VERSION "created by canmatrix"

NS_ :

BS_:

BU_: TCM iBooster HCU CIM SCM Right_Hand_Control Left_Hand_Control GPS VCM IC_2 XM GMRS Radio_CANtool Diagnostic_Tool_Digital_Wrench Information_System_Controller_1 STEERING_CONTROLLER VEHICLE_SECURITY RADIO_Hub ABS Battery_Management_Cntrl_2 Battery_Management_Cntrl_1 Auxiliary_Power_Unit_2 Auxiliary_Power_Unit_1 Electric_Propulsion_Cntrl_Unit_4 Electric_Propulsion_Cntrl_Unit_3 Electric_Propulsion_Cntrl_Unit_2 Electric_Propulsion_Cntrl_Unit_1 ECM IC

BO_ 3221225472 VECTOR__INDEPENDENT_SIG_MSG: 0 Vector__XXX
 SG_ pEPS_SAScalibrated : 0|2@1+ (1,0) [0.0|3.0] "" Vector__XXX
 SG_ pEPS_OpStatus : 0|3@1+ (1,0) [0.0|7.0] "" Vector__XXX
 SG_ pEPS_OpMode : 0|8@1+ (1,0) [0.0|255.0] "" Vector__XXX
 SG_ pEPS_ShaftVelocity : 0|16@1+ (0.1,-3276.5) [-3276.5|3276.5] "deg/s" Vector__XXX
 SG_ pEPS_ShaftPosition : 0|16@1+ (0.1,-3276.5) [-3276.5|3276.5] "deg" Vector__XXX
 SG_ DM_SPN2 : 0|8@1+ (1,0) [0.0|255.0] "" Vector__XXX
 SG_ DM_SPN3 : 0|3@1+ (1,0) [0.0|7.0] "" Vector__XXX
 SG_ DM_SPN1 : 0|8@1+ (1,0) [0.0|255.0] "" Vector__XXX
 SG_ DM_FailureModeIdentifier : 0|5@1+ (1,0) [0.0|0.0] "" Vector__XXX
 SG_ DM_SPNConversionMethod : 0|1@1+ (1,0) [0.0|1.0] "" Vector__XXX
 SG_ DM_OccurenceCount : 0|7@1+ (1,0) [0.0|126.0] "" Vector__XXX

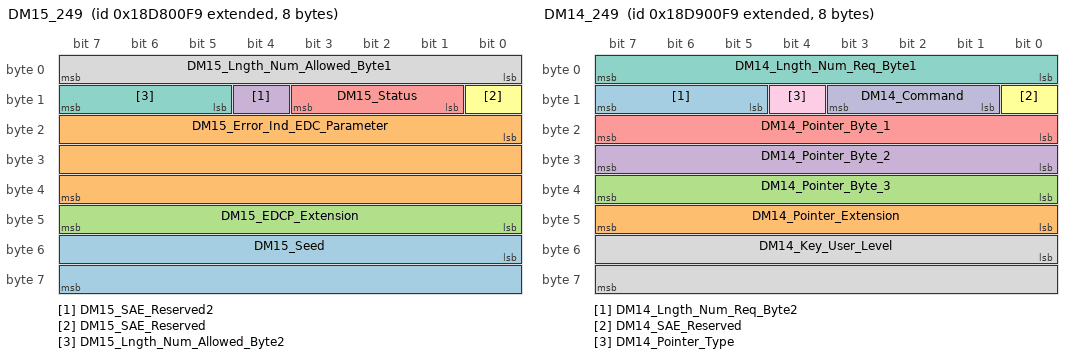
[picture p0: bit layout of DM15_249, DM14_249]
BO_ 2564292857 DM15_249: 8 Diagnostic_Tool_Digital_Wrench
 SG_ DM15_Seed : 48|16@1+ (1,0) [0.0|65535.0] "" Vector__XXX
 SG_ DM15_Error_Ind_EDC_Parameter : 16|24@1+ (1,0) [0.0|16777215.0] "" Vector__XXX
 SG_ DM15_EDCP_Extension : 40|8@1+ (1,0) [0.0|255.0] "" Vector__XXX
 SG_ DM15_SAE_Reserved2 : 12|1@1+ (1,0) [1.0|1.0] "" Vector__XXX
 SG_ DM15_Status : 9|3@1+ (1,0) [0.0|7.0] "" Vector__XXX
 SG_ DM15_SAE_Reserved : 8|1@1+ (1,0) [1.0|1.0] "" Vector__XXX
 SG_ DM15_Lngth_Num_Allowed_Byte2 : 13|3@1+ (1,0) [0.0|7.0] "" Vector__XXX
 SG_ DM15_Lngth_Num_Allowed_Byte1 : 0|8@1+ (1,0) [0.0|255.0] "" Vector__XXX

BO_ 2564358393 DM14_249: 8 Diagnostic_Tool_Digital_Wrench
 SG_ DM14_Lngth_Num_Req_Byte2 : 13|3@1+ (1,0) [0.0|7.0] "" Vector__XXX
 SG_ DM14_Pointer_Extension : 40|8@1+ (1,0) [0.0|255.0] "" Vector__XXX
 SG_ DM14_Pointer_Byte_3 : 32|8@1+ (1,0) [0.0|255.0] "" Vector__XXX
 SG_ DM14_Pointer_Byte_2 : 24|8@1+ (1,0) [0.0|255.0] "" Vector__XXX
 SG_ DM14_Pointer_Byte_1 : 16|8@1+ (1,0) [0.0|255.0] "" Vector__XXX
 SG_ DM14_SAE_Reserved : 8|1@1+ (1,0) [1.0|1.0] "" Vector__XXX
 SG_ DM14_Lngth_Num_Req_Byte1 : 0|8@1+ (1,0) [0.0|255.0] "" Vector__XXX
 SG_ DM14_Key_User_Level : 48|16@1+ (1,0) [0.0|65535.0] "" Vector__XXX
 SG_ DM14_Pointer_Type : 12|1@1+ (1,0) [0.0|1.0] "" Vector__XXX
 SG_ DM14_Command : 9|3@1+ (1,0) [0.0|7.0] "" Vector__XXX

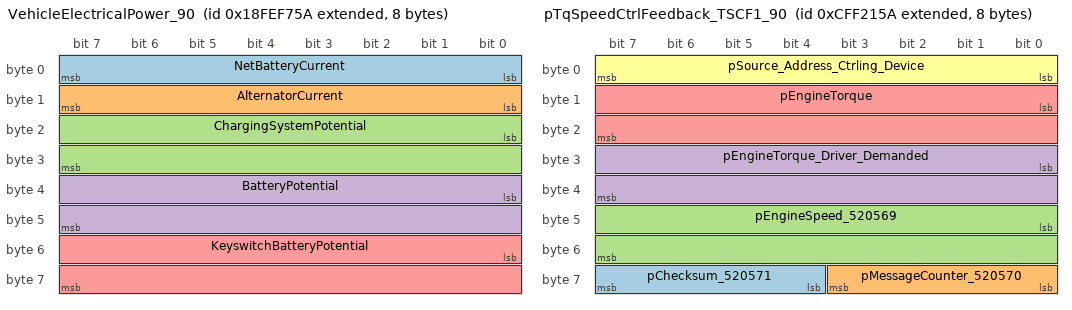
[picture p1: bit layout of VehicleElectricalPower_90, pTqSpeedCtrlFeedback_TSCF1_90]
BO_ 2566846298 VehicleElectricalPower_90: 8 HCU
 SG_ NetBatteryCurrent : 0|8@1+ (1,-125) [-125.0|125.0] "A" Vector__XXX
 SG_ AlternatorCurrent : 8|8@1+ (1,0) [0.0|250.0] "A" Vector__XXX
 SG_ ChargingSystemPotential : 16|16@1+ (0.05,0) [0.0|3212.75] "V" Vector__XXX
 SG_ BatteryPotential : 32|16@1+ (0.05,0) [0.0|3212.75] "V" Vector__XXX
 SG_ KeyswitchBatteryPotential : 48|16@1+ (0.05,0) [0.0|3212.75] "V" Vector__XXX

BO_ 2633984602 pDriveSystemStatus_90: 8 HCU
 SG_ pHeatedGripEnable : 48|2@1+ (1,0) [0.0|3.0] "" Vector__XXX
 SG_ pSideStandStatus : 36|2@1+ (1,0) [0.0|3.0] "" Vector__XXX
 SG_ pTetherSwitchStatus : 46|2@1+ (1,0) [0.0|3.0] "" Vector__XXX
 SG_ pLowFuelIndicatorStatus : 10|2@1+ (1,0) [0.0|3.0] "" Vector__XXX
 SG_ pOperatorNotInOperatingStation : 38|2@1+ (1,0) [0.0|3.0] "" Vector__XXX
 SG_ pParkBrakeIndicatorStatus : 40|3@1+ (1,0) [0.0|7.0] "" Vector__XXX
 SG_ pADCRequested : 34|2@1+ (1,0) [0.0|3.0] "" Vector__XXX
 SG_ pAWDModeRequested : 32|2@1+ (1,0) [0.0|3.0] "" Vector__XXX
 SG_ pRWDModeRequested : 30|2@1+ (1,0) [0.0|3.0] "" Vector__XXX
 SG_ pTurfModeRequested : 28|2@1+ (1,0) [0.0|3.0] "" Vector__XXX
 SG_ pADCStatus : 0|2@1+ (1,0) [0.0|3.0] "" Vector__XXX
 SG_ pTreadleNeutralStatus : 2|2@1+ (1,0) [0.0|3.0] "" Vector__XXX
 SG_ pTreadleReverseStatus : 4|2@1+ (1,0) [0.0|3.0] "" Vector__XXX
 SG_ pSecurityLightStatus : 6|2@1+ (1,0) [0.0|3.0] "" Vector__XXX
 SG_ pHighBeamIndicatorStatus : 8|2@1+ (1,0) [0.0|3.0] "" Vector__XXX
 SG_ pHeatedGripsPercentage : 16|8@1+ (0.4,0) [0.0|100.0] "%" Vector__XXX
 SG_ pCruiseControlSetStatus : 24|2@1+ (1,0) [0.0|3.0] "" Vector__XXX
 SG_ pSeatBeltIndicatorStatus : 12|3@1+ (1,0) [0.0|7.0] "" Vector__XXX

BO_ 2365530458 pTqSpeedCtrlFeedback_TSCF1_90: 8 HCU
 SG_ pChecksum_520571 : 60|4@1+ (1,0) [0.0|15.0] "" Vector__XXX
 SG_ pMessageCounter_520570 : 56|4@1+ (1,0) [0.0|15.0] "" Vector__XXX
 SG_ pEngineSpeed_520569 : 40|16@1+ (1,0) [0.0|64255.0] "rpm" Vector__XXX
 SG_ pEngineTorque_Driver_Demanded : 24|16@1- (0.03125,0) [-400.0|1607.96875] "Nm" Vector__XXX
 SG_ pEngineTorque : 8|16@1- (0.03125,0) [-400.0|1607.96875] "Nm" Vector__XXX
 SG_ pSource_Address_Ctrling_Device : 0|8@1+ (1,0) [0.0|255.0] "Source Address" Vector__XXX

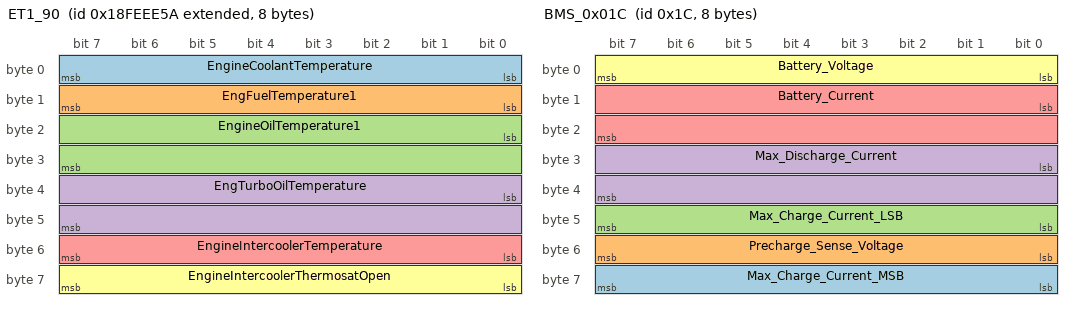
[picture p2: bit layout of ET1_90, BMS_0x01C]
BO_ 2566843994 ET1_90: 8 HCU
 SG_ EngineCoolantTemperature : 0|8@1+ (1,-40) [-40.0|210.0] "°C" Vector__XXX
 SG_ EngFuelTemperature1 : 8|8@1+ (1,-40) [-40.0|210.0] "°C" Vector__XXX
 SG_ EngineOilTemperature1 : 16|16@1+ (0.03125,-273) [-273.0|1734.96875] "°C" Vector__XXX
 SG_ EngTurboOilTemperature : 32|16@1+ (0.03125,-273) [-273.0|1734.96875] "°C" Vector__XXX
 SG_ EngineIntercoolerTemperature : 48|8@1+ (1,-40) [-40.0|210.0] "°C" Vector__XXX
 SG_ EngineIntercoolerThermosatOpen : 56|8@1+ (0.4,0) [0.0|100.0] "%" Vector__XXX

BO_ 2566841690 EngineHoursRevolutions_90: 8 HCU
 SG_ EngTotalHoursOfOper : 0|32@1+ (0.05,0) [0.0|210554060.75] "h" Vector__XXX
 SG_ TotalEngineRevolutions : 32|32@1+ (1000,0) [0.0|4211081215000.0] "r" Vector__XXX

BO_ 2566876762 pVF1_90: 8 HCU
 SG_ pEngineOilPressureStatus : 4|2@1+ (1,0) [0.0|3.0] "" Vector__XXX
 SG_ pHydraulicOilPressureStatus : 2|2@1+ (1,0) [0.0|3.0] "" Vector__XXX
 SG_ pHydraulicOilTempStatus : 0|2@1+ (1,0) [0.0|3.0] "" Vector__XXX

BO_ 2566876672 pVF1_00: 8 ECM
 SG_ pEngineOilPressureStatus : 4|2@1+ (1,0) [0.0|3.0] "" Vector__XXX
 SG_ pHydraulicOilPressureStatus : 2|2@1+ (1,0) [0.0|3.0] "" Vector__XXX
 SG_ pHydraulicOilTempStatus : 0|2@1+ (1,0) [0.0|3.0] "" Vector__XXX

BO_ 27 BMS_0x01B: 8 Battery_Management_Cntrl_1
 SG_ Battery_Relative_SOC : 0|8@1+ (1,0) [0.0|0.0] "%" Vector__XXX
 SG_ BMS_Mode : 8|2@1+ (1,0) [0.0|0.0] "1" Vector__XXX

BO_ 28 BMS_0x01C: 8 Battery_Management_Cntrl_1
 SG_ Max_Charge_Current_MSB : 56|8@1+ (1,0) [0.0|0.0] "A" Vector__XXX
 SG_ Precharge_Sense_Voltage : 48|8@1+ (1,0) [0.0|0.0] "V" Vector__XXX
 SG_ Max_Charge_Current_LSB : 40|8@1+ (1,0) [0.0|0.0] "A" Vector__XXX
 SG_ Max_Discharge_Current : 24|16@1+ (1,0) [0.0|0.0] "A" Vector__XXX
 SG_ Battery_Current : 8|16@1+ (1,-32768) [0.0|0.0] "A" Vector__XXX
 SG_ Battery_Voltage : 0|8@1+ (1,0) [0.0|0.0] "V" Vector__XXX

BO_ 2365553933 pRemoteBrakeControl1_13: 8 iBooster
 SG_ Checksum : 56|8@1+ (1,0) [0.0|255.0] "Count" Vector__XXX
 SG_ MessageCounter : 52|4@1- (1,0) [-8.0|7.0] "Count" Vector__XXX
 SG_ pActualBrakingApplication : 8|8@1+ (0.4,0) [0.0|100.0] "%" Vector__XXX
 SG_ pRequestedBrakingApplication : 0|8@1+ (0.4,0) [0.0|100.0] "%" Vector__XXX

BO_ 2348941059 TC1_03: 8 TCM
 SG_ TrsmRequestedGear_525 : 16|8@1+ (1,0) [0.0|0.0] "" Vector__XXX
 SG_ TrsmGearShiftInhibitReq_681 : 0|2@1+ (1,0) [0.0|0.0] "" Vector__XXX

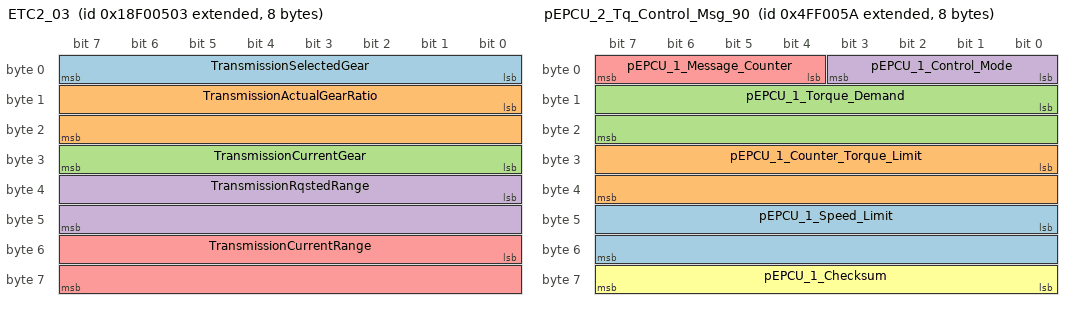
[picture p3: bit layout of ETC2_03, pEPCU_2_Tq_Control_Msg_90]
BO_ 2565866755 ETC2_03: 8 TCM
 SG_ TransmissionSelectedGear : 0|8@1+ (1,-125) [-125.0|125.0] "" Vector__XXX
 SG_ TransmissionActualGearRatio : 8|16@1+ (0.001,0) [0.0|64.255] "" Vector__XXX
 SG_ TransmissionCurrentGear : 24|8@1+ (1,-125) [-125.0|125.0] "" Vector__XXX
 SG_ TransmissionRqstedRange : 32|16@1+ (1,0) [0.0|65535.0] "" Vector__XXX
 SG_ TransmissionCurrentRange : 48|16@1+ (1,0) [0.0|65535.0] "" Vector__XXX

BO_ 2364539395 ElectronicTrsmController1_03: 8 TCM
 SG_ TrsmShiftInProcess_574 : 4|2@1+ (1,0) [0.0|0.0] "" Vector__XXX

BO_ 2566844675 CruiseControlVehSpeed_3: 8 TCM
 SG_ pCruiseCntrlCounter : 50|4@1+ (1,0) [0.0|15.0] "" Vector__XXX
 SG_ TwoSpeedAxleSwitch : 0|2@1+ (1,0) [0.0|3.0] "" Vector__XXX
 SG_ ParkingBrakeSwitch : 2|2@1+ (1,0) [0.0|3.0] "" Vector__XXX
 SG_ Wheel_BasedVehicleSpeed : 8|16@1+ (0.00390625,0) [0.0|251.0] "km/h" Vector__XXX
 SG_ CruiseCtrlActive : 24|2@1+ (1,0) [0.0|3.0] "" Vector__XXX
 SG_ CruiseCtrlEnableSwitch : 26|2@1+ (1,0) [0.0|3.0] "" Vector__XXX
 SG_ BrakeSwitch : 28|2@1+ (1,0) [0.0|3.0] "" Vector__XXX
 SG_ ClutchSwitch : 30|2@1+ (1,0) [0.0|3.0] "" Vector__XXX
 SG_ CruiseCtrlSetSwitch : 32|2@1+ (1,0) [0.0|3.0] "" Vector__XXX
 SG_ CruiseCtrlCoastSwitch : 34|2@1+ (1,0) [0.0|3.0] "" Vector__XXX
 SG_ CruiseCtrlResumeSwitch : 36|2@1+ (1,0) [0.0|3.0] "" Vector__XXX
 SG_ CruiseCtrlAccelerateSwitch : 38|2@1+ (1,0) [0.0|3.0] "" Vector__XXX
 SG_ CruiseCtrlSetSpeed : 40|8@1+ (1,0) [0.0|250.0] "km/h" Vector__XXX
 SG_ pOdometerDriveBit : 6|2@1+ (1,0) [0.0|3.0] "" Vector__XXX
 SG_ CruiseCtrlPauseSw : 4|2@1+ (1,0) [0.0|3.0] "" Vector__XXX
 SG_ pCCChecksum : 56|8@1+ (1,0) [0.0|255.0] "" Vector__XXX
 SG_ pCruiseEnableStatus : 48|4@1+ (1,0) [0.0|15.0] "" Vector__XXX

BO_ 2566841344 SHUTDN_00: 8 ECM
 SG_ Engine_Wait_to_Start_Lamp_1081 : 24|2@1+ (1,0) [0.0|0.0] "" Vector__XXX

BO_ 2231304282 pEPCU_2_Tq_Control_Msg_90: 8 HCU
 SG_ pEPCU_1_Speed_Limit : 40|16@1+ (1,-32768) [-32768.0|31488.0] "rpm" Vector__XXX
 SG_ pEPCU_1_Counter_Torque_Limit : 24|16@1+ (0.1,-3276.8) [-3276.8|3276.7] "Nm" Vector__XXX
 SG_ pEPCU_1_Torque_Demand : 8|16@1+ (0.1,-3276.8) [-3276.8|3276.7] "Nm" Vector__XXX
 SG_ pEPCU_1_Control_Mode : 0|4@1+ (1,0) [0.0|15.0] "" Vector__XXX
 SG_ pEPCU_1_Message_Counter : 4|4@1+ (1,0) [0.0|15.0] "" Vector__XXX
 SG_ pEPCU_1_Checksum : 56|8@1+ (1,0) [0.0|255.0] "" Vector__XXX

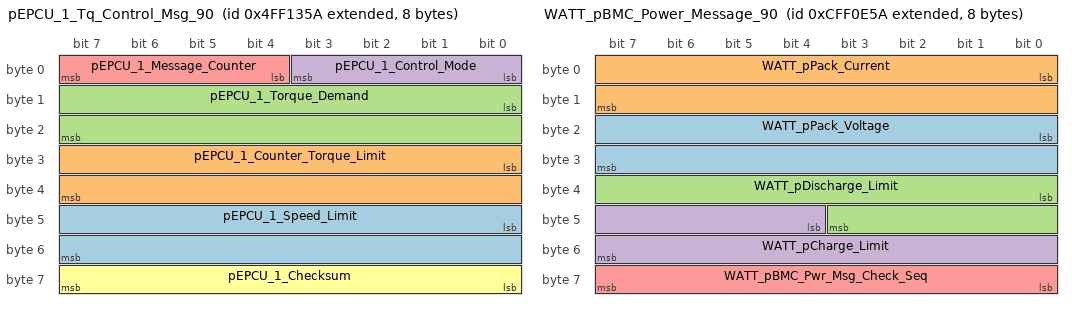
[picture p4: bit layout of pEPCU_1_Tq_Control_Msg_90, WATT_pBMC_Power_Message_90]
BO_ 2231309146 pEPCU_1_Tq_Control_Msg_90: 8 HCU
 SG_ pEPCU_1_Speed_Limit : 40|16@1+ (1,-32768) [-32768.0|31488.0] "rpm" Vector__XXX
 SG_ pEPCU_1_Counter_Torque_Limit : 24|16@1+ (0.1,-3276.8) [-3276.8|3276.7] "Nm" Vector__XXX
 SG_ pEPCU_1_Torque_Demand : 8|16@1+ (0.1,-3276.8) [-3276.8|3276.7] "Nm" Vector__XXX
 SG_ pEPCU_1_Control_Mode : 0|4@1+ (1,0) [0.0|15.0] "" Vector__XXX
 SG_ pEPCU_1_Message_Counter : 4|4@1+ (1,0) [0.0|15.0] "" Vector__XXX
 SG_ pEPCU_1_Checksum : 56|8@1+ (1,0) [0.0|255.0] "" Vector__XXX

BO_ 2365525594 WATT_pBMC_Power_Message_90: 8 HCU
 SG_ WATT_pPack_Voltage : 16|16@1+ (0.05,0) [0.0|3212.75] "V" Vector__XXX
 SG_ WATT_pPack_Current : 0|16@1+ (0.05,-1600) [-1600.0|1612.75] "A" Vector__XXX
 SG_ WATT_pDischarge_Limit : 32|12@1+ (0.5,0) [0.0|2007.5] "A" Vector__XXX
 SG_ WATT_pCharge_Limit : 44|12@1+ (0.5,0) [0.0|2007.5] "A" Vector__XXX
 SG_ WATT_pBMC_Pwr_Msg_Check_Seq : 56|8@1+ (1,0) [0.0|255.0] "" Vector__XXX

BO_ 2348941146 TC1_90: 8 HCU
 SG_ TrsmRequestedGear_525 : 16|8@1+ (1,0) [0.0|0.0] "" Vector__XXX
 SG_ TrsmGearShiftInhibitReq_681 : 0|2@1+ (1,0) [0.0|0.0] "" Vector__XXX

BO_ 2566841434 SHUTDN_90: 8 HCU
 SG_ Engine_Wait_to_Start_Lamp_1081 : 24|2@1+ (1,0) [0.0|0.0] "" Vector__XXX

BO_ 2566885722 RF3_RemoteFeedback3_90: 8 HCU
 SG_ pHybridPowertrainMode : 0|4@1+ (1,0) [0.0|0.0] "" Vector__XXX

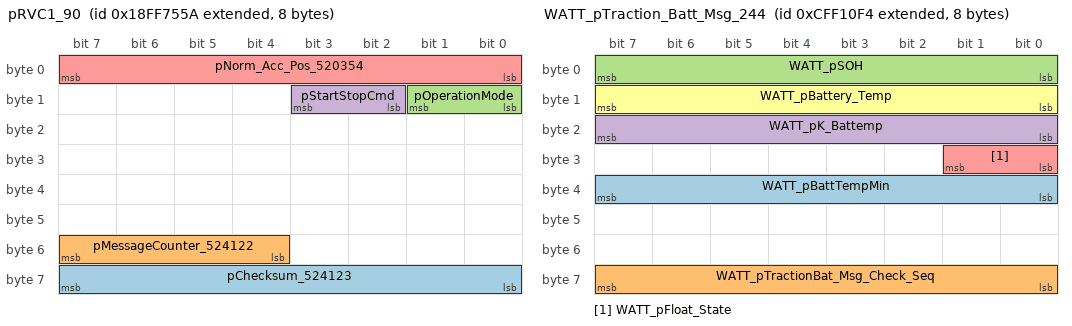
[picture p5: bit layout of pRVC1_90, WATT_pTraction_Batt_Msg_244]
BO_ 2566878554 pRVC1_90: 8 HCU
 SG_ pChecksum_524123 : 56|8@1+ (1,0) [0.0|255.0] "" Vector__XXX
 SG_ pMessageCounter_524122 : 52|4@1+ (1,0) [0.0|15.0] "" Vector__XXX
 SG_ pOperationMode : 8|2@1+ (1,0) [0.0|0.0] "" Vector__XXX
 SG_ pStartStopCmd : 10|2@1+ (1,0) [0.0|3.0] "" Vector__XXX
 SG_ pNorm_Acc_Pos_520354 : 0|8@1+ (0.4,0) [0.0|102.0] "Percent" Vector__XXX

BO_ 2566844762 CruiseControlVehSpeed_90: 8 HCU
 SG_ TwoSpeedAxleSwitch : 0|2@1+ (1,0) [0.0|3.0] "" Vector__XXX
 SG_ ParkingBrakeSwitch : 2|2@1+ (1,0) [0.0|3.0] "" Vector__XXX
 SG_ Wheel_BasedVehicleSpeed : 8|16@1+ (0.00390625,0) [0.0|251.0] "km/h" Vector__XXX
 SG_ CruiseCtrlActive : 24|2@1+ (1,0) [0.0|3.0] "" Vector__XXX
 SG_ CruiseCtrlEnableSwitch : 26|2@1+ (1,0) [0.0|3.0] "" Vector__XXX
 SG_ BrakeSwitch : 28|2@1+ (1,0) [0.0|3.0] "" Vector__XXX
 SG_ ClutchSwitch : 30|2@1+ (1,0) [0.0|3.0] "" Vector__XXX
 SG_ CruiseCtrlSetSwitch : 32|2@1+ (1,0) [0.0|3.0] "" Vector__XXX
 SG_ CruiseCtrlCoastSwitch : 34|2@1+ (1,0) [0.0|3.0] "" Vector__XXX
 SG_ CruiseCtrlResumeSwitch : 36|2@1+ (1,0) [0.0|3.0] "" Vector__XXX
 SG_ CruiseCtrlAccelerateSwitch : 38|2@1+ (1,0) [0.0|3.0] "" Vector__XXX
 SG_ CruiseCtrlSetSpeed : 40|8@1+ (1,0) [0.0|250.0] "km/h" Vector__XXX
 SG_ pOdometerDriveBit : 6|2@1+ (1,0) [0.0|3.0] "" Vector__XXX
 SG_ CruiseCtrlPauseSw : 4|2@1+ (1,0) [0.0|3.0] "" Vector__XXX
 SG_ pCCMessageCounter : 52|4@1+ (1,0) [0.0|15.0] "" Vector__XXX
 SG_ pCCChecksum : 56|8@1+ (1,0) [0.0|255.0] "" Vector__XXX
 SG_ pCruiseEnableStatus : 48|4@1+ (1,0) [0.0|15.0] "" Vector__XXX

BO_ 2566887489 pVehicleLoadInfo1_65: 6 Information_System_Controller_1
 SG_ pRiderWeightRearLeft : 32|8@1+ (1,0) [0.0|250.0] "kg" Vector__XXX
 SG_ pBoxLoadWeight : 48|8@1+ (10,0) [0.0|2400.0] "kg" Vector__XXX
 SG_ pRiderWeightRearRight : 40|8@1+ (1,0) [0.0|250.0] "kg" Vector__XXX
 SG_ pRiderWeightMidRight : 24|8@1+ (1,0) [0.0|250.0] "kg" Vector__XXX
 SG_ pRiderWeightMidLeft : 16|8@1+ (1,0) [0.0|250.0] "kg" Vector__XXX
 SG_ pRiderWeightFrontRight : 8|8@1+ (1,0) [0.0|250.0] "kg" Vector__XXX
 SG_ pRiderWeightFrontLeft : 0|8@1+ (1,0) [0.0|250.0] "kg" Vector__XXX

BO_ 2566853722 pWattMessage_90: 8 HCU
 SG_ pRangeToEmptyEV : 16|16@1+ (0.1,0) [0.0|6425.5] "km" Vector__XXX
 SG_ pEfficiencyEV : 0|16@1+ (0.1,0) [0.0|6425.5] "Wh/km" Vector__XXX

BO_ 2365554060 pRemoteBrakeControl1_140: 8 CIM
 SG_ Checksum : 56|8@1+ (1,0) [0.0|255.0] "Count" Vector__XXX
 SG_ MessageCounter : 52|4@1- (1,0) [-8.0|7.0] "Count" Vector__XXX
 SG_ pActualBrakingApplication : 8|8@1+ (0.4,0) [0.0|100.0] "%" Vector__XXX
 SG_ pRequestedBrakingApplication : 0|8@1+ (0.4,0) [0.0|100.0] "%" Vector__XXX

BO_ 2566877965 pRemoteSteeringControl1_13: 8 iBooster
 SG_ pEPS_CommandedVar2 : 48|16@1+ (0.1,-3276.5) [-3276.5|3276.5] "deg/s" Vector__XXX
 SG_ pEPS_CommandedVar1 : 32|16@1+ (0.1,-3276.5) [-3276.5|3276.5] "deg" Vector__XXX
 SG_ pEPS_OpModeCommanded : 0|8@1+ (1,0) [0.0|255.0] "" Vector__XXX

BO_ 2365526260 WATT_pTraction_Batt_Msg_244: 8 Battery_Management_Cntrl_2
 SG_ WATT_pBattTempMin : 32|8@1+ (1,-40) [-40.0|200.0] "deg C" Vector__XXX
 SG_ WATT_pTractionBat_Msg_Check_Seq : 56|8@1+ (1,0) [0.0|255.0] "" Vector__XXX
 SG_ WATT_pSOH : 0|8@1+ (0.5,0) [0.0|100.0] "%" Vector__XXX
 SG_ WATT_pK_Battemp : 16|8@1+ (0.5,0) [0.0|100.0] "%" Vector__XXX
 SG_ WATT_pFloat_State : 24|2@1+ (1,0) [0.0|3.0] "" Vector__XXX
 SG_ WATT_pBattery_Temp : 8|8@1+ (1,-40) [-40.0|200.0] "C" Vector__XXX

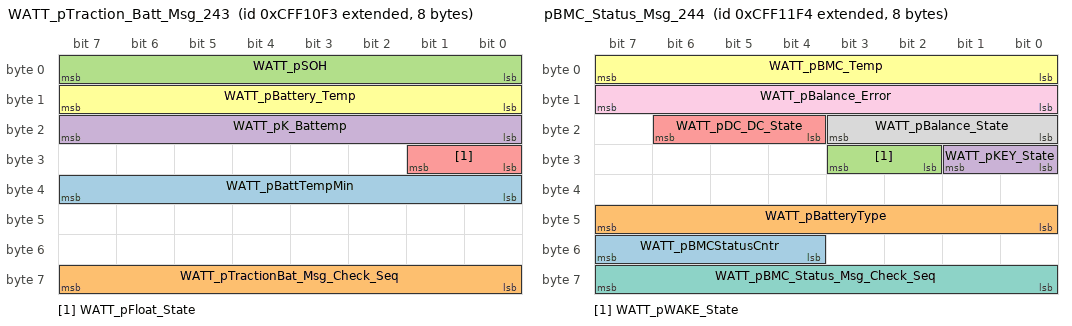
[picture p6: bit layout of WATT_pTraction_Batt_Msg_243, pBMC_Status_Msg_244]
BO_ 2365526259 WATT_pTraction_Batt_Msg_243: 8 Battery_Management_Cntrl_1
 SG_ WATT_pBattTempMin : 32|8@1+ (1,-40) [-40.0|200.0] "deg C" Vector__XXX
 SG_ WATT_pTractionBat_Msg_Check_Seq : 56|8@1+ (1,0) [0.0|255.0] "" Vector__XXX
 SG_ WATT_pSOH : 0|8@1+ (0.5,0) [0.0|100.0] "%" Vector__XXX
 SG_ WATT_pK_Battemp : 16|8@1+ (0.5,0) [0.0|100.0] "%" Vector__XXX
 SG_ WATT_pFloat_State : 24|2@1+ (1,0) [0.0|3.0] "" Vector__XXX
 SG_ WATT_pBattery_Temp : 8|8@1+ (1,-40) [-40.0|200.0] "C" Vector__XXX

BO_ 2365526516 pBMC_Status_Msg_244: 8 Battery_Management_Cntrl_2
 SG_ WATT_pBMCStatusCntr : 52|4@1+ (1,0) [0.0|15.0] "" Vector__XXX
 SG_ WATT_pBatteryType : 40|8@1+ (1,0) [0.0|255.0] "" Vector__XXX
 SG_ WATT_pWAKE_State : 26|2@1+ (1,0) [0.0|3.0] "" Vector__XXX
 SG_ WATT_pKEY_State : 24|2@1+ (1,0) [0.0|3.0] "" Vector__XXX
 SG_ WATT_pDC_DC_State : 20|3@1+ (1,0) [0.0|7.0] "" Vector__XXX
 SG_ WATT_pBMC_Temp : 0|8@1+ (1,-40) [-40.0|200.0] "C" Vector__XXX
 SG_ WATT_pBMC_Status_Msg_Check_Seq : 56|8@1+ (1,0) [0.0|255.0] "" Vector__XXX
 SG_ WATT_pBalance_State : 16|4@1+ (1,0) [0.0|15.0] "" Vector__XXX
 SG_ WATT_pBalance_Error : 8|8@1+ (0.5,-6.4) [-6.4|6.1] "%" Vector__XXX

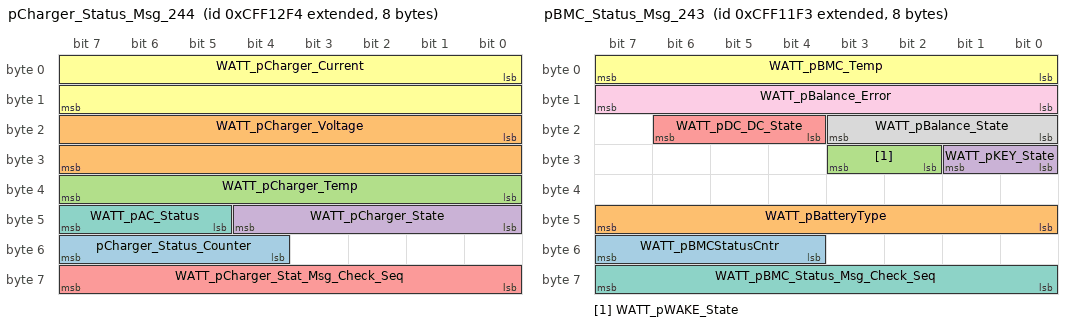
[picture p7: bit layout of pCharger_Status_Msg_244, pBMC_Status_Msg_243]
BO_ 2365526772 pCharger_Status_Msg_244: 8 Battery_Management_Cntrl_2
 SG_ pCharger_Status_Counter : 52|4@1+ (1,0) [0.0|15.0] "" Vector__XXX
 SG_ WATT_pCharger_Voltage : 16|16@1+ (0.05,0) [0.0|3212.75] "V" Vector__XXX
 SG_ WATT_pCharger_Temp : 32|8@1+ (1,-40) [-40.0|200.0] "C" Vector__XXX
 SG_ WATT_pCharger_State : 40|5@1+ (1,0) [0.0|31.0] "" Vector__XXX
 SG_ WATT_pCharger_Stat_Msg_Check_Seq : 56|8@1+ (1,0) [0.0|255.0] "" Vector__XXX
 SG_ WATT_pCharger_Current : 0|16@1+ (0.05,-1600) [-1600.0|1612.75] "A" Vector__XXX
 SG_ WATT_pAC_Status : 45|3@1+ (1,0) [0.0|7.0] "" Vector__XXX

BO_ 2365526004 pEnergy_Msg_244: 8 Battery_Management_Cntrl_2
 SG_ WATT_pWh_In_Since_Key : 24|32@1+ (6.10352e-05,-131072) [-131072.0|126000.0] "Wh" Vector__XXX
 SG_ WATT_pSOC : 0|8@1+ (0.5,0) [0.0|100.0] "%" Vector__XXX
 SG_ WATT_pEnergy_Msg_Check_Seq : 56|8@1+ (1,0) [0.0|255.0] "" Vector__XXX
 SG_ WATT_pAvailable_Wh : 8|16@1+ (4,0) [0.0|257020.0] "Wh" Vector__XXX

BO_ 2365526515 pBMC_Status_Msg_243: 8 Battery_Management_Cntrl_1
 SG_ WATT_pBMCStatusCntr : 52|4@1+ (1,0) [0.0|15.0] "" Vector__XXX
 SG_ WATT_pBatteryType : 40|8@1+ (1,0) [0.0|255.0] "" Vector__XXX
 SG_ WATT_pWAKE_State : 26|2@1+ (1,0) [0.0|3.0] "" Vector__XXX
 SG_ WATT_pKEY_State : 24|2@1+ (1,0) [0.0|3.0] "" Vector__XXX
 SG_ WATT_pDC_DC_State : 20|3@1+ (1,0) [0.0|7.0] "" Vector__XXX
 SG_ WATT_pBMC_Temp : 0|8@1+ (1,-40) [-40.0|200.0] "C" Vector__XXX
 SG_ WATT_pBMC_Status_Msg_Check_Seq : 56|8@1+ (1,0) [0.0|255.0] "" Vector__XXX
 SG_ WATT_pBalance_State : 16|4@1+ (1,0) [0.0|15.0] "" Vector__XXX
 SG_ WATT_pBalance_Error : 8|8@1+ (0.5,-6.4) [-6.4|6.1] "%" Vector__XXX

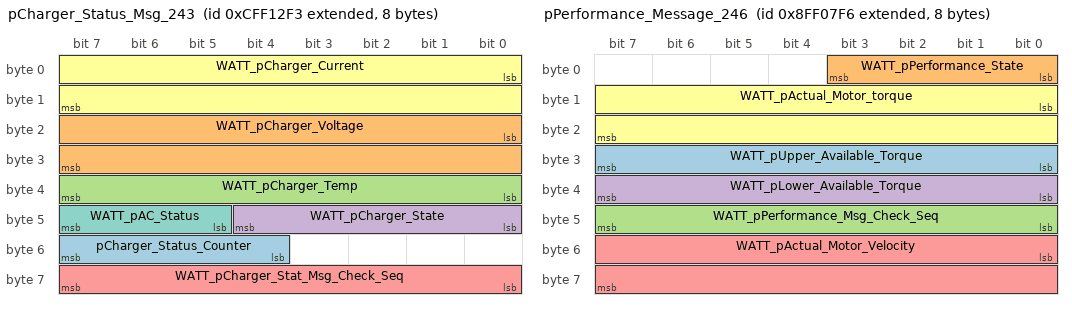
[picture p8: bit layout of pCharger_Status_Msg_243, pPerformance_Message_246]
BO_ 2365526771 pCharger_Status_Msg_243: 8 Battery_Management_Cntrl_1
 SG_ pCharger_Status_Counter : 52|4@1+ (1,0) [0.0|15.0] "" Vector__XXX
 SG_ WATT_pCharger_Voltage : 16|16@1+ (0.05,0) [0.0|3212.75] "V" Vector__XXX
 SG_ WATT_pCharger_Temp : 32|8@1+ (1,-40) [-40.0|200.0] "C" Vector__XXX
 SG_ WATT_pCharger_State : 40|5@1+ (1,0) [0.0|31.0] "" Vector__XXX
 SG_ WATT_pCharger_Stat_Msg_Check_Seq : 56|8@1+ (1,0) [0.0|255.0] "" Vector__XXX
 SG_ WATT_pCharger_Current : 0|16@1+ (0.05,-1600) [-1600.0|1612.75] "A" Vector__XXX
 SG_ WATT_pAC_Status : 45|3@1+ (1,0) [0.0|7.0] "" Vector__XXX

BO_ 2365526003 pEnergy_Msg_243: 8 Battery_Management_Cntrl_1
 SG_ WATT_pWh_In_Since_Key : 24|32@1+ (6.10352e-05,-131072) [-131072.0|126000.0] "Wh" Vector__XXX
 SG_ WATT_pSOC : 0|8@1+ (0.5,0) [0.0|100.0] "%" Vector__XXX
 SG_ WATT_pEnergy_Msg_Check_Seq : 56|8@1+ (1,0) [0.0|255.0] "" Vector__XXX
 SG_ WATT_pAvailable_Wh : 8|16@1+ (4,0) [0.0|257020.0] "Wh" Vector__XXX

BO_ 2298415094 pPerformance_Message_246: 8 Auxiliary_Power_Unit_2
 SG_ WATT_pUpper_Available_Torque : 24|8@1+ (2.5,-312.5) [-312.5|312.5] "Nm" Vector__XXX
 SG_ WATT_pPerformance_State : 0|4@1+ (1,0) [0.0|15.0] "" Vector__XXX
 SG_ WATT_pPerformance_Msg_Check_Seq : 40|8@1+ (1,0) [0.0|255.0] "" Vector__XXX
 SG_ WATT_pLower_Available_Torque : 32|8@1+ (2.5,-312.5) [-312.5|312.5] "Nm" Vector__XXX
 SG_ WATT_pActual_Motor_Velocity : 48|16@1+ (1,-32768) [-32768.0|31488.0] "RPM" Vector__XXX
 SG_ WATT_pActual_Motor_torque : 8|16@1+ (0.1,-3276.8) [-3276.8|3148.7] "Nm" Vector__XXX

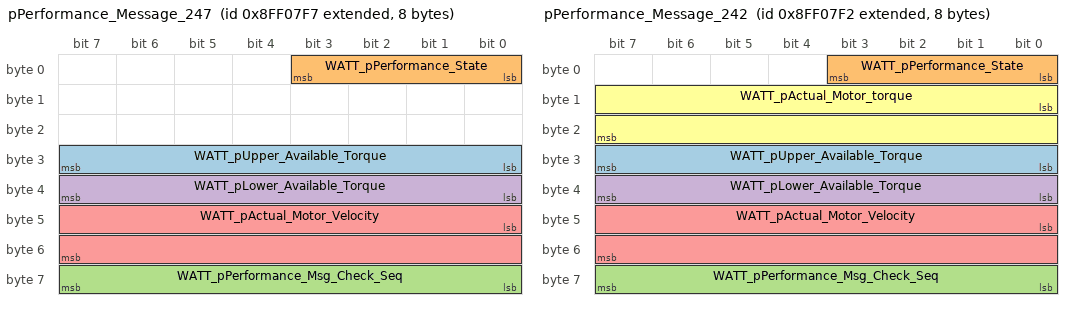
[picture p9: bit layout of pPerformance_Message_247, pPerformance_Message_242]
BO_ 2298415095 pPerformance_Message_247: 8 Auxiliary_Power_Unit_1
 SG_ WATT_pUpper_Available_Torque : 24|8@1+ (2.5,-312.5) [-312.5|312.5] "Nm" Vector__XXX
 SG_ WATT_pPerformance_State : 0|4@1+ (1,0) [0.0|15.0] "" Vector__XXX
 SG_ WATT_pPerformance_Msg_Check_Seq : 56|8@1+ (1,0) [0.0|255.0] "" Vector__XXX
 SG_ WATT_pLower_Available_Torque : 32|8@1+ (2.5,-312.5) [-312.5|312.5] "Nm" Vector__XXX
 SG_ WATT_pActual_Motor_Velocity : 40|16@1+ (1,-32768) [-32768.0|31488.0] "RPM" Vector__XXX

BO_ 2298415090 pPerformance_Message_242: 8 Electric_Propulsion_Cntrl_Unit_4
 SG_ WATT_pUpper_Available_Torque : 24|8@1+ (2.5,-312.5) [-312.5|312.5] "Nm" Vector__XXX
 SG_ WATT_pPerformance_State : 0|4@1+ (1,0) [0.0|15.0] "" Vector__XXX
 SG_ WATT_pPerformance_Msg_Check_Seq : 56|8@1+ (1,0) [0.0|255.0] "" Vector__XXX
 SG_ WATT_pLower_Available_Torque : 32|8@1+ (2.5,-312.5) [-312.5|312.5] "Nm" Vector__XXX
 SG_ WATT_pActual_Motor_Velocity : 40|16@1+ (1,-32768) [-32768.0|31488.0] "RPM" Vector__XXX
 SG_ WATT_pActual_Motor_torque : 8|16@1+ (0.1,-3276.8) [-3276.8|3148.7] "Nm" Vector__XXX

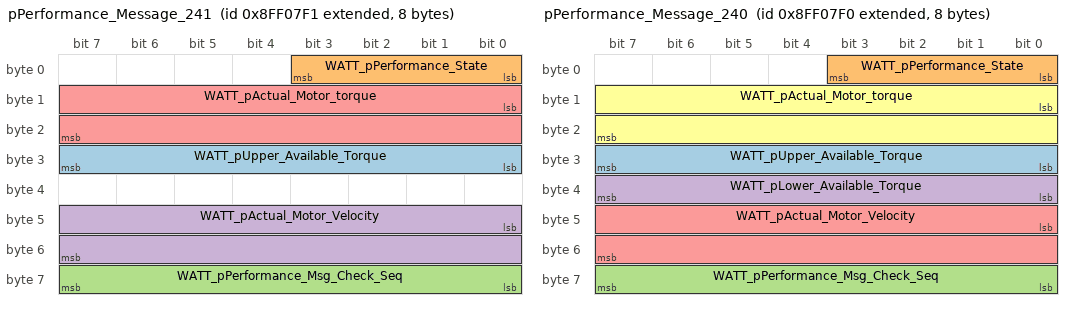
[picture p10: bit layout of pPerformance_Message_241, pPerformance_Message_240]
BO_ 2298415089 pPerformance_Message_241: 8 Electric_Propulsion_Cntrl_Unit_3
 SG_ WATT_pUpper_Available_Torque : 24|8@1+ (2.5,-312.5) [-312.5|312.5] "Nm" Vector__XXX
 SG_ WATT_pPerformance_State : 0|4@1+ (1,0) [0.0|15.0] "" Vector__XXX
 SG_ WATT_pPerformance_Msg_Check_Seq : 56|8@1+ (1,0) [0.0|255.0] "" Vector__XXX
 SG_ WATT_pActual_Motor_Velocity : 40|16@1+ (1,-32768) [-32768.0|31488.0] "RPM" Vector__XXX
 SG_ WATT_pActual_Motor_torque : 8|16@1+ (0.1,-3276.8) [-3276.8|3148.7] "Nm" Vector__XXX

BO_ 2298415088 pPerformance_Message_240: 8 Electric_Propulsion_Cntrl_Unit_2
 SG_ WATT_pUpper_Available_Torque : 24|8@1+ (2.5,-312.5) [-312.5|312.5] "Nm" Vector__XXX
 SG_ WATT_pPerformance_State : 0|4@1+ (1,0) [0.0|15.0] "" Vector__XXX
 SG_ WATT_pPerformance_Msg_Check_Seq : 56|8@1+ (1,0) [0.0|255.0] "" Vector__XXX
 SG_ WATT_pLower_Available_Torque : 32|8@1+ (2.5,-312.5) [-312.5|312.5] "Nm" Vector__XXX
 SG_ WATT_pActual_Motor_Velocity : 40|16@1+ (1,-32768) [-32768.0|31488.0] "RPM" Vector__XXX
 SG_ WATT_pActual_Motor_torque : 8|16@1+ (0.1,-3276.8) [-3276.8|3148.7] "Nm" Vector__XXX

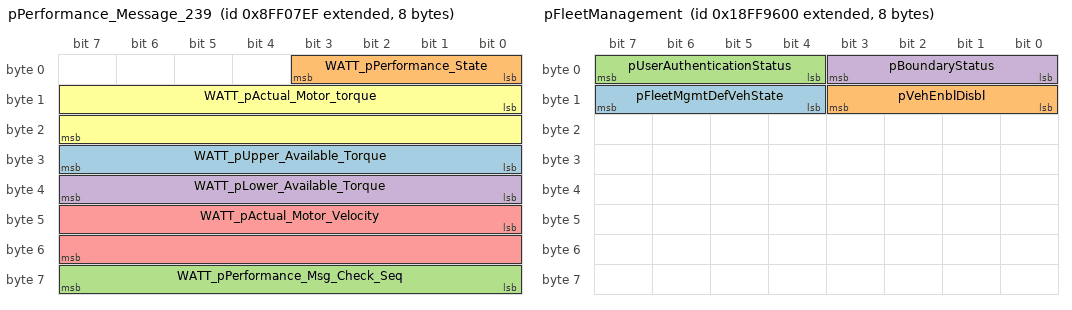
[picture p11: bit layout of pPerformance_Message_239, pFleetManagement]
BO_ 2298415087 pPerformance_Message_239: 8 Electric_Propulsion_Cntrl_Unit_1
 SG_ WATT_pUpper_Available_Torque : 24|8@1+ (2.5,-312.5) [-312.5|312.5] "Nm" Vector__XXX
 SG_ WATT_pPerformance_State : 0|4@1+ (1,0) [0.0|15.0] "" Vector__XXX
 SG_ WATT_pPerformance_Msg_Check_Seq : 56|8@1+ (1,0) [0.0|255.0] "" Vector__XXX
 SG_ WATT_pLower_Available_Torque : 32|8@1+ (2.5,-312.5) [-312.5|312.5] "Nm" Vector__XXX
 SG_ WATT_pActual_Motor_Velocity : 40|16@1+ (1,-32768) [-32768.0|31488.0] "RPM" Vector__XXX
 SG_ WATT_pActual_Motor_torque : 8|16@1+ (0.1,-3276.8) [-3276.8|3148.7] "Nm" Vector__XXX

BO_ 2566834735 DM1_47: 22 SCM
 SG_ DM_FlashRedStopLamp : 12|2@1+ (1,0) [0.0|3.0] "" Vector__XXX
 SG_ DM_FlashProtectLamp : 8|2@1+ (1,0) [0.0|3.0] "" Vector__XXX
 SG_ DM_FlashMalfuncIndicatorLamp : 14|2@1+ (1,0) [0.0|3.0] "" Vector__XXX
 SG_ DM_FlashAmberWarningLamp : 10|2@1+ (1,0) [0.0|3.0] "" Vector__XXX
 SG_ DTC5 : 144|32@1+ (1,0) [0.0|4294967295.0] "" Vector__XXX
 SG_ DTC4 : 112|32@1+ (1,0) [0.0|4294967295.0] "" Vector__XXX
 SG_ DTC3 : 80|32@1+ (1,0) [0.0|4294967295.0] "" Vector__XXX
 SG_ DTC2 : 48|32@1+ (1,0) [0.0|4294967295.0] "" Vector__XXX
 SG_ DTC1 : 16|32@1+ (1,0) [0.0|4294967295.0] "" Vector__XXX
 SG_ DM_ProtectLampStatus : 0|2@1+ (1,0) [0.0|3.0] "" Vector__XXX
 SG_ DM_RedStopLampState : 4|2@1+ (1,0) [0.0|3.0] "" Vector__XXX
 SG_ DM_AmberWrningLmpStatus : 2|2@1+ (1,0) [0.0|3.0] "" Vector__XXX
 SG_ DM_MalfuncnIndicatorLampStatus : 6|2@1+ (1,0) [0.0|3.0] "" Vector__XXX

BO_ 2566903040 DL_DiscreteIO_0: 8 ECM
 SG_ DL_BoostBypassOutputActive : 54|1@1+ (1,0) [0.0|1.0] "" Vector__XXX
 SG_ DL_CruiseLampOutputActive : 53|1@1+ (1,0) [0.0|1.0] "" Vector__XXX
 SG_ DL_FuelSelectOutput2Active : 52|1@1+ (1,0) [0.0|1.0] "" Vector__XXX
 SG_ DL_FuelSelectOutput1Active : 51|1@1+ (1,0) [0.0|1.0] "" Vector__XXX
 SG_ DL_OemOutput4Active : 50|1@1+ (1,0) [0.0|1.0] "" Vector__XXX
 SG_ DL_OemOutput3Active : 49|1@1+ (1,0) [0.0|1.0] "" Vector__XXX
 SG_ DL_OemOutput2Active : 48|1@1+ (1,0) [0.0|1.0] "" Vector__XXX
 SG_ DL_OemOutput1Active : 47|1@1+ (1,0) [0.0|1.0] "" Vector__XXX
 SG_ DL_FuelPump2RelayOutputActive : 46|1@1+ (1,0) [0.0|1.0] "" Vector__XXX
 SG_ DL_IntercoolerOutputActive : 45|1@1+ (1,0) [0.0|1.0] "" Vector__XXX
 SG_ DL_ClutchSwitchInputActive : 18|1@1+ (1,0) [0.0|1.0] "" Vector__XXX
 SG_ DL_BrakeSwitchInputActive : 17|1@1+ (1,0) [0.0|1.0] "" Vector__XXX
 SG_ DL_ReverseSwitchInputActive : 16|1@1+ (1,0) [0.0|1.0] "" Vector__XXX
 SG_ DL_CrankReqInput : 0|1@1+ (1,0) [0.0|1.0] "" Vector__XXX
 SG_ DL_LowOilLevelInput : 1|1@1+ (1,0) [0.0|1.0] "" Vector__XXX
 SG_ DL_LoadAnticipate1Input : 2|1@1+ (1,0) [0.0|1.0] "" Vector__XXX
 SG_ DL_LoadAnticipate2Input : 3|1@1+ (1,0) [0.0|1.0] "" Vector__XXX
 SG_ DL_CruiseDecelInputActive : 10|1@1+ (1,0) [0.0|1.0] "" Vector__XXX
 SG_ DL_CruiseAccelInputActive : 11|1@1+ (1,0) [0.0|1.0] "" Vector__XXX
 SG_ DL_PowertrainRelayOutput : 32|1@1+ (1,0) [0.0|1.0] "" Vector__XXX
 SG_ DL_StarterRelayOutput : 33|1@1+ (1,0) [0.0|1.0] "" Vector__XXX
 SG_ DL_FuelPump1RelayOutput : 44|1@1+ (1,0) [0.0|1.0] "" Vector__XXX
 SG_ DL_SlowmodeInputActive : 5|1@1+ (1,0) [0.0|1.0] "" Vector__XXX
 SG_ DL_SlowModeLampOutput : 41|1@1+ (1,0) [0.0|1.0] "" Vector__XXX
 SG_ DL_GovCruiseSync : 9|1@1+ (1,0) [0.0|1.0] "" Vector__XXX
 SG_ DL_DiscreteLowOilPressInput : 7|1@1+ (1,0) [0.0|0.0] "" Vector__XXX
 SG_ DL_MILOutput : 34|1@1+ (1,0) [0.0|1.0] "" Vector__XXX

BO_ 2566854912 pTurboDiesel: 8 ECM
 SG_ DL_GPAPositionSensor1 : 16|16@1+ (0.001,0) [0.0|65.535] "Volts" Vector__XXX
 SG_ DL_GPAPosition : 8|8@1+ (0.4,0) [0.0|102.0] "%" Vector__XXX
 SG_ DL_GPAAdaptationOffsetSensor : 32|8@1+ (0.02,0) [0.0|5.1] "Volts" Vector__XXX
 SG_ DL_GPAAdaptationOffset : 40|8@1+ (0.4,0) [0.0|102.0] "%" Vector__XXX
 SG_ DL_AbsoluteGPAPercent : 0|8@1+ (0.4,0) [0.0|102.0] "%" Vector__XXX

BO_ 2566855680 pFanControl: 8 ECM
 SG_ pRqstdPerFan1DutyCycle : 8|8@1+ (0.4,0) [0.0|100.0] "%" Vector__XXX
 SG_ pFan1DirectionCmd : 0|2@1+ (1,0) [0.0|4.0] "" Vector__XXX

BO_ 2566886912 pFleetManagement: 8 ECM
 SG_ pFleetMgmtDefVehState : 12|4@1+ (1,0) [0.0|15.0] "" Vector__XXX
 SG_ pVehEnblDisbl : 8|4@1+ (1,0) [0.0|15.0] "" Vector__XXX
 SG_ pUserAuthenticationStatus : 4|4@1+ (1,0) [0.0|15.0] "" Vector__XXX
 SG_ pBoundaryStatus : 0|4@1+ (1,0) [0.0|15.0] "" Vector__XXX

BO_ 2566886400 LogData: 8 ECM
 SG_ EngineCyldr2IngnitionTmg : 24|8@1+ (1,-128) [-128.0|122.0] "deg" Vector__XXX
 SG_ EngineCyldr1IgnitionTmg : 16|8@1+ (1,-128) [-128.0|122.0] "deg" Vector__XXX
 SG_ DesiredLambda : 8|8@1+ (0.0078125,0) [0.0|1.953125] "" Vector__XXX
 SG_ HighRngEngPerLoad : 0|8@1+ (2,0) [0.0|500.0] "%" Vector__XXX

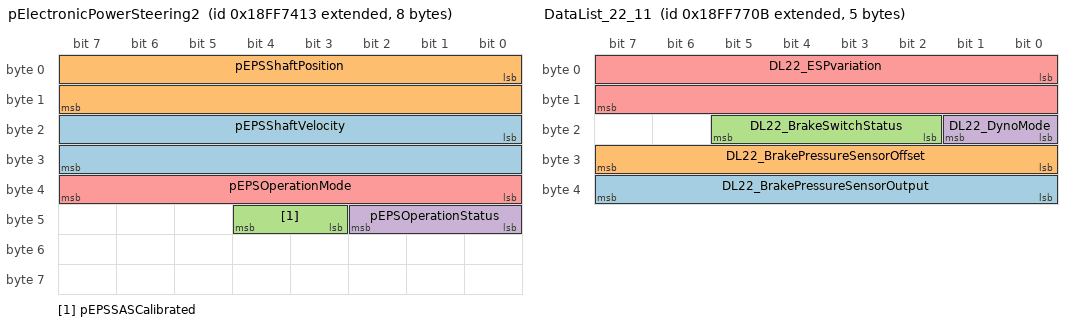
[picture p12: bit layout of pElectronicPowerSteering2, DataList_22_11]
BO_ 2566878227 pElectronicPowerSteering2: 8 STEERING_CONTROLLER
 SG_ pEPSShaftVelocity : 16|16@1+ (0.1,-3276.5) [-3276.5|3276.5] "degrees per second" Vector__XXX
 SG_ pEPSShaftPosition : 0|16@1+ (0.1,-3276.5) [-3276.5|3276.5] "degrees" Vector__XXX
 SG_ pEPSSASCalibrated : 43|2@1+ (1,0) [0.0|3.0] "" Vector__XXX
 SG_ pEPSOperationStatus : 40|3@1+ (1,0) [0.0|7.0] "" Vector__XXX
 SG_ pEPSOperationMode : 32|8@1+ (1,0) [0.0|255.0] "" Vector__XXX

BO_ 2566878987 DataList_22_11: 5 ABS
 SG_ DL22_BrakePressureSensorOutput : 32|8@1- (100,5000) [5000.0|30500.0] "kPa" Vector__XXX
 SG_ DL22_BrakePressureSensorOffset : 24|8@1+ (100,5000) [5000.0|30500.0] "kPa" Vector__XXX
 SG_ DL22_BrakeSwitchStatus : 18|4@1+ (1,0) [0.0|15.0] "" Vector__XXX
 SG_ DL22_DynoMode : 16|2@1+ (1,0) [0.0|3.0] "Active/Inactive" Vector__XXX
 SG_ DL22_ESPvariation : 0|16@1+ (1,0) [0.0|255.0] "Hex" Vector__XXX

BO_ 2365553931 pRemoteBrakeControl1: 8 ABS
 SG_ Checksum : 56|8@1+ (1,0) [0.0|255.0] "Count" Vector__XXX
 SG_ MessageCounter : 52|4@1- (1,0) [-8.0|7.0] "Count" Vector__XXX
 SG_ pActualBrakingApplication : 8|8@1+ (0.4,0) [0.0|100.0] "%" Vector__XXX
 SG_ pRequestedBrakingApplication : 0|8@1+ (0.4,0) [0.0|100.0] "%" Vector__XXX

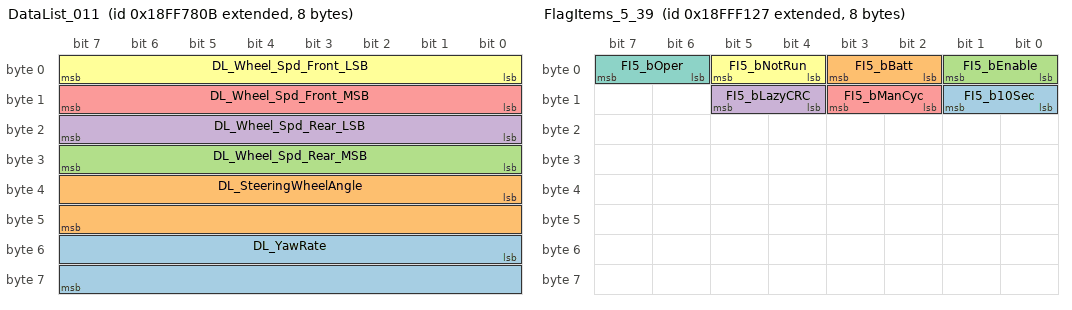
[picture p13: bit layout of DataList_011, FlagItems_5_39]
BO_ 2566879243 DataList_011: 8 ABS
 SG_ DL_YawRate : 48|16@1+ (0.00012207,-3.92) [-3.92|4.0798779296875] "rad/s" Vector__XXX
 SG_ DL_SteeringWheelAngle : 32|16@1+ (0.000976562,-31.374) [-31.374|32.6250234375] "rad" Vector__XXX
 SG_ DL_Wheel_Spd_Rear_MSB : 24|8@1+ (0.00390625,0) [0.0|0.99609375] "kph" Vector__XXX
 SG_ DL_Wheel_Spd_Rear_LSB : 16|8@1+ (0.00390625,0) [0.0|0.99609375] "kph" Vector__XXX
 SG_ DL_Wheel_Spd_Front_MSB : 8|8@1+ (0.00390625,0) [0.0|0.99609375] "kph" Vector__XXX
 SG_ DL_Wheel_Spd_Front_LSB : 0|8@1+ (0.00390625,0) [0.0|0.99609375] "kph" Vector__XXX

BO_ 2566907687 DataList_20_39: 8 VCM
 SG_ DL20_KeyFobBatteryVoltage : 0|8@1+ (0.1,0) [0.0|25.5] "Volts" Vector__XXX
 SG_ DL20_LeanAngle : 8|8@1+ (1,-125) [-125.0|130.0] "Degrees" Vector__XXX

BO_ 2566907943 DataList_19_39: 8 VCM
 SG_ DL19_TirePressure_Rear_Left_Only : 16|8@1+ (4,0) [0.0|1020.0] "kPa" Vector__XXX
 SG_ DL19_TirePressureFront_Left_Only : 0|8@1+ (4,0) [0.0|1020.0] "kPa" Vector__XXX
 SG_ DL19_TirePressureFrontRight : 8|8@1+ (4,0) [0.0|1020.0] "kPa" Vector__XXX
 SG_ DL19_TirePressureRearRight : 24|8@1+ (4,0) [0.0|1020.0] "kPa" Vector__XXX

BO_ 2566910247 FlagItems_5_39: 8 VCM
 SG_ FI5_b10Sec : 8|2@1+ (1,0) [0.0|3.0] "Binary" Vector__XXX
 SG_ FI5_bBatt : 2|2@1+ (1,0) [0.0|3.0] "Binary" Vector__XXX
 SG_ FI5_bEnable : 0|2@1+ (1,0) [0.0|3.0] "Binary" Vector__XXX
 SG_ FI5_bLazyCRC : 12|2@1+ (1,0) [0.0|3.0] "Binary" Vector__XXX
 SG_ FI5_bManCyc : 10|2@1+ (1,0) [0.0|3.0] "Binary" Vector__XXX
 SG_ FI5_bNotRun : 4|2@1+ (1,0) [0.0|3.0] "Binary" Vector__XXX
 SG_ FI5_bOper : 6|2@1+ (1,0) [0.0|3.0] "Binary" Vector__XXX

BO_ 2566910503 FlagItems_4_39: 8 VCM
 SG_ FI4_SeatbeltSw : 60|2@1+ (1,0) [0.0|3.0] "" Vector__XXX
 SG_ FI4_pSideStandSw : 52|2@1+ (1,0) [0.0|3.0] "" Vector__XXX
 SG_ FI4_DrvlnMomentaryRight : 58|2@1+ (1,0) [0.0|3.0] "" Vector__XXX
 SG_ FI4_DrvlnMomentaryLeft : 56|2@1+ (1,0) [0.0|3.0] "" Vector__XXX
 SG_ FI4_BrakeLightOutput : 30|2@1+ (1,0) [0.0|3.0] "" Vector__XXX
 SG_ FI4_FogLightInput : 4|2@1+ (1,0) [0.0|3.0] "" Vector__XXX
 SG_ FI4_HazardLightOutput : 26|2@1+ (1,0) [0.0|3.0] "" Vector__XXX
 SG_ FI4_HazardSWInput : 0|2@1+ (1,0) [0.0|3.0] "" Vector__XXX
 SG_ FI4_HeatGripDecSW : 46|2@1+ (1,0) [0.0|3.0] "" Vector__XXX
 SG_ FI4_HeatGripIncSW : 44|2@1+ (1,0) [0.0|3.0] "" Vector__XXX
 SG_ FI4_HighBeamOutput : 8|2@1+ (1,0) [0.0|3.0] "" Vector__XXX
 SG_ FI4_HornInput : 6|2@1+ (1,0) [0.0|3.0] "" Vector__XXX
 SG_ FI4_HornOutput : 24|2@1+ (1,0) [0.0|3.0] "" Vector__XXX
 SG_ FI4_LeftFogLightOutput : 12|2@1+ (1,0) [0.0|3.0] "" Vector__XXX
 SG_ FI4_LFTurnSignalOutput : 32|2@1+ (1,0) [0.0|3.0] "" Vector__XXX
 SG_ FI4_LockInput : 18|2@1+ (1,0) [0.0|3.0] "" Vector__XXX
 SG_ FI4_LowBeamOutput : 10|2@1+ (1,0) [0.0|3.0] "" Vector__XXX
 SG_ FI4_LowHighBeamInput : 2|2@1+ (1,0) [0.0|3.0] "" Vector__XXX
 SG_ FI4_LRTurnSignalOutput : 36|2@1+ (1,0) [0.0|3.0] "" Vector__XXX
 SG_ FI4_pOperatorButton1 : 48|2@1+ (1,0) [0.0|3.0] "" Vector__XXX
 SG_ FI4_RFTurnSignalOutput : 34|2@1+ (1,0) [0.0|3.0] "" Vector__XXX
 SG_ FI4_RightFogLightOutput : 14|2@1+ (1,0) [0.0|3.0] "" Vector__XXX
 SG_ FI4_RRTurnSignalOutput : 38|2@1+ (1,0) [0.0|3.0] "" Vector__XXX
 SG_ FI4_SecondaryAirValveCmd : 42|2@1+ (1,0) [0.0|3.0] "" Vector__XXX
 SG_ FI4_SecondaryAirValveOut : 40|2@1+ (1,0) [0.0|3.0] "" Vector__XXX
 SG_ FI4_TailLightOutput : 28|2@1+ (1,0) [0.0|3.0] "" Vector__XXX
 SG_ FI4_UnlockInput : 16|2@1+ (1,0) [0.0|3.0] "" Vector__XXX
 SG_ FI4_WindshieldSWDownInput : 22|2@1+ (1,0) [0.0|3.0] "" Vector__XXX
 SG_ FI4_WindshieldSWUpInput : 20|2@1+ (1,0) [0.0|3.0] "" Vector__XXX
 SG_ FI4_pOperatorButton2 : 50|2@1+ (1,0) [0.0|3.0] "" Vector__XXX

BO_ 2566910759 FlagItems_3_39: 8 VCM
 SG_ FI3_OilPressSwIn : 62|2@1+ (1,0) [0.0|3.0] "" Vector__XXX
 SG_ FI3_BrkSw2In : 60|2@1+ (1,0) [0.0|3.0] "" Vector__XXX
 SG_ FI3_CruiseCtrlResumeOut : 54|2@1+ (1,0) [0.0|3.0] "" Vector__XXX
 SG_ FI3_CruiseCtrlResumeIn : 56|2@1+ (1,0) [0.0|3.0] "" Vector__XXX
 SG_ FI3_CruiseCtrlCancelIn : 58|2@1+ (1,0) [0.0|3.0] "" Vector__XXX
 SG_ FI3_TetherSwStatus : 38|2@1+ (1,0) [0.0|3.0] "" Vector__XXX
 SG_ FI3_DriveMode1Input : 0|2@1+ (1,0) [0.0|3.0] "" Vector__XXX
 SG_ FI3_DriveMode2Input : 2|2@1+ (1,0) [0.0|3.0] "" Vector__XXX
 SG_ FI3_DriveMode3Input : 4|2@1+ (1,0) [0.0|3.0] "" Vector__XXX
 SG_ FI3_DriverMode4Input : 6|2@1+ (1,0) [0.0|3.0] "" Vector__XXX
 SG_ FI3_DriverMode1Output : 8|2@1+ (1,0) [0.0|3.0] "" Vector__XXX
 SG_ FI3_DriverMode2Output : 10|2@1+ (1,0) [0.0|3.0] "" Vector__XXX
 SG_ FI3_DriverMode3Output : 12|2@1+ (1,0) [0.0|3.0] "" Vector__XXX
 SG_ FI3_DriverMode4Ouput : 14|2@1+ (1,0) [0.0|3.0] "" Vector__XXX
 SG_ FI3_PTOModeInput : 16|2@1+ (1,0) [0.0|3.0] "" Vector__XXX
 SG_ FI3_PTOModeOutput : 18|2@1+ (1,0) [0.0|3.0] "" Vector__XXX
 SG_ FI3_DriversNetEngagement : 20|2@1+ (1,0) [0.0|3.0] "" Vector__XXX
 SG_ FI3_DriversSeatbeltEngagement : 22|2@1+ (1,0) [0.0|3.0] "" Vector__XXX
 SG_ FI3_TiltLockInput : 24|2@1+ (1,0) [0.0|3.0] "" Vector__XXX
 SG_ FI3_WorkGroupLockInput : 26|2@1+ (1,0) [0.0|3.0] "" Vector__XXX
 SG_ FI3_OperatorPresenceInput : 28|2@1+ (1,0) [0.0|3.0] "" Vector__XXX
 SG_ FI3_WorkGroupLockOutput : 34|2@1+ (1,0) [0.0|3.0] "" Vector__XXX
 SG_ FI3_OperatorPresenceOutput : 36|2@1+ (1,0) [0.0|3.0] "" Vector__XXX
 SG_ FI3_FootOnCruiseInput : 40|2@1+ (1,0) [0.0|3.0] "" Vector__XXX
 SG_ FI3_CruiseInput : 42|2@1+ (1,0) [0.0|3.0] "" Vector__XXX
 SG_ FI3_TredalInput : 44|2@1+ (1,0) [0.0|3.0] "" Vector__XXX
 SG_ FI3_CruiseSpeedInput : 46|2@1+ (1,0) [0.0|3.0] "" Vector__XXX
 SG_ FI3_FootOnCruiseOutput : 48|2@1+ (1,0) [0.0|3.0] "" Vector__XXX
 SG_ FI3_CruiseOutput : 50|2@1+ (1,0) [0.0|3.0] "" Vector__XXX
 SG_ FI3_CruiseControltoSetSpeed : 52|2@1+ (1,0) [0.0|0.0] "" Vector__XXX
 SG_ FI3_WorkModeInput : 30|2@1+ (1,0) [0.0|3.0] "" Vector__XXX
 SG_ FI3_TiltLockOutput : 32|2@1+ (1,0) [0.0|3.0] "" Vector__XXX

BO_ 2566911015 FlagItems_2_39: 8 VCM
 SG_ FI2_ThrttlBdyInitLrnValSave : 52|2@1+ (1,0) [0.0|3.0] "" Vector__XXX
 SG_ FI2_ThrttlBdyInitLearnSuccess : 54|2@1+ (1,0) [0.0|3.0] "" Vector__XXX
 SG_ FI2_ThrottleLimpHomeOpCondition : 46|2@1+ (1,0) [0.0|3.0] "" Vector__XXX
 SG_ FI2_SystemOnInput : 42|2@1+ (1,0) [0.0|3.0] "" Vector__XXX
 SG_ FI2_SftyFuelCutoffCndn : 56|2@1+ (1,0) [0.0|3.0] "" Vector__XXX
 SG_ FI2_RvrsblInjCutoffCndn : 58|2@1+ (1,0) [0.0|3.0] "" Vector__XXX
 SG_ FI2_PTOEngagementStatus : 38|2@1+ (1,0) [0.0|3.0] "" Vector__XXX
 SG_ FI2_ParkBrakeSwitchIn : 36|2@1+ (1,0) [0.0|3.0] "" Vector__XXX
 SG_ FI2_NeutralSwitchIn : 44|2@1+ (1,0) [0.0|3.0] "" Vector__XXX
 SG_ FI2_IrrvrsblInjCutoffCndn : 60|2@1+ (1,0) [0.0|3.0] "" Vector__XXX
 SG_ FI2_ETCFncnMonitor : 62|2@1+ (1,0) [0.0|3.0] "" Vector__XXX
 SG_ FI2_ADCOutput : 0|2@1+ (1,0) [0.0|3.0] "" Vector__XXX
 SG_ FI2_RearDiffLockOutput : 2|2@1+ (1,0) [0.0|3.0] "" Vector__XXX
 SG_ FI2_AWDOutput : 4|2@1+ (1,0) [0.0|3.0] "" Vector__XXX
 SG_ FI2_BrakeSwitchInput : 8|2@1+ (1,0) [0.0|3.0] "" Vector__XXX
 SG_ FI2_ADCSwitchInput : 10|2@1+ (1,0) [0.0|3.0] "" Vector__XXX
 SG_ FI2_TurfModeInput : 12|2@1+ (1,0) [0.0|3.0] "" Vector__XXX
 SG_ FI2_AWDSwitchInput : 14|2@1+ (1,0) [0.0|3.0] "" Vector__XXX
 SG_ FI2_ReverseSwitchInput : 16|2@1+ (1,0) [0.0|3.0] "" Vector__XXX
 SG_ FI2_ReverseLimitSwitchInput : 18|2@1+ (1,0) [0.0|3.0] "" Vector__XXX
 SG_ FI2_ForwardLimitSwitchInput : 20|2@1+ (1,0) [0.0|3.0] "" Vector__XXX
 SG_ FI2_EngineDirection : 22|2@1+ (1,0) [0.0|3.0] "" Vector__XXX
 SG_ FI2_RevSpeedLimitOverrideInput : 24|2@1+ (1,0) [0.0|3.0] "" Vector__XXX
 SG_ FI2_ReverseOverspeedSignal : 26|2@1+ (1,0) [0.0|3.0] "" Vector__XXX
 SG_ FI2_RightTurnSignalInput : 32|2@1+ (1,0) [0.0|3.0] "" Vector__XXX
 SG_ FI2_LeftTurnSignalInput : 34|2@1+ (1,0) [0.0|3.0] "" Vector__XXX
 SG_ FI2_KickstandSwitchInput : 40|2@1+ (1,0) [0.0|3.0] "" Vector__XXX
 SG_ FI2_ReflashEnableInputSignal : 48|2@1+ (1,0) [0.0|3.0] "" Vector__XXX
 SG_ FI2_TPSLearnInputSignal : 50|2@1+ (1,0) [0.0|3.0] "" Vector__XXX
 SG_ FI2_LowRangeSwitchInput : 30|2@1+ (1,0) [0.0|3.0] "" Vector__XXX
 SG_ FI2_ReverseMotorDriveInput : 28|2@1+ (1,0) [0.0|3.0] "" Vector__XXX

BO_ 2566911271 FlagItems_1_39: 8 VCM
 SG_ FI1_IntercoolerPumpDriverCircuit : 46|2@1+ (1,0) [0.0|3.0] "" Vector__XXX
 SG_ FI1_FuelPullSolenoidStatus : 60|2@1+ (1,0) [0.0|3.0] "" Vector__XXX
 SG_ FI1_ClutchSwitchInput2 : 62|2@1+ (1,0) [0.0|3.0] "" Vector__XXX
 SG_ FI1_FuelPumpDriverCkt : 0|2@1+ (1,0) [0.0|3.0] "" Vector__XXX
 SG_ FI1_RolloverSwitch : 2|2@1+ (1,0) [0.0|3.0] "" Vector__XXX
 SG_ FI1_CrankSensorSignal : 4|2@1+ (1,0) [0.0|3.0] "" Vector__XXX
 SG_ FI1_CamSensorSignal : 6|2@1+ (1,0) [0.0|3.0] "" Vector__XXX
 SG_ FI1_RPMLimitActive : 8|2@1+ (1,0) [0.0|3.0] "" Vector__XXX
 SG_ FI1_IdleSwitch : 10|2@1+ (1,0) [0.0|3.0] "" Vector__XXX
 SG_ FI1_CycleSynchro : 12|2@1+ (1,0) [0.0|3.0] "" Vector__XXX
 SG_ FI1_IdleSpeedControlStatus : 14|2@1+ (1,0) [0.0|3.0] "" Vector__XXX
 SG_ FI1_IgnitionSwitchInput : 16|2@1+ (1,0) [0.0|3.0] "" Vector__XXX
 SG_ FI1_RunStopSwitchInput : 18|2@1+ (1,0) [0.0|3.0] "" Vector__XXX
 SG_ FI1_StartSwitchInput : 20|2@1+ (1,0) [0.0|3.0] "" Vector__XXX
 SG_ FI1_ThrottleSafetySwInput : 22|2@1+ (1,0) [0.0|3.0] "" Vector__XXX
 SG_ FI1_FanRelayOutput : 24|2@1+ (1,0) [0.0|3.0] "" Vector__XXX
 SG_ FI1_IntercoolerFanOutput : 26|2@1+ (1,0) [0.0|3.0] "" Vector__XXX
 SG_ FI1_ReverseAlarmOutput : 28|2@1+ (1,0) [0.0|3.0] "" Vector__XXX
 SG_ FI1_MainRelayOutput : 30|2@1+ (1,0) [0.0|3.0] "" Vector__XXX
 SG_ FI1_StartSolenoidOutput : 32|2@1+ (1,0) [0.0|3.0] "" Vector__XXX
 SG_ FI1_IgnitionRelayOutput : 34|2@1+ (1,0) [0.0|3.0] "" Vector__XXX
 SG_ FI1_ChassisRelayOutput : 36|2@1+ (1,0) [0.0|3.0] "" Vector__XXX
 SG_ FI1_StarterEnableOutput : 38|2@1+ (1,0) [0.0|3.0] "" Vector__XXX
 SG_ FI1_ExhaustValveOutput : 40|2@1+ (1,0) [0.0|3.0] "" Vector__XXX
 SG_ FI1_BatteryChargeRelayOutput : 42|2@1+ (1,0) [0.0|3.0] "" Vector__XXX
 SG_ FI1_HeaterAccRelay : 44|2@1+ (1,0) [0.0|3.0] "" Vector__XXX
 SG_ FI1_ClutchSwitchInput : 56|2@1+ (1,0) [0.0|3.0] "" Vector__XXX
 SG_ FI1_MILLampOutput : 48|2@1+ (1,0) [0.0|3.0] "" Vector__XXX
 SG_ FI1_OverTempLampOutput : 50|2@1+ (1,0) [0.0|3.0] "" Vector__XXX
 SG_ FI1_KnockDetLampOutput : 52|2@1+ (1,0) [0.0|3.0] "" Vector__XXX
 SG_ FI1_ElecOilPumpDrvrCirc : 58|2@1+ (1,0) [0.0|3.0] "" Vector__XXX

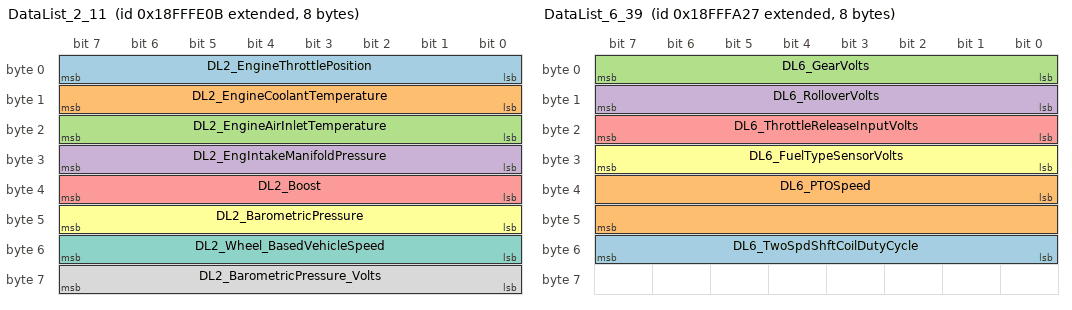
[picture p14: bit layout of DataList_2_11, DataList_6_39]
BO_ 2566913547 DataList_2_11: 8 ABS
 SG_ DL2_EngineThrottlePosition : 0|8@1+ (0.4,0) [0.0|100.0] "%" Vector__XXX
 SG_ DL2_EngineCoolantTemperature : 8|8@1+ (1,-40) [-40.0|210.0] "°C" Vector__XXX
 SG_ DL2_EngineAirInletTemperature : 16|8@1+ (1,-40) [-40.0|210.0] "°C" Vector__XXX
 SG_ DL2_EngIntakeManifoldPressure : 24|8@1+ (2,0) [0.0|500.0] "kPa" Vector__XXX
 SG_ DL2_Boost : 32|8@1+ (2,0) [0.0|500.0] "kPa" Vector__XXX
 SG_ DL2_BarometricPressure : 40|8@1+ (0.5,0) [0.0|125.0] "kPa" Vector__XXX
 SG_ DL2_Wheel_BasedVehicleSpeed : 48|8@1+ (1,0) [0.0|255.0] "km/h" Vector__XXX
 SG_ DL2_BarometricPressure_Volts : 56|8@1+ (0.025,0) [0.0|6.375] "V" Vector__XXX

BO_ 2566912551 DataList_6_39: 8 VCM
 SG_ DL6_TwoSpdShftCoilDutyCycle : 48|8@1+ (0.4,0) [0.0|100.0] "%" Vector__XXX
 SG_ DL6_PTOSpeed : 32|16@1+ (1,0) [0.0|65535.0] "RPM" Vector__XXX
 SG_ DL6_GearVolts : 0|8@1+ (0.1,0) [0.0|25.5] "V" Vector__XXX
 SG_ DL6_RolloverVolts : 8|8@1+ (0.025,0) [0.0|6.375] "V" Vector__XXX
 SG_ DL6_ThrottleReleaseInputVolts : 16|8@1+ (0.1,0) [0.0|25.5] "V" Vector__XXX
 SG_ DL6_FuelTypeSensorVolts : 24|8@1+ (0.1,0) [0.0|25.5] "V" Vector__XXX

BO_ 2566908427 DataList_17_11: 8 ABS
 SG_ DL17_Wheel_Spd_Front_LSB : 0|8@1+ (0.00390625,0) [0.0|0.99609375] "kph" Vector__XXX
 SG_ DL17_Wheel_Spd_Front_MSB : 8|8@1+ (0.00390625,0) [0.0|0.99609375] "kph" Vector__XXX
 SG_ DL17_Wheel_Spd_Rear_LSB : 16|8@1+ (0.00390625,0) [0.0|0.99609375] "kph" Vector__XXX
 SG_ DL17_Wheel_Spd_Rear_MSB : 24|8@1+ (0.00390625,0) [0.0|0.99609375] "kph" Vector__XXX
 SG_ DL17_ABS_Source_Voltage : 32|8@1+ (0.1,0) [0.0|25.5] "V" Vector__XXX
 SG_ DL17_ABS_Pump_Command : 40|2@1+ (1,0) [0.0|3.0] "" Vector__XXX
 SG_ DL17_Brake_Sw_Status : 42|2@1+ (1,0) [0.0|3.0] "" Vector__XXX
 SG_ DL17_ABS_Failsafe_Relay : 44|2@1+ (1,0) [0.0|3.0] "" Vector__XXX
 SG_ DL17_ABS_Evac_Fill : 46|2@1+ (1,0) [0.0|3.0] "" Vector__XXX
 SG_ DL17_RedBrakeLamp : 48|2@1+ (1,0) [0.0|3.0] "" Vector__XXX
 SG_ DL17_ABSFaultLamp : 50|2@1+ (1,0) [0.0|3.0] "" Vector__XXX
 SG_ DL17_TCSDisabledLamp : 52|2@1+ (1,0) [0.0|3.0] "" Vector__XXX
 SG_ DL17_ESCDisabledLamp : 54|2@1+ (1,0) [0.0|3.0] "" Vector__XXX
 SG_ DL17_ESCFaultLampFlashing : 56|2@1+ (1,0) [0.0|3.0] "" Vector__XXX
 SG_ DL17_ESCFaultLampSolid : 58|2@1+ (1,0) [0.0|3.0] "" Vector__XXX
 SG_ DL17_TorqueRequestedtoECM : 60|2@1+ (1,0) [0.0|3.0] "" Vector__XXX
 SG_ DL17_TractionCtrlOverrideSwitch : 62|2@1+ (1,0) [0.0|0.0] "" Vector__XXX

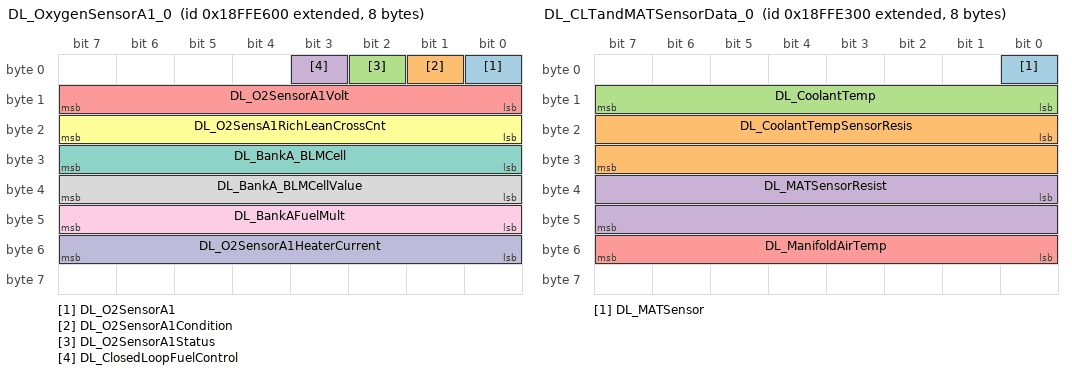
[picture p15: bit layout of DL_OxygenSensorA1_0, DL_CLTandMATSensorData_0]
BO_ 2566907392 DL_OxygenSensorA1_0: 8 ECM
 SG_ DL_O2SensorA1 : 0|1@1+ (1,0) [0.0|1.0] "" Vector__XXX
 SG_ DL_O2SensorA1Condition : 1|1@1+ (1,0) [0.0|1.0] "" Vector__XXX
 SG_ DL_O2SensorA1Status : 2|1@1+ (1,0) [0.0|1.0] "" Vector__XXX
 SG_ DL_ClosedLoopFuelControl : 3|1@1+ (1,0) [0.0|1.0] "" Vector__XXX
 SG_ DL_O2SensorA1Volt : 8|8@1+ (0.009766,0) [0.0|2.44] "Volts" Vector__XXX
 SG_ DL_O2SensA1RichLeanCrossCnt : 16|8@1+ (1,0) [0.0|250.0] "Counts/Sec" Vector__XXX
 SG_ DL_BankA_BLMCell : 24|8@1+ (1,0) [0.0|250.0] "Cell ID" Vector__XXX
 SG_ DL_BankA_BLMCellValue : 32|8@1+ (0.007813,0) [0.0|1.95325] "" Vector__XXX
 SG_ DL_BankAFuelMult : 40|8@1+ (0.0625,0) [0.0|15.625] "" Vector__XXX
 SG_ DL_O2SensorA1HeaterCurrent : 48|8@1+ (0.0625,0) [0.0|15.625] "Amps" Vector__XXX

BO_ 2566906880 DL_EnginePedalPositionData_0: 8 ECM
 SG_ DL_PedalPositionSensor1Volt : 0|8@1+ (0.01953,0) [0.0|4.98015] "Volts" Vector__XXX
 SG_ DL_PedalPositionSensor2Volt : 8|8@1+ (0.01953,0) [0.0|4.98015] "Volts" Vector__XXX
 SG_ DL_PedalPosition : 16|8@1+ (0.3906,0) [0.0|100.0] "%" Vector__XXX

BO_ 2566906624 DL_CLTandMATSensorData_0: 8 ECM
 SG_ DL_MATSensor : 0|1@1+ (1,0) [0.0|1.0] "" Vector__XXX
 SG_ DL_CoolantTempSensorResis : 16|16@1+ (2,0) [0.0|131060.0] "Ohms" Vector__XXX
 SG_ DL_CoolantTemp : 8|8@1+ (0.75,-40) [-40.0|151.25] "°C" Vector__XXX
 SG_ DL_MATSensorResist : 32|16@1+ (2,0) [0.0|131060.0] "Ohms" Vector__XXX
 SG_ DL_ManifoldAirTemp : 48|8@1+ (0.75,-40) [-40.0|151.25] "°C" Vector__XXX

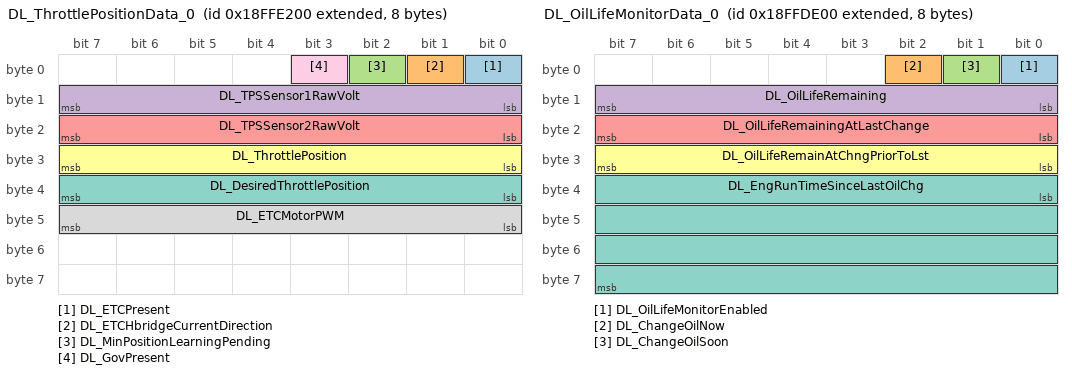
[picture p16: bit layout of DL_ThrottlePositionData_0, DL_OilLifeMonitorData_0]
BO_ 2566906368 DL_ThrottlePositionData_0: 8 ECM
 SG_ DL_ETCPresent : 0|1@1+ (1,0) [0.0|1.0] "" Vector__XXX
 SG_ DL_ETCHbridgeCurrentDirection : 1|1@1+ (1,0) [0.0|1.0] "" Vector__XXX
 SG_ DL_MinPositionLearningPending : 2|1@1+ (1,0) [0.0|1.0] "" Vector__XXX
 SG_ DL_TPSSensor1RawVolt : 8|8@1+ (0.01953,0) [0.0|4.98015] "Volts" Vector__XXX
 SG_ DL_TPSSensor2RawVolt : 16|8@1+ (0.01953,0) [0.0|4.98015] "Volts" Vector__XXX
 SG_ DL_ThrottlePosition : 24|8@1+ (0.3906,0) [0.0|100.0] "%" Vector__XXX
 SG_ DL_DesiredThrottlePosition : 32|8@1+ (0.3906,0) [0.0|99.603] "%" Vector__XXX
 SG_ DL_ETCMotorPWM : 40|8@1+ (0.3906,0) [0.0|99.603] "%" Vector__XXX
 SG_ DL_GovPresent : 3|1@1+ (1,0) [0.0|1.0] "" Vector__XXX

BO_ 2566906112 DL_MAPSenorData_0: 8 ECM
 SG_ DL_MAPSensorRawVoltage : 0|8@1+ (0.01953,0) [0.0|4.98015] "Volts" Vector__XXX
 SG_ DL_ManifoldAirPress : 8|16@1+ (0.007813,0) [0.0|511.99] "kPa" Vector__XXX
 SG_ DL_BarometricPressure : 24|16@1+ (0.007813,0) [0.0|511.99] "kPa" Vector__XXX
 SG_ DL_BaroSensorPresent : 40|1@1+ (1,0) [0.0|1.0] "" Vector__XXX

BO_ 2566905344 DL_OilLifeMonitorData_0: 8 ECM
 SG_ DL_OilLifeMonitorEnabled : 0|1@1+ (1,0) [0.0|1.0] "" Vector__XXX
 SG_ DL_ChangeOilNow : 2|1@1+ (1,0) [0.0|1.0] "" Vector__XXX
 SG_ DL_ChangeOilSoon : 1|1@1+ (1,0) [0.0|1.0] "" Vector__XXX
 SG_ DL_OilLifeRemaining : 8|8@1+ (0.3906,0) [0.0|100.0] "%" Vector__XXX
 SG_ DL_OilLifeRemainingAtLastChange : 16|8@1+ (0.3906,0) [0.0|100.0] "%" Vector__XXX
 SG_ DL_OilLifeRemainAtChngPriorToLst : 24|8@1+ (0.3906,0) [0.0|100.0] "%" Vector__XXX
 SG_ DL_EngRunTimeSinceLastOilChg : 32|32@1+ (1,0) [0.0|4294967295.0] "Sec" Vector__XXX

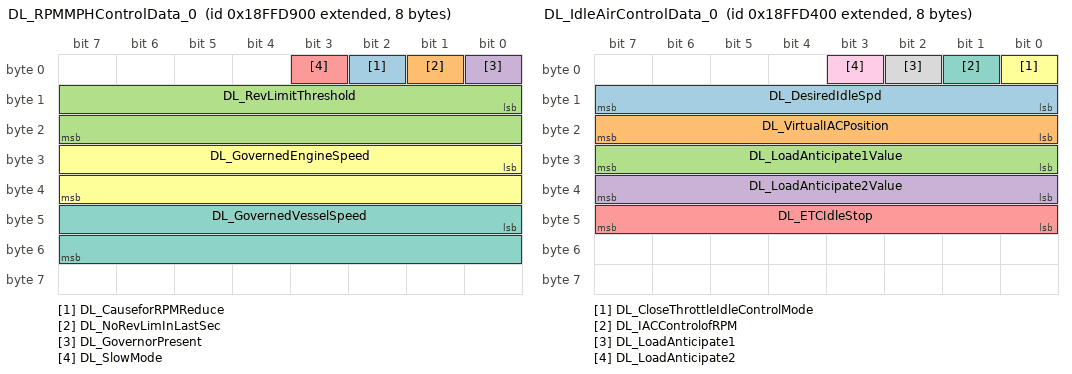
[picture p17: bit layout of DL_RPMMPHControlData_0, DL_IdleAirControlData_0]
BO_ 2566904064 DL_RPMMPHControlData_0: 8 ECM
 SG_ DL_CauseforRPMReduce : 2|1@1+ (1,0) [0.0|1.0] "" Vector__XXX
 SG_ DL_NoRevLimInLastSec : 1|1@1+ (1,0) [0.0|1.0] "" Vector__XXX
 SG_ DL_RevLimitThreshold : 8|16@1+ (0.25,0) [0.0|16382.5] "RPM" Vector__XXX
 SG_ DL_GovernorPresent : 0|1@1+ (1,0) [0.0|1.0] "" Vector__XXX
 SG_ DL_SlowMode : 3|1@1+ (1,0) [0.0|1.0] "" Vector__XXX
 SG_ DL_GovernedEngineSpeed : 24|16@1+ (0.25,0) [0.0|16383.75] "rpm" Vector__XXX
 SG_ DL_GovernedVesselSpeed : 40|16@1+ (0.003906,0) [0.0|255.97971] "mph" Vector__XXX

BO_ 2566903808 DL_CanisterPurgeData_0: 8 ECM
 SG_ DL_CanisterPurgeSystemPresent : 0|1@1+ (1,0) [0.0|1.0] "" Vector__XXX
 SG_ DL_CCPDutyCycle : 8|8@1+ (0.3906,0) [0.0|99.603] "%" Vector__XXX

BO_ 2566903552 DL_EngineDiagHistoryData1_0: 8 ECM
 SG_ DL_FailedDTCTestThisIgnCycle : 0|1@1+ (1,0) [0.0|1.0] "" Vector__XXX
 SG_ DL_HistoryDataCorrupted : 1|1@1+ (1,0) [0.0|1.0] "" Vector__XXX
 SG_ DL_NumWarmUpCycSinceLastDTCSet : 8|8@1+ (1,0) [0.0|250.0] "Cycles" Vector__XXX
 SG_ DL_TotalEngineRunTime : 16|32@1+ (1,0) [0.0|4294967290.0] "sec" Vector__XXX

BO_ 2566903296 DL_FanData_0: 8 ECM
 SG_ DL_FanDriver : 4|1@1+ (1,0) [0.0|1.0] "" Vector__XXX
 SG_ DL_DesiredFanPosition : 24|8@1+ (0.3906,0) [0.0|99.603] "%" Vector__XXX
 SG_ DL_FanDutyCycle : 32|8@1+ (0.3906,0) [0.0|99.603] "%" Vector__XXX

BO_ 2566902784 DL_IdleAirControlData_0: 8 ECM
 SG_ DL_DesiredIdleSpd : 8|8@1+ (8,0) [0.0|2000.0] "RPM" Vector__XXX
 SG_ DL_VirtualIACPosition : 16|8@1+ (0.3906,0) [0.0|99.603] "%" Vector__XXX
 SG_ DL_LoadAnticipate1Value : 24|8@1+ (0.3906,0) [0.0|99.603] "%" Vector__XXX
 SG_ DL_LoadAnticipate2Value : 32|8@1+ (0.3906,0) [0.0|99.603] "%" Vector__XXX
 SG_ DL_ETCIdleStop : 40|8@1+ (0.3906,0) [0.0|99.603] "%" Vector__XXX
 SG_ DL_CloseThrottleIdleControlMode : 0|1@1+ (1,0) [0.0|1.0] "" Vector__XXX
 SG_ DL_IACControlofRPM : 1|1@1+ (1,0) [0.0|1.0] "" Vector__XXX
 SG_ DL_LoadAnticipate1 : 2|1@1+ (1,0) [0.0|1.0] "" Vector__XXX
 SG_ DL_LoadAnticipate2 : 3|1@1+ (1,0) [0.0|1.0] "" Vector__XXX

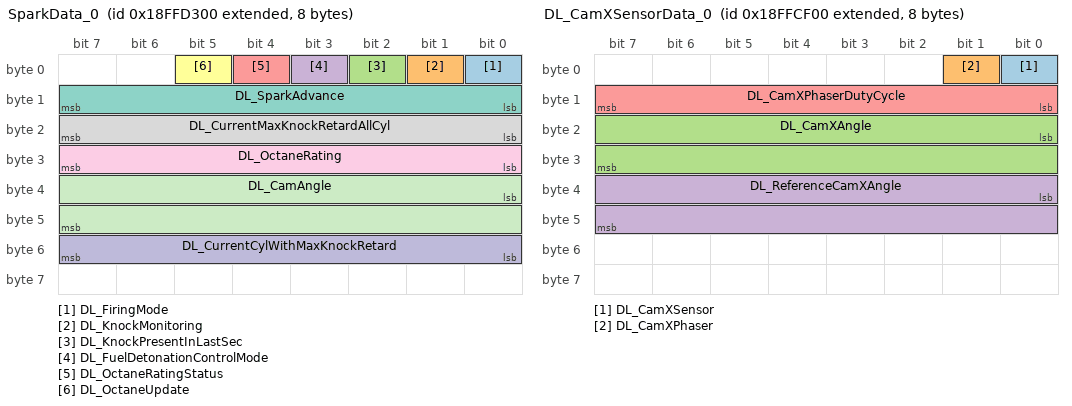
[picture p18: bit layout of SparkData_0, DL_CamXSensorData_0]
BO_ 2566902528 SparkData_0: 8 ECM
 SG_ DL_FiringMode : 0|1@1+ (1,0) [0.0|1.0] "" Vector__XXX
 SG_ DL_KnockMonitoring : 1|1@1+ (1,0) [0.0|1.0] "" Vector__XXX
 SG_ DL_KnockPresentInLastSec : 2|1@1+ (1,0) [0.0|1.0] "" Vector__XXX
 SG_ DL_FuelDetonationControlMode : 3|1@1+ (1,0) [0.0|1.0] "" Vector__XXX
 SG_ DL_OctaneRatingStatus : 4|1@1+ (1,0) [0.0|1.0] "" Vector__XXX
 SG_ DL_OctaneUpdate : 5|1@1+ (1,0) [0.0|1.0] "" Vector__XXX
 SG_ DL_SparkAdvance : 8|8@1+ (0.3516,-20) [-20.0|69.658] "Deg" Vector__XXX
 SG_ DL_CurrentMaxKnockRetardAllCyl : 16|8@1+ (0.08789,0) [0.0|22.41195] "Deg" Vector__XXX
 SG_ DL_OctaneRating : 24|8@1+ (0.3906,0) [0.0|99.603] "Cnts" Vector__XXX
 SG_ DL_CurrentCylWithMaxKnockRetard : 48|8@1+ (1,0) [0.0|255.0] "Cyl#" Vector__XXX
 SG_ DL_CamAngle : 32|16@1+ (1,0) [0.0|65535.0] "" Vector__XXX

BO_ 2566901504 DL_CamXSensorData_0: 8 ECM
 SG_ DL_CamXSensor : 0|1@1+ (1,0) [0.0|1.0] "" Vector__XXX
 SG_ DL_CamXPhaser : 1|1@1+ (1,0) [0.0|1.0] "" Vector__XXX
 SG_ DL_CamXAngle : 16|16@1+ (0.01563,0) [0.0|1024.31205] "Deg" Vector__XXX
 SG_ DL_ReferenceCamXAngle : 32|16@1+ (0.01563,0) [0.0|1024.31205] "Deg" Vector__XXX
 SG_ DL_CamXPhaserDutyCycle : 8|8@1+ (0.3906,0) [0.0|99.603] "%" Vector__XXX

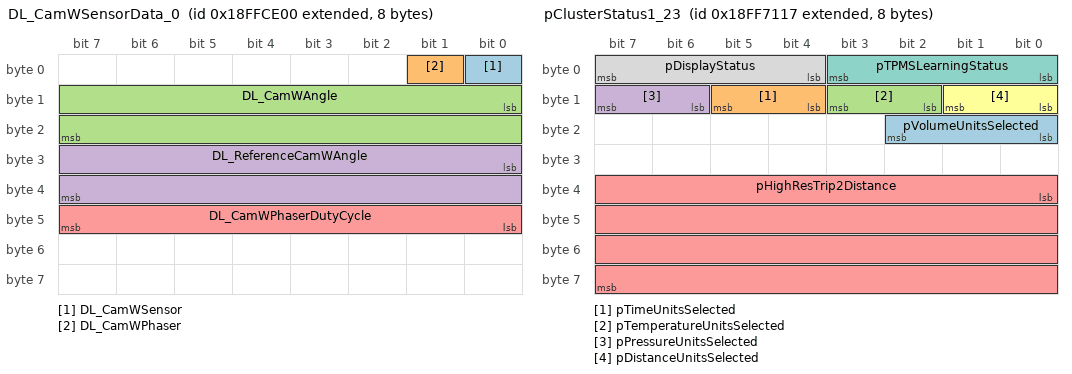
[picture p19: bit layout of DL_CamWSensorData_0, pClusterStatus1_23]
BO_ 2566901248 DL_CamWSensorData_0: 8 ECM
 SG_ DL_CamWSensor : 0|1@1+ (1,0) [0.0|1.0] "" Vector__XXX
 SG_ DL_CamWPhaser : 1|1@1+ (1,0) [0.0|1.0] "" Vector__XXX
 SG_ DL_CamWAngle : 8|16@1+ (0.01563,0) [0.0|1024.31205] "Deg" Vector__XXX
 SG_ DL_ReferenceCamWAngle : 24|16@1+ (0.01563,0) [0.0|1024.31205] "Deg" Vector__XXX
 SG_ DL_CamWPhaserDutyCycle : 40|8@1+ (0.3906,0) [0.0|99.603] "%" Vector__XXX

BO_ 2566885888 DL_FuelFlowAirFlowData_0: 8 ECM
 SG_ DL_InjectorBank_APulseWidth : 0|16@1+ (0.01,0) [0.0|655.3] "ms" Vector__XXX
 SG_ DL_InjectorBank_BPulseWidth : 16|16@1+ (0.01,0) [0.0|655.3] "ms" Vector__XXX
 SG_ DL_RequiredFuelFlowRate : 32|16@1+ (0.003433,0) [0.0|224.96] "Kg/hr" Vector__XXX
 SG_ DL_Airflow : 48|16@1+ (0.05493,0) [0.0|3599.56] "Kg/hr" Vector__XXX

BO_ 2566877696 pVT1_0: 8 ECM
 SG_ pLeftHandGripTemp : 0|8@1+ (1,-40) [-40.0|210.0] "deg C" Vector__XXX
 SG_ pRightHandGripTemp : 8|8@1+ (1,-40) [-40.0|210.0] "deg C" Vector__XXX

BO_ 2566877463 pClusterStatus1_23: 8 IC
 SG_ pVolumeUnitsSelected : 16|3@1+ (1,0) [0.0|7.0] "" Vector__XXX
 SG_ pTimeUnitsSelected : 12|2@1+ (1,0) [0.0|3.0] "" Vector__XXX
 SG_ pTemperatureUnitsSelected : 10|2@1+ (1,0) [0.0|3.0] "" Vector__XXX
 SG_ pPressureUnitsSelected : 14|2@1+ (1,0) [0.0|3.0] "" Vector__XXX
 SG_ pHighResTrip2Distance : 32|32@1+ (0.005,0) [0.0|21055406.0] "km" Vector__XXX
 SG_ pDistanceUnitsSelected : 8|2@1+ (1,0) [0.0|3.0] "" Vector__XXX
 SG_ pTPMSLearningStatus : 0|4@1+ (1,0) [0.0|15.0] "" Vector__XXX
 SG_ pDisplayStatus : 4|4@1+ (1,0) [0.0|15.0] "" Vector__XXX

BO_ 2566876711 pVF1_39: 8 VCM
 SG_ pEngineOilPressureStatus : 4|2@1+ (1,0) [0.0|3.0] "" Vector__XXX
 SG_ pHydraulicOilPressureStatus : 2|2@1+ (1,0) [0.0|3.0] "" Vector__XXX
 SG_ pHydraulicOilTempStatus : 0|2@1+ (1,0) [0.0|3.0] "" Vector__XXX

BO_ 2633984551 pDriveSystemStatus_39: 8 VCM
 SG_ pHeatedGripEnable : 48|2@1+ (1,0) [0.0|3.0] "" Vector__XXX
 SG_ pSideStandStatus : 36|2@1+ (1,0) [0.0|3.0] "" Vector__XXX
 SG_ pTetherSwitchStatus : 46|2@1+ (1,0) [0.0|3.0] "" Vector__XXX
 SG_ pLowFuelIndicatorStatus : 10|2@1+ (1,0) [0.0|3.0] "" Vector__XXX
 SG_ pOperatorNotInOperatingStation : 38|2@1+ (1,0) [0.0|3.0] "" Vector__XXX
 SG_ pParkBrakeIndicatorStatus : 40|3@1+ (1,0) [0.0|7.0] "" Vector__XXX
 SG_ pADCRequested : 34|2@1+ (1,0) [0.0|3.0] "" Vector__XXX
 SG_ pAWDModeRequested : 32|2@1+ (1,0) [0.0|3.0] "" Vector__XXX
 SG_ pRWDModeRequested : 30|2@1+ (1,0) [0.0|3.0] "" Vector__XXX
 SG_ pTurfModeRequested : 28|2@1+ (1,0) [0.0|3.0] "" Vector__XXX
 SG_ pADCStatus : 0|2@1+ (1,0) [0.0|3.0] "" Vector__XXX
 SG_ pTreadleNeutralStatus : 2|2@1+ (1,0) [0.0|3.0] "" Vector__XXX
 SG_ pTreadleReverseStatus : 4|2@1+ (1,0) [0.0|3.0] "" Vector__XXX
 SG_ pSecurityLightStatus : 6|2@1+ (1,0) [0.0|3.0] "" Vector__XXX
 SG_ pHighBeamIndicatorStatus : 8|2@1+ (1,0) [0.0|3.0] "" Vector__XXX
 SG_ pHeatedGripsPercentage : 16|8@1+ (0.4,0) [0.0|100.0] "%" Vector__XXX
 SG_ pCruiseControlSetStatus : 24|2@1+ (1,0) [0.0|3.0] "" Vector__XXX
 SG_ pSeatBeltIndicatorStatus : 12|3@1+ (1,0) [0.0|7.0] "" Vector__XXX

BO_ 2432656679 pOperatorSwitchStatus_39: 8 VCM
 SG_ pOperatorButton29 : 58|2@1+ (1,0) [0.0|3.0] "" Vector__XXX
 SG_ pOperatorButton1 : 0|2@1+ (1,0) [0.0|3.0] "" Vector__XXX
 SG_ pOperatorButton2 : 2|2@1+ (1,0) [0.0|3.0] "" Vector__XXX
 SG_ pOperatorButton3 : 4|2@1+ (1,0) [0.0|3.0] "" Vector__XXX
 SG_ pOperatorButton4 : 6|2@1+ (1,0) [0.0|3.0] "" Vector__XXX
 SG_ pOperatorButton5 : 8|2@1+ (1,0) [0.0|3.0] "" Vector__XXX
 SG_ pOperatorButton6 : 10|2@1+ (1,0) [0.0|3.0] "" Vector__XXX
 SG_ pOperatorButton7 : 12|2@1+ (1,0) [0.0|3.0] "" Vector__XXX
 SG_ pOperatorButton8 : 14|2@1+ (1,0) [0.0|3.0] "" Vector__XXX
 SG_ pOperatorButton9 : 16|2@1+ (1,0) [0.0|3.0] "" Vector__XXX
 SG_ pOperatorButton10 : 18|2@1+ (1,0) [0.0|3.0] "" Vector__XXX
 SG_ pOperatorButton11 : 20|2@1+ (1,0) [0.0|3.0] "" Vector__XXX
 SG_ pOperatorButton12 : 22|2@1+ (1,0) [0.0|3.0] "" Vector__XXX
 SG_ pOperatorButton13 : 24|2@1+ (1,0) [0.0|3.0] "" Vector__XXX
 SG_ pOperatorButton14 : 26|2@1+ (1,0) [0.0|3.0] "" Vector__XXX
 SG_ pOperatorButton15 : 28|2@1+ (1,0) [0.0|3.0] "" Vector__XXX
 SG_ pOperatorButton16 : 30|2@1+ (1,0) [0.0|3.0] "" Vector__XXX
 SG_ pOperatorButton17 : 32|2@1+ (1,0) [0.0|3.0] "" Vector__XXX
 SG_ pOperatorButton18 : 34|2@1+ (1,0) [0.0|3.0] "" Vector__XXX
 SG_ pOperatorButton19 : 36|2@1+ (1,0) [0.0|3.0] "" Vector__XXX
 SG_ pOperatorButton20 : 38|2@1+ (1,0) [0.0|3.0] "" Vector__XXX
 SG_ pOperatorButton21 : 40|2@1+ (1,0) [0.0|3.0] "" Vector__XXX
 SG_ pOperatorButton22 : 42|2@1+ (1,0) [0.0|3.0] "" Vector__XXX
 SG_ pOperatorButton23 : 44|2@1+ (1,0) [0.0|3.0] "" Vector__XXX
 SG_ pOperatorButton24 : 46|2@1+ (1,0) [0.0|3.0] "" Vector__XXX
 SG_ pOperatorButton25 : 48|2@1+ (1,0) [0.0|3.0] "" Vector__XXX
 SG_ pOperatorButton26 : 50|2@1+ (1,0) [0.0|3.0] "" Vector__XXX
 SG_ pOperatorButton27 : 52|2@1+ (1,0) [0.0|3.0] "" Vector__XXX
 SG_ pOperatorButton28 : 54|2@1+ (1,0) [0.0|3.0] "" Vector__XXX
 SG_ pSideStandStatus : 56|2@1+ (1,0) [0.0|3.0] "" Vector__XXX

BO_ 2566845479 TireCondition_39: 8 VCM
 SG_ TireLocation : 0|8@1+ (1,0) [0.0|255.0] "Bit" Vector__XXX
 SG_ TirePressure : 8|8@1+ (4,0) [0.0|1000.0] "kPa" Vector__XXX
 SG_ TireTemperature : 16|16@1+ (0.03125,-273) [-273.0|1734.96875] "DegC" Vector__XXX

BO_ 3221225472 VECTOR__INDEPENDENT_SIG_MSG: 0 Vector__XXX
 SG_ HVES1HVBPsvITR_8432 : 0|16@1+ (0.1,0) [0.0|6425.5] "Ohm/V" Vector__XXX
 SG_ HVES1HVBAcvITR_8431 : 0|16@1+ (0.1,0) [0.0|6425.5] "Ohm/V" Vector__XXX
 SG_ HVES1LoCellStOChaCellNo_8248 : 0|8@1+ (1,0) [0.0|250.0] "count" Vector__XXX
 SG_ HVES1LoCellStOChaModuNo_8247 : 0|8@1+ (1,0) [0.0|250.0] "count" Vector__XXX
 SG_ HVES1HiCellStOChaCellNo_8246 : 0|8@1+ (1,0) [0.0|250.0] "count" Vector__XXX
 SG_ HVES1HiCellStOChaModuNo_8245 : 0|8@1+ (1,0) [0.0|250.0] "count" Vector__XXX
 SG_ TranIdleGovrnrFuelingInhbit_7829 : 0|8@1- (1,0) [0.0|0.0] "" Vector__XXX
 SG_ NumberOfMembersInWorkingSet : 0|8@1+ (1,0) [0.0|0.0] "" Vector__XXX
 SG_ SourceAddress : 0|8@1+ (1,0) [0.0|0.0] "" Vector__XXX
 SG_ NncntnuslyMonitoredSystemsStatus : 0|16@1+ (1,0) [0.0|0.0] "" Vector__XXX
 SG_ NncntnslyMonitoredSystemsSupport : 0|16@1+ (1,0) [0.0|0.0] "" Vector__XXX
 SG_ CntnslyMntrdSystmsSupport_Status : 0|8@1+ (1,0) [0.0|0.0] "" Vector__XXX
 SG_ AETCTorqueValue : 0|16@1+ (1,0) [0.0|64255.0] "Nm" Vector__XXX
 SG_ TrailerWeight : 0|16@1+ (2,0) [0.0|128510.0] "kg" Vector__XXX
 SG_ ReferenceTirePressSetting : 0|8@1+ (8,0) [0.0|2000.0] "kPa" Vector__XXX
 SG_ ReferenceTirePress : 0|8@1+ (8,0) [0.0|2000.0] "kPa" Vector__XXX
 SG_ TirePressThresholdDetection : 0|3@1+ (1,0) [0.0|7.0] "" Vector__XXX
 SG_ TireAirLeakageRate : 0|16@1+ (0.1,0) [0.0|6425.5] "Pa/s" Vector__XXX
 SG_ CTIWheelEndElectricalFault : 0|2@1+ (1,0) [0.0|3.0] "" Vector__XXX
 SG_ CTITireStatus : 0|2@1+ (1,0) [0.0|3.0] "" Vector__XXX
 SG_ CTIWheelSensorStatus : 0|2@1+ (1,0) [0.0|3.0] "" Vector__XXX
 SG_ TireTemp : 0|16@1+ (0.03125,-273) [-273.0|1734.96875] "deg C" Vector__XXX
 SG_ TirePress : 0|8@1+ (4,0) [0.0|1000.0] "kPa" Vector__XXX
 SG_ EngTurningGearEngaged : 0|2@1+ (1,0) [0.0|3.0] "" Vector__XXX
 SG_ AETCSpeedValue : 0|16@1+ (0.125,0) [0.0|8031.875] "rpm" Vector__XXX

CM_ BO_ 3221225472  "This is a message for not used signals, created by Vector CANdb++ DBC OLE DB Provider.";
CM_ BO_ 2564292857  "Memory Access Response / Output State Control";
CM_ BO_ 2564358393  "Memory Access Request / Output State Control";
CM_ BO_ 2566846298  "Vehicle Electrical Power Information";
CM_ BO_ 2633984602  "Status of Drive System Information";
CM_ BO_ 2365530458  "Feedback from the engine or motor controller to be used in conjunction with making torque/speed requests.  To be used with PGN 65312 and PGN 65314.";
CM_ BO_ 2566843994  "Engine Temperature 1";
CM_ BO_ 2566876762  "Vehicle Fluid Information";
CM_ BO_ 2566876672  "Vehicle Fluid Information";
CM_ BO_ 2565866755  "Electronic Transmission Controller 2";
CM_ BO_ 2566844675  "Cruise Control Status and Vehicle Speed Information";
CM_ BO_ 2365525594  "BMC Power Information";
CM_ BO_ 2566844762  "Cruise Control Status and Vehicle Speed Information";
CM_ BO_ 2566853722  "Contains information used on the Watt platform for electrical characteristics of the vehicle.";
CM_ BO_ 2365526260  "Traction Battery Information";
CM_ BO_ 2365526259  "Traction Battery Information";
CM_ BO_ 2365526516  "BMC Status Information";
CM_ BO_ 2365526772  "Battery Charger Status Information";
CM_ BO_ 2365526004  "Vehicle Energy Information";
CM_ BO_ 2365526515  "BMC Status Information";
CM_ BO_ 2365526771  "Battery Charger Status Information";
CM_ BO_ 2365526003  "Vehicle Energy Information";
CM_ BO_ 2298415094  "Perfromance Characteristics of the Motor";
CM_ BO_ 2298415095  "Perfromance Characteristics of the Motor";
CM_ BO_ 2298415090  "Perfromance Characteristics of the Motor";
CM_ BO_ 2298415089  "Perfromance Characteristics of the Motor";
CM_ BO_ 2298415088  "Perfromance Characteristics of the Motor";
CM_ BO_ 2298415087  "Perfromance Characteristics of the Motor";
CM_ BO_ 2566834735  "Active diagnostic trouble codes";
CM_ BO_ 2566855680  "Fan Control";
CM_ BO_ 2566886912  "Fleet Management";
CM_ BO_ 2566886400  "Log data";
CM_ BO_ 2566913547  "ECU Data List 2";
CM_ BO_ 2566912551  "ECU Data List 6";
CM_ BO_ 2566908427  "ECU Data List 17";
CM_ BO_ 2566877696  "pVehicle Temperature 1";
CM_ BO_ 2566877463  "Instrument Cluster Information";
CM_ BO_ 2566876711  "Vehicle Fluid Information";
CM_ BO_ 2633984551  "Status of Drive System Information";
CM_ BO_ 2432656679  "Indicates the status of multiple operator controlled switches.";
CM_ BO_ 2566845479  "Tire Condition";
CM_ BO_ 3221225472  "This is a message for not used signals, created by Vector CANdb++ DBC OLE DB Provider.";

CM_ SG_ 3221225472 pEPS_SAScalibrated "EPS Steering Angle Sensor Calibrated
0x00 = Not Calibrated
0x01 = Calibrated
0x10 = Not Available
0x11 = Error";
CM_ SG_ 3221225472 pEPS_OpStatus "EPS Operation Status";
CM_ SG_ 3221225472 pEPS_OpMode "EPS Operation Mode
2 = Standard Operation
5 = Command Operation";
CM_ SG_ 3221225472 pEPS_ShaftVelocity "Steering Shaft Angular Velocity";
CM_ SG_ 3221225472 pEPS_ShaftPosition "Steering Shaft Angular Position";
CM_ SG_ 3221225472 DM_SPN2 "SPN, second byte of SPN";
CM_ SG_ 3221225472 DM_SPN3 "SPN, 3 most significant bits";
CM_ SG_ 3221225472 DM_SPN1 "SPN, 8 lease significant bits";
CM_ SG_ 3221225472 DM_FailureModeIdentifier "The FMI defines the type of failure detected in the subsystem identified by an SPN.";
CM_ SG_ 3221225472 DM_OccurenceCount "The 7 bit occurence count field contains the number of times a fault has gone from active to previously active.";
CM_ SG_ 2566846298 NetBatteryCurrent "Net flow of electrical current into/out of the battery or batteries.";
CM_ SG_ 2566846298 AlternatorCurrent "Measure of electrical current flow from the alternator. Alternator Current (High Range/Resolution) parameter SPN 1795 has a higher range and resolution of the same parameter.";
CM_ SG_ 2566846298 ChargingSystemPotential "Electrical potential measured at the charging system output. The charging system may be any device charging the batteries. This includes alternators, generators, solid state charger,
and other charging devices.";
CM_ SG_ 2566846298 BatteryPotential "This parameter measures the first souce of battery potential as measured at the input of the ECM/actuator etc. coming from one or more batteries, irrespective of the distance between the component
and the battery.";
CM_ SG_ 2566846298 KeyswitchBatteryPotential "Battery potential measured at the input of the electronic control unit supplied through a keyswitch or similar switching device.";
CM_ SG_ 2633984602 pHeatedGripEnable "Indicates if the controller broadcasting this SPN is calibrated to support vehicle speed limit 3";
CM_ SG_ 2633984602 pSideStandStatus "Status of the side stand switch of a motorcycle";
CM_ SG_ 2633984602 pTetherSwitchStatus "Status of the Tether Switch";
CM_ SG_ 2633984602 pLowFuelIndicatorStatus "Broadcasting the status of the fuel level for user indication.";
CM_ SG_ 2633984602 pOperatorNotInOperatingStation "Status of Operator presence in a vehicle";
CM_ SG_ 2633984602 pParkBrakeIndicatorStatus "Broadcasting the status of the park brake for user indication";
CM_ SG_ 2633984602 pADCRequested "Broadcasting the status of the users request for ADC mode";
CM_ SG_ 2633984602 pAWDModeRequested "Broadcasting the status of the users request for AWD mode";
CM_ SG_ 2633984602 pRWDModeRequested "Broadcasting the status of the users request for RWD mode";
CM_ SG_ 2633984602 pTurfModeRequested "Broadcasting the status of the users request for TURF mode";
CM_ SG_ 2633984602 pADCStatus "Broadcasting the status of the ADC (active indicates the solenoid is powered)";
CM_ SG_ 2633984602 pTreadleNeutralStatus "Broadcasting the status of the switch indicating the treadle is/is not in the Neutral position";
CM_ SG_ 2633984602 pTreadleReverseStatus "Broadcasting the status of the switch indicating the treadle is/is not in the Reverse position";
CM_ SG_ 2633984602 pSecurityLightStatus "Broadcasting the status of the security system for user indication";
CM_ SG_ 2633984602 pHighBeamIndicatorStatus "Broadcasting the status of the high beam headlight for user indication";
CM_ SG_ 2633984602 pHeatedGripsPercentage "Heated Grips Percent On, 0% is Off and 100% is the maximum heat";
CM_ SG_ 2633984602 pCruiseControlSetStatus "Broadcasting the status of the Cruise Control Set Status for user indication";
CM_ SG_ 2633984602 pSeatBeltIndicatorStatus "Broadcasting the status of the seat belt for user indication";
CM_ SG_ 2365530458 pChecksum_520571 "Used to verify the signal path from the transmitting device to the receiving device. The message checksum is calculated using the first 7 data bytes, the message counter and the bytes of the message identifier.";
CM_ SG_ 2365530458 pMessageCounter_520570 "Message counter that increments by one for each transmission from 0 to 15 and then rolls over.
The message counter is used to detect situations where the transmitting ECU malfunction repeats the same frame all the time";
CM_ SG_ 2365530458 pEngineSpeed_520569 "Indication of the current engine or motor speed.";
CM_ SG_ 2365530458 pEngineTorque_Driver_Demanded "Indication of the driver demanded engine or motor output torque.";
CM_ SG_ 2365530458 pEngineTorque "Indication of the actual engine or motor output torque.  Estimated torque is acceptable if actual is not available.";
CM_ SG_ 2365530458 pSource_Address_Ctrling_Device "Indication of the source address of the device from which the torque/speed request is being honored.  If an internal torque request is being honored, the controller will transmit its own source address.";
CM_ SG_ 2566843994 EngineCoolantTemperature "Temperature of the liquid in the engine cooling system.";
CM_ SG_ 2566843994 EngFuelTemperature1 "Temperature of fuel (or gass) passing through the first fuel control system. Se SPN 3468 for the second control system.";
CM_ SG_ 2566843994 EngineOilTemperature1 "Temperature of the engine lubricant.";
CM_ SG_ 2566843994 EngTurboOilTemperature "Temperature of the turbocharger lubricant.";
CM_ SG_ 2566843994 EngineIntercoolerTemperature "Not approved for use at Polaris at this time.";
CM_ SG_ 2566843994 EngineIntercoolerThermosatOpen "Not approved for use at Polaris at this time.
(The current position of the thermostat used to regulate the temperature of the engine intercooler.)";
CM_ SG_ 2566841690 EngTotalHoursOfOper "Accumulated time of operation of engine";
CM_ SG_ 2566841690 TotalEngineRevolutions "(Accumulated number of revolutions of engine crankshaft during its operation)";
CM_ SG_ 2566876762 pEngineOilPressureStatus "Pressure Status of the Engine Oil";
CM_ SG_ 2566876762 pHydraulicOilPressureStatus "Pressure Status of the Hydraulic Oil Pressure";
CM_ SG_ 2566876762 pHydraulicOilTempStatus "Status of the hydraulic oil temperature";
CM_ SG_ 2566876672 pEngineOilPressureStatus "Pressure Status of the Engine Oil";
CM_ SG_ 2566876672 pHydraulicOilPressureStatus "Pressure Status of the Hydraulic Oil Pressure";
CM_ SG_ 2566876672 pHydraulicOilTempStatus "Status of the hydraulic oil temperature";
CM_ SG_ 2365553933 Checksum "Used to verify the signal path from the transmitting device to the receiving device. The message checksum is
calculated using the first 7 data bytes, the message counter and the bytes of the message identifier";
CM_ SG_ 2365553933 pActualBrakingApplication "Actual braking application in percent of braking pressure available";
CM_ SG_ 2365553933 pRequestedBrakingApplication "Requested Braking Application in Percent of Breaking Pressure Available";
CM_ SG_ 2565866755 TransmissionSelectedGear "The gear that the transmission will attempt to achieve during the current shift if a shift is in progress,
or the next shift if one is pending";
CM_ SG_ 2565866755 TransmissionActualGearRatio "Actual ratio of input shaft speed to output shaft speed";
CM_ SG_ 2565866755 TransmissionCurrentGear "The gear currently engaged in the transmission or the last gear engaged while the transmission is in
the process of shifting to the new or selected gear";
CM_ SG_ 2565866755 TransmissionRqstedRange "Range selected by the operator.";
CM_ SG_ 2565866755 TransmissionCurrentRange "Range currently being commanded by the transmission control system.";
CM_ SG_ 2566844675 pCruiseCntrlCounter "Rolling Counter (ensures updated message is used).";
CM_ SG_ 2566844675 TwoSpeedAxleSwitch "Switch signal which indicates the current axle range.";
CM_ SG_ 2566844675 ParkingBrakeSwitch "Switch signal which indicates when the parking brake is set. In general the switch actuated by the operator's park brake control,
whether a pedal, lever, or other control mechanism.";
CM_ SG_ 2566844675 Wheel_BasedVehicleSpeed "Speed of the vehicle as calculated from wheel or tailshaft speed.";
CM_ SG_ 2566844675 CruiseCtrlActive "Cruise control is switched on.  It is not ensured that the engine is controlled by cruise control, as in the case of a large driver's demand the engine is controlled by the driver while
cruise control is active.";
CM_ SG_ 2566844675 CruiseCtrlEnableSwitch "Switch signal which indicates that it is possible to manage the cruise control function";
CM_ SG_ 2566844675 BrakeSwitch "Switch signal which indicates that the driver operated brake foot pedal is being pressed";
CM_ SG_ 2566844675 ClutchSwitch "Switch signal which indicates that the clutch pedal is being pressed.  It is necessary for a safe drivetrain behavior that the clutch switch is set before the clutch is opened (cruise control function).";
CM_ SG_ 2566844675 CruiseCtrlSetSwitch "Switch signal of the cruise control activator which indicates that the activator is in the position 'set'.";
CM_ SG_ 2566844675 CruiseCtrlCoastSwitch "Switch signal of the cruise control activator which indicates that the activator is in the position 'coast'";
CM_ SG_ 2566844675 CruiseCtrlResumeSwitch "Switch signal of the cruise control activator which indicates that the activator is in the position 'resume'";
CM_ SG_ 2566844675 CruiseCtrlAccelerateSwitch "Switch signal of the cruise control activator which indicates that the activator is in the position 'accelerate'";
CM_ SG_ 2566844675 CruiseCtrlSetSpeed "Value of set (chosen) velocity of velocity control system.";
CM_ SG_ 2566844675 pOdometerDriveBit "Alternate state (A->B, B->A) each time the vehicle has moved a defined distance (currently 40m).";
CM_ SG_ 2566844675 CruiseCtrlPauseSw "Switch signal which indicates the positon of the Cruise Control Pause Switch used on Remote Cruise Control applications. The Cruise Control Pause Switch signal temporarily
disables the Cruise Control function.";
CM_ SG_ 2566844675 pCCChecksum "XOR of bytes 0-6 (ensures data is valid before use)";
CM_ SG_ 2566844675 pCruiseEnableStatus "The Cruise Control System has been enabled by the operator.  (Amber Light)";
CM_ SG_ 2231304282 pEPCU_1_Speed_Limit "Checksum ensures data is valid before use.";
CM_ SG_ 2231304282 pEPCU_1_Counter_Torque_Limit "Checksum ensures data is valid before use.";
CM_ SG_ 2231304282 pEPCU_1_Torque_Demand "Checksum ensures data is valid before use.";
CM_ SG_ 2231304282 pEPCU_1_Control_Mode "Checksum ensures data is valid before use.";
CM_ SG_ 2231304282 pEPCU_1_Message_Counter "Checksum ensures data is valid before use.";
CM_ SG_ 2231304282 pEPCU_1_Checksum "Checksum ensures data is valid before use.";
CM_ SG_ 2231309146 pEPCU_1_Speed_Limit "Checksum ensures data is valid before use.";
CM_ SG_ 2231309146 pEPCU_1_Counter_Torque_Limit "Checksum ensures data is valid before use.";
CM_ SG_ 2231309146 pEPCU_1_Torque_Demand "Checksum ensures data is valid before use.";
CM_ SG_ 2231309146 pEPCU_1_Control_Mode "Checksum ensures data is valid before use.";
CM_ SG_ 2231309146 pEPCU_1_Message_Counter "Checksum ensures data is valid before use.";
CM_ SG_ 2231309146 pEPCU_1_Checksum "Checksum ensures data is valid before use.";
CM_ SG_ 2365525594 WATT_pPack_Voltage "The voltage of the battery pack monitored by the Battery Management Controller (BMC).";
CM_ SG_ 2365525594 WATT_pPack_Current "The current of the battery pack monitored by the Battery Management Controller (BMC).";
CM_ SG_ 2365525594 WATT_pDischarge_Limit "The discharge limit of the battery pack monitored by the Battery Management Controller (BMC).";
CM_ SG_ 2365525594 WATT_pCharge_Limit "The Charge limit of the battery pack monitored by the Battery Management Controller (BMC).";
CM_ SG_ 2365525594 WATT_pBMC_Pwr_Msg_Check_Seq "Checksum ensures data is valid before use.";
CM_ SG_ 2566878554 pChecksum_524123 "Used to verify the signal path from the transmitting device to the receiving device. The message checksum is calculated using the first 7 data bytes, the message counter and the bytes of the message identifier.";
CM_ SG_ 2566878554 pMessageCounter_524122 "The message counter is used to detect situations where the transmitting ECU malfunction repeats the same frame all the time";
CM_ SG_ 2566878554 pOperationMode "Status of Manned or Remote Vehicle Operation Mode";
CM_ SG_ 2566878554 pStartStopCmd "Commanded Status of the Start Button";
CM_ SG_ 2566878554 pNorm_Acc_Pos_520354 "Indication of the current accelerator pedal position normalized to 0 to 100 %.  Commanded accelerator position as a percent of maximum accelerator position. ";
CM_ SG_ 2566844762 TwoSpeedAxleSwitch "Switch signal which indicates the current axle range.";
CM_ SG_ 2566844762 ParkingBrakeSwitch "Switch signal which indicates when the parking brake is set. In general the switch actuated by the operator's park brake control,
whether a pedal, lever, or other control mechanism.";
CM_ SG_ 2566844762 Wheel_BasedVehicleSpeed "Speed of the vehicle as calculated from wheel or tailshaft speed.";
CM_ SG_ 2566844762 CruiseCtrlActive "Cruise control is switched on.  It is not ensured that the engine is controlled by cruise control, as in the case of a large driver's demand the engine is controlled by the driver while
cruise control is active.";
CM_ SG_ 2566844762 CruiseCtrlEnableSwitch "Switch signal which indicates that it is possible to manage the cruise control function";
CM_ SG_ 2566844762 BrakeSwitch "Switch signal which indicates that the driver operated brake foot pedal is being pressed";
CM_ SG_ 2566844762 ClutchSwitch "Switch signal which indicates that the clutch pedal is being pressed.  It is necessary for a safe drivetrain behavior that the clutch switch is set before the clutch is opened (cruise control function).";
CM_ SG_ 2566844762 CruiseCtrlSetSwitch "Switch signal of the cruise control activator which indicates that the activator is in the position 'set'.";
CM_ SG_ 2566844762 CruiseCtrlCoastSwitch "Switch signal of the cruise control activator which indicates that the activator is in the position 'coast'";
CM_ SG_ 2566844762 CruiseCtrlResumeSwitch "Switch signal of the cruise control activator which indicates that the activator is in the position 'resume'";
CM_ SG_ 2566844762 CruiseCtrlAccelerateSwitch "Switch signal of the cruise control activator which indicates that the activator is in the position 'accelerate'";
CM_ SG_ 2566844762 CruiseCtrlSetSpeed "Value of set (chosen) velocity of velocity control system.";
CM_ SG_ 2566844762 pOdometerDriveBit "Alternate state (A->B, B->A) each time the vehicle has moved a defined distance (currently 40m).";
CM_ SG_ 2566844762 CruiseCtrlPauseSw "Switch signal which indicates the positon of the Cruise Control Pause Switch used on Remote Cruise Control applications. The Cruise Control Pause Switch signal temporarily
disables the Cruise Control function.";
CM_ SG_ 2566844762 pCCMessageCounter "Rolling Counter (ensures updated message is used)";
CM_ SG_ 2566844762 pCCChecksum "XOR of bytes 0-6 (ensures data is valid before use)";
CM_ SG_ 2566844762 pCruiseEnableStatus "The Cruise Control System has been enabled by the operator.  (Amber Light)";
CM_ SG_ 2566887489 pRiderWeightRearLeft "Weight of occupant in rear left seat in kilograms. FE indicates Error. FF indicates data not available.";
CM_ SG_ 2566887489 pBoxLoadWeight "Weight of load in box in kilograms. FE indicates Error. FF indicates data not available.";
CM_ SG_ 2566887489 pRiderWeightRearRight "Weight of occupant in rear right seat in kilograms. FE indicates Error. FF indicates data not available.";
CM_ SG_ 2566887489 pRiderWeightMidRight "Weight of occupant in mid right seat in kilograms. FE indicates Error. FF indicates data not available.";
CM_ SG_ 2566887489 pRiderWeightMidLeft "Weight of occupant in mid left seat in kilograms. FE indicates Error. FF indicates data not available.";
CM_ SG_ 2566887489 pRiderWeightFrontRight "Weight of occupant in front right seat in kilograms. FE indicates Error. FF indicates data not available.";
CM_ SG_ 2566887489 pRiderWeightFrontLeft "Weight of occupant in front left seat in kilograms. FE indicates Error. FF indicates data not available.";
CM_ SG_ 2566853722 pRangeToEmptyEV "Calculated range on remaining electrical power";
CM_ SG_ 2566853722 pEfficiencyEV "Calculated efficiency of an electric powertrain vehicle.";
CM_ SG_ 2365554060 Checksum "Used to verify the signal path from the transmitting device to the receiving device. The message checksum is
calculated using the first 7 data bytes, the message counter and the bytes of the message identifier";
CM_ SG_ 2365554060 pActualBrakingApplication "Actual braking application in percent of braking pressure available";
CM_ SG_ 2365554060 pRequestedBrakingApplication "Requested Braking Application in Percent of Breaking Pressure Available";
CM_ SG_ 2566877965 pEPS_CommandedVar2 "EPS Mode 5: Var2 = Shaft Speed (deg/s)";
CM_ SG_ 2566877965 pEPS_CommandedVar1 "EPS Mode 5 and Mode 16: Var1 = Shaft Position (deg)";
CM_ SG_ 2566877965 pEPS_OpModeCommanded "EPS Mode:
2 - Torque Assist
5 - Command Mode
16 - Set Position";
CM_ SG_ 2365526260 WATT_pTractionBat_Msg_Check_Seq "Checksum ensures data is valid before use.";
CM_ SG_ 2365526260 WATT_pSOH "The State of Health (SOH) – percent of the battery’s nominal capacity remaining due to aging effects – of the battery pack monitored by the Battery Management Controller (BMC).";
CM_ SG_ 2365526260 WATT_pK_Battemp "The percent of energy capacity at 25°C and current State of Health (SOH) that is available at useful discharge rates at the current battery temperature of the battery pack monitored by the Battery Management Controller (BMC).";
CM_ SG_ 2365526260 WATT_pFloat_State "The status bits indicating the electrolyte level of the battery pack monitored by the Battery Management Controller (BMC).";
CM_ SG_ 2365526260 WATT_pBattery_Temp "The temperature of the battery pack monitored by the Battery Management Controller (BMC).";
CM_ SG_ 2365526259 WATT_pTractionBat_Msg_Check_Seq "Checksum ensures data is valid before use.";
CM_ SG_ 2365526259 WATT_pSOH "The State of Health (SOH) – percent of the battery’s nominal capacity remaining due to aging effects – of the battery pack monitored by the Battery Management Controller (BMC).";
CM_ SG_ 2365526259 WATT_pK_Battemp "The percent of energy capacity at 25°C and current State of Health (SOH) that is available at useful discharge rates at the current battery temperature of the battery pack monitored by the Battery Management Controller (BMC).";
CM_ SG_ 2365526259 WATT_pFloat_State "The status bits indicating the electrolyte level of the battery pack monitored by the Battery Management Controller (BMC).";
CM_ SG_ 2365526259 WATT_pBattery_Temp "The temperature of the battery pack monitored by the Battery Management Controller (BMC).";
CM_ SG_ 2365526516 WATT_pWAKE_State "The state of the BMC’s WAKE input.";
CM_ SG_ 2365526516 WATT_pKEY_State "State signifying the presence of an activated Key switch.";
CM_ SG_ 2365526516 WATT_pDC_DC_State "Operating state of the DC-DC converter controlled by the Battery Management Controller (BMC).";
CM_ SG_ 2365526516 WATT_pBMC_Temp "The temperature of the Battery Management Controller (BMC).";
CM_ SG_ 2365526516 WATT_pBMC_Status_Msg_Check_Seq "Checksum ensures data is valid before use.";
CM_ SG_ 2365526516 WATT_pBalance_State "The state of the BMC in terms of balancing the state of charge of the bottom battery and the top battery.";
CM_ SG_ 2365526516 WATT_pBalance_Error "The error in state of charge existing between the bottom battery and the top battery balanced by the Battery Management Controller (BMC). Positive error corresponds to the lower battery being at a higher state of charge.";
CM_ SG_ 2365526772 pCharger_Status_Counter "Checksum ensures data is valid before use.";
CM_ SG_ 2365526772 WATT_pCharger_Voltage "The voltage output of the battery charger.";
CM_ SG_ 2365526772 WATT_pCharger_Temp "The temperature of the battery charger.";
CM_ SG_ 2365526772 WATT_pCharger_State "State of the battery charging process.";
CM_ SG_ 2365526772 WATT_pCharger_Stat_Msg_Check_Seq "Checksum ensures data is valid before use.";
CM_ SG_ 2365526772 WATT_pCharger_Current "The output current of the battery charger.";
CM_ SG_ 2365526772 WATT_pAC_Status "State signifying the presence of an AC Supply on the battery charger.";
CM_ SG_ 2365526004 WATT_pWh_In_Since_Key "The capacity in Watt hours delivered to the battery pack monitored by the Battery Management Controller (BMC), negative for net energy removed from the battery pack.";
CM_ SG_ 2365526004 WATT_pSOC "The State of Charge (SOC) – percent of battery capacity available at current battery health and temperature – of the battery pack monitored by the Battery Management Controller (BMC).";
CM_ SG_ 2365526004 WATT_pEnergy_Msg_Check_Seq "Checksum ensures data is valid before use.";
CM_ SG_ 2365526004 WATT_pAvailable_Wh "The capacity, in Watt hours, of the battery pack monitored by the Battery Management Controller (BMC).";
CM_ SG_ 2365526515 WATT_pWAKE_State "The state of the BMC’s WAKE input.";
CM_ SG_ 2365526515 WATT_pKEY_State "State signifying the presence of an activated Key switch.";
CM_ SG_ 2365526515 WATT_pDC_DC_State "Operating state of the DC-DC converter controlled by the Battery Management Controller (BMC).";
CM_ SG_ 2365526515 WATT_pBMC_Temp "The temperature of the Battery Management Controller (BMC).";
CM_ SG_ 2365526515 WATT_pBMC_Status_Msg_Check_Seq "Checksum ensures data is valid before use.";
CM_ SG_ 2365526515 WATT_pBalance_State "The state of the BMC in terms of balancing the state of charge of the bottom battery and the top battery.";
CM_ SG_ 2365526515 WATT_pBalance_Error "The error in state of charge existing between the bottom battery and the top battery balanced by the Battery Management Controller (BMC). Positive error corresponds to the lower battery being at a higher state of charge.";
CM_ SG_ 2365526771 pCharger_Status_Counter "Checksum ensures data is valid before use.";
CM_ SG_ 2365526771 WATT_pCharger_Voltage "The voltage output of the battery charger.";
CM_ SG_ 2365526771 WATT_pCharger_Temp "The temperature of the battery charger.";
CM_ SG_ 2365526771 WATT_pCharger_State "State of the battery charging process.";
CM_ SG_ 2365526771 WATT_pCharger_Stat_Msg_Check_Seq "Checksum ensures data is valid before use.";
CM_ SG_ 2365526771 WATT_pCharger_Current "The output current of the battery charger.";
CM_ SG_ 2365526771 WATT_pAC_Status "State signifying the presence of an AC Supply on the battery charger.";
CM_ SG_ 2365526003 WATT_pWh_In_Since_Key "The capacity in Watt hours delivered to the battery pack monitored by the Battery Management Controller (BMC), negative for net energy removed from the battery pack.";
CM_ SG_ 2365526003 WATT_pSOC "The State of Charge (SOC) – percent of battery capacity available at current battery health and temperature – of the battery pack monitored by the Battery Management Controller (BMC).";
CM_ SG_ 2365526003 WATT_pEnergy_Msg_Check_Seq "Checksum ensures data is valid before use.";
CM_ SG_ 2365526003 WATT_pAvailable_Wh "The capacity, in Watt hours, of the battery pack monitored by the Battery Management Controller (BMC).";
CM_ SG_ 2298415094 WATT_pUpper_Available_Torque "The maximum torque available for accelerating in the positive direction. In overspeed conditions the upper available torque may be negative.";
CM_ SG_ 2298415094 WATT_pPerformance_State "Bits dictating the state of the Electric Propulsion Control Unit or Auxiliary Power Unit from which the message is sent.";
CM_ SG_ 2298415094 WATT_pPerformance_Msg_Check_Seq "Checksum ensures data is valid before use.";
CM_ SG_ 2298415094 WATT_pLower_Available_Torque "The maximum torque available in the reverse direction. Lower available torque is normally negative but can be positive in an negative overspeed condition.";
CM_ SG_ 2298415094 WATT_pActual_Motor_Velocity "Actual RPM of the Electric Propulsion Control Unit or Auxiliary Power Unit from which the message is sent.";
CM_ SG_ 2298415094 WATT_pActual_Motor_torque "The actual motor torque output by the Electric Propulsion Control Unit or Auxiliary Power Unit from which the message is sent.";
CM_ SG_ 2298415095 WATT_pUpper_Available_Torque "The maximum torque available for accelerating in the positive direction. In overspeed conditions the upper available torque may be negative.";
CM_ SG_ 2298415095 WATT_pPerformance_State "Bits dictating the state of the Electric Propulsion Control Unit or Auxiliary Power Unit from which the message is sent.";
CM_ SG_ 2298415095 WATT_pPerformance_Msg_Check_Seq "Checksum ensures data is valid before use.";
CM_ SG_ 2298415095 WATT_pLower_Available_Torque "The maximum torque available in the reverse direction. Lower available torque is normally negative but can be positive in an negative overspeed condition.";
CM_ SG_ 2298415095 WATT_pActual_Motor_Velocity "Actual RPM of the Electric Propulsion Control Unit or Auxiliary Power Unit from which the message is sent.";
CM_ SG_ 2298415090 WATT_pUpper_Available_Torque "The maximum torque available for accelerating in the positive direction. In overspeed conditions the upper available torque may be negative.";
CM_ SG_ 2298415090 WATT_pPerformance_State "Bits dictating the state of the Electric Propulsion Control Unit or Auxiliary Power Unit from which the message is sent.";
CM_ SG_ 2298415090 WATT_pPerformance_Msg_Check_Seq "Checksum ensures data is valid before use.";
CM_ SG_ 2298415090 WATT_pLower_Available_Torque "The maximum torque available in the reverse direction. Lower available torque is normally negative but can be positive in an negative overspeed condition.";
CM_ SG_ 2298415090 WATT_pActual_Motor_Velocity "Actual RPM of the Electric Propulsion Control Unit or Auxiliary Power Unit from which the message is sent.";
CM_ SG_ 2298415090 WATT_pActual_Motor_torque "The actual motor torque output by the Electric Propulsion Control Unit or Auxiliary Power Unit from which the message is sent.";
CM_ SG_ 2298415089 WATT_pUpper_Available_Torque "The maximum torque available for accelerating in the positive direction. In overspeed conditions the upper available torque may be negative.";
CM_ SG_ 2298415089 WATT_pPerformance_State "Bits dictating the state of the Electric Propulsion Control Unit or Auxiliary Power Unit from which the message is sent.";
CM_ SG_ 2298415089 WATT_pPerformance_Msg_Check_Seq "Checksum ensures data is valid before use.";
CM_ SG_ 2298415089 WATT_pActual_Motor_Velocity "Actual RPM of the Electric Propulsion Control Unit or Auxiliary Power Unit from which the message is sent.";
CM_ SG_ 2298415089 WATT_pActual_Motor_torque "The actual motor torque output by the Electric Propulsion Control Unit or Auxiliary Power Unit from which the message is sent.";
CM_ SG_ 2298415088 WATT_pUpper_Available_Torque "The maximum torque available for accelerating in the positive direction. In overspeed conditions the upper available torque may be negative.";
CM_ SG_ 2298415088 WATT_pPerformance_State "Bits dictating the state of the Electric Propulsion Control Unit or Auxiliary Power Unit from which the message is sent.";
CM_ SG_ 2298415088 WATT_pPerformance_Msg_Check_Seq "Checksum ensures data is valid before use.";
CM_ SG_ 2298415088 WATT_pLower_Available_Torque "The maximum torque available in the reverse direction. Lower available torque is normally negative but can be positive in an negative overspeed condition.";
CM_ SG_ 2298415088 WATT_pActual_Motor_Velocity "Actual RPM of the Electric Propulsion Control Unit or Auxiliary Power Unit from which the message is sent.";
CM_ SG_ 2298415088 WATT_pActual_Motor_torque "The actual motor torque output by the Electric Propulsion Control Unit or Auxiliary Power Unit from which the message is sent.";
CM_ SG_ 2298415087 WATT_pUpper_Available_Torque "The maximum torque available for accelerating in the positive direction. In overspeed conditions the upper available torque may be negative.";
CM_ SG_ 2298415087 WATT_pPerformance_State "Bits dictating the state of the Electric Propulsion Control Unit or Auxiliary Power Unit from which the message is sent.";
CM_ SG_ 2298415087 WATT_pPerformance_Msg_Check_Seq "Checksum ensures data is valid before use.";
CM_ SG_ 2298415087 WATT_pLower_Available_Torque "The maximum torque available in the reverse direction. Lower available torque is normally negative but can be positive in an negative overspeed condition.";
CM_ SG_ 2298415087 WATT_pActual_Motor_Velocity "Actual RPM of the Electric Propulsion Control Unit or Auxiliary Power Unit from which the message is sent.";
CM_ SG_ 2298415087 WATT_pActual_Motor_torque "The actual motor torque output by the Electric Propulsion Control Unit or Auxiliary Power Unit from which the message is sent.";
CM_ SG_ 2566834735 DM_FlashRedStopLamp "Flash status of the Red Stop Lamp";
CM_ SG_ 2566834735 DM_FlashProtectLamp "Flash status of the Stop Protect Lamp";
CM_ SG_ 2566834735 DM_FlashMalfuncIndicatorLamp "Flash status of the Malfunction Indicator Lamp";
CM_ SG_ 2566834735 DM_FlashAmberWarningLamp "Flash status of the Amber Warning Lamp";
CM_ SG_ 2566834735 DTC5 "Diagnostic Trouble Code";
CM_ SG_ 2566834735 DTC4 "Diagnostic Trouble Code";
CM_ SG_ 2566834735 DTC3 "Diagnostic Trouble Code";
CM_ SG_ 2566834735 DTC2 "Diagnostic Trouble Code";
CM_ SG_ 2566834735 DTC1 "Diagnostic Trouble Code";
CM_ SG_ 2566834735 DM_ProtectLampStatus "This lamp is used to relay trouble code informatio that is reporting a problem with a vehicle system that is most
probably not electronic subsystem related.";
CM_ SG_ 2566834735 DM_RedStopLampState "This lamp is uesed to relay trouble code information that is of a severe enought condition that it warrants stopping the vehicle.";
CM_ SG_ 2566834735 DM_AmberWrningLmpStatus "This lamp is used to relay trouble code information that is reporting a problem with the vehicle system but the vehicle need
not be immediately stopped.";
CM_ SG_ 2566834735 DM_MalfuncnIndicatorLampStatus "A lamp used to relay only emissions-related trouble code information.";
CM_ SG_ 2566855680 pRqstdPerFan1DutyCycle "Fan duty cycle";
CM_ SG_ 2566855680 pFan1DirectionCmd "Direction command to the Supplemental Fan";
CM_ SG_ 2566886912 pFleetMgmtDefVehState "Default state of the vehicle after commanded by Fleet Management device";
CM_ SG_ 2566886912 pVehEnblDisbl "Used to command vehicle states; i.e. vehicle enabled or disabled";
CM_ SG_ 2566886912 pUserAuthenticationStatus "Used to indicate user authentication status";
CM_ SG_ 2566886912 pBoundaryStatus "Used to communicate information about boundary proximity";
CM_ SG_ 2566886400 EngineCyldr2IngnitionTmg "Target ignition timing for cylinder 2";
CM_ SG_ 2566886400 EngineCyldr1IgnitionTmg "Target ignition timing for cylinder 1";
CM_ SG_ 2566886400 DesiredLambda "The target lambda value";
CM_ SG_ 2566886400 HighRngEngPerLoad "Percent engine load but with a range high enough to support boosted applications";
CM_ SG_ 2566878227 pEPSShaftVelocity "The rotational velocity of the output shaft of the power steering unit";
CM_ SG_ 2566878227 pEPSShaftPosition "The absolute position of the output shaft of the power steering unit";
CM_ SG_ 2566878227 pEPSSASCalibrated "Indicates the calibration status of the EPS steering angle sensor";
CM_ SG_ 2566878227 pEPSOperationStatus "The operational stutas of the EPS unit";
CM_ SG_ 2566878227 pEPSOperationMode "The mode that the power steering unit is currently functioning in";
CM_ SG_ 2566878987 DL22_BrakeSwitchStatus "0000b – no brake; 0001b – one switch closed/ one open; 0010b – both switches closed ;
0011b – 1101b : reserved; 1110b –error; 1111b - unavailable";
CM_ SG_ 2365553931 Checksum "Used to verify the signal path from the transmitting device to the receiving device. The message checksum is
calculated using the first 7 data bytes, the message counter and the bytes of the message identifier";
CM_ SG_ 2365553931 pActualBrakingApplication "Actual braking application in percent of braking pressure available";
CM_ SG_ 2365553931 pRequestedBrakingApplication "Requested Braking Application in Percent of Breaking Pressure Available";
CM_ SG_ 2566879243 DL_YawRate "Rate of rotation about the vertical axis.  Positive raw rate results when the vehicle turns counter-clockwise.";
CM_ SG_ 2566879243 DL_SteeringWheelAngle "The main operator`s steering wheel angle (on the steering column, not the actual wheel angle). The vehicle being
steered to the left (counterclockwise) results in a positive steering wheel angle.";
CM_ SG_ 2566911015 FI2_ReverseMotorDriveInput "Status of the reverse motor switch input; input is high (open circuit) when the selector lever is in the reverse position and low (closed to ground) when the lever is in the forward position.";
CM_ SG_ 2566913547 DL2_EngineThrottlePosition "The position of the valve used to regulatethe supply of a fluid, usually air or fuel/air mixture, to an engine.";
CM_ SG_ 2566913547 DL2_EngineCoolantTemperature "Temperature of liquid found in engine coolant system.";
CM_ SG_ 2566913547 DL2_EngineAirInletTemperature "Temperature of air entering vehicle air induction system.";
CM_ SG_ 2566913547 DL2_EngIntakeManifoldPressure "Pressure of pre-combustion air found in intake manifold of engine air supply system.";
CM_ SG_ 2566913547 DL2_Boost "Gage pressure of air measured downstream on the compressor discharge side of the turbocharger.";
CM_ SG_ 2566913547 DL2_BarometricPressure "Absolute air pressure of the atmosphere.";
CM_ SG_ 2566913547 DL2_Wheel_BasedVehicleSpeed "Speed of the vehicle as calculated from wheel or tailshaft speed.";
CM_ SG_ 2566913547 DL2_BarometricPressure_Volts "Absolute air pressure of the atmosphere.";
CM_ SG_ 2566901504 DL_CamXAngle "Cam-X Angle (from TDCC-A to Cam-X Edge)";
CM_ SG_ 2566901504 DL_ReferenceCamXAngle "Reference Cam-X Angle (from TDCC-A to Cam-X Edge prior to cam phaser activation)";
CM_ SG_ 2566901248 DL_CamWAngle "Cam-W Angle (from TDCC-A to Cam-W Edge)";
CM_ SG_ 2566901248 DL_ReferenceCamWAngle "Reference Cam-W Angle (from TDCC-A to Cam-W Edge prior to cam phaser activation)";
CM_ SG_ 2566877696 pLeftHandGripTemp "Temperature of the Left Hand grip";
CM_ SG_ 2566877696 pRightHandGripTemp "Temperature of the Right Hand grip";
CM_ SG_ 2566877463 pVolumeUnitsSelected "Active display volume units beased on user selection or auto-configuration.";
CM_ SG_ 2566877463 pTimeUnitsSelected "Active display time units beased on user selection or auto-configuration.";
CM_ SG_ 2566877463 pTemperatureUnitsSelected "Active display temperature units beased on user selection or auto-configuration.";
CM_ SG_ 2566877463 pPressureUnitsSelected "Active display pressure units beased on user selection or auto-configuration.";
CM_ SG_ 2566877463 pHighResTrip2Distance "Secondary distance travled during all or part of a journey.";
CM_ SG_ 2566877463 pDistanceUnitsSelected "Active display distance units beased on user selection or auto-configuration.";
CM_ SG_ 2566877463 pTPMSLearningStatus "Status of the Tire Pressure Monitor System learning process.";
CM_ SG_ 2566877463 pDisplayStatus "Status of the radio display to the radio stating what the display is showing";
CM_ SG_ 2566876711 pEngineOilPressureStatus "Pressure Status of the Engine Oil";
CM_ SG_ 2566876711 pHydraulicOilPressureStatus "Pressure Status of the Hydraulic Oil Pressure";
CM_ SG_ 2566876711 pHydraulicOilTempStatus "Status of the hydraulic oil temperature";
CM_ SG_ 2633984551 pHeatedGripEnable "Indicates if the controller broadcasting this SPN is calibrated to support vehicle speed limit 3";
CM_ SG_ 2633984551 pSideStandStatus "Status of the side stand switch of a motorcycle";
CM_ SG_ 2633984551 pTetherSwitchStatus "Status of the Tether Switch";
CM_ SG_ 2633984551 pLowFuelIndicatorStatus "Broadcasting the status of the fuel level for user indication.";
CM_ SG_ 2633984551 pOperatorNotInOperatingStation "Status of Operator presence in a vehicle";
CM_ SG_ 2633984551 pParkBrakeIndicatorStatus "Broadcasting the status of the park brake for user indication";
CM_ SG_ 2633984551 pADCRequested "Broadcasting the status of the users request for ADC mode";
CM_ SG_ 2633984551 pAWDModeRequested "Broadcasting the status of the users request for AWD mode";
CM_ SG_ 2633984551 pRWDModeRequested "Broadcasting the status of the users request for RWD mode";
CM_ SG_ 2633984551 pTurfModeRequested "Broadcasting the status of the users request for TURF mode";
CM_ SG_ 2633984551 pADCStatus "Broadcasting the status of the ADC (active indicates the solenoid is powered)";
CM_ SG_ 2633984551 pTreadleNeutralStatus "Broadcasting the status of the switch indicating the treadle is/is not in the Neutral position";
CM_ SG_ 2633984551 pTreadleReverseStatus "Broadcasting the status of the switch indicating the treadle is/is not in the Reverse position";
CM_ SG_ 2633984551 pSecurityLightStatus "Broadcasting the status of the security system for user indication";
CM_ SG_ 2633984551 pHighBeamIndicatorStatus "Broadcasting the status of the high beam headlight for user indication";
CM_ SG_ 2633984551 pHeatedGripsPercentage "Heated Grips Percent On, 0% is Off and 100% is the maximum heat";
CM_ SG_ 2633984551 pCruiseControlSetStatus "Broadcasting the status of the Cruise Control Set Status for user indication";
CM_ SG_ 2633984551 pSeatBeltIndicatorStatus "Broadcasting the status of the seat belt for user indication";
CM_ SG_ 2432656679 pOperatorButton29 "Drive Mode - 1()";
CM_ SG_ 2432656679 pOperatorButton1 "Instrument Cluster Control - 1";
CM_ SG_ 2432656679 pOperatorButton2 "Instrument Cluster Control  - 2";
CM_ SG_ 2432656679 pOperatorButton3 "Headlamp - 1 (Low)";
CM_ SG_ 2432656679 pOperatorButton4 "Headlamp - 2 (High)";
CM_ SG_ 2432656679 pOperatorButton5 "Headlamp - 3 (Driving)";
CM_ SG_ 2432656679 pOperatorButton6 "Turn - 1 (Left)";
CM_ SG_ 2432656679 pOperatorButton7 "Turn - 2 (Right)";
CM_ SG_ 2432656679 pOperatorButton8 "Turn - 3 (Cancel)";
CM_ SG_ 2432656679 pOperatorButton9 "Hazard";
CM_ SG_ 2432656679 pOperatorButton10 "Cruise - 1 (On)";
CM_ SG_ 2432656679 pOperatorButton11 "Cruise - 2 (Set)";
CM_ SG_ 2432656679 pOperatorButton12 "Cruise - 3 (Accel)";
CM_ SG_ 2432656679 pOperatorButton13 "Horn";
CM_ SG_ 2432656679 pOperatorButton14 "Start";
CM_ SG_ 2432656679 pOperatorButton15 "Warmer - 1";
CM_ SG_ 2432656679 pOperatorButton16 "Warmer - 2";
CM_ SG_ 2432656679 pOperatorButton17 "Warmer - 3";
CM_ SG_ 2432656679 pOperatorButton18 "Warmer - 4";
CM_ SG_ 2432656679 pOperatorButton19 "Windshield Wiper";
CM_ SG_ 2432656679 pOperatorButton20 "Engine On";
CM_ SG_ 2432656679 pOperatorButton21 "Reverse";
CM_ SG_ 2432656679 pOperatorButton22 "Homelink 1";
CM_ SG_ 2432656679 pOperatorButton23 "Homelink 2";
CM_ SG_ 2432656679 pOperatorButton24 "Throttle Safety Switch - 1";
CM_ SG_ 2432656679 pOperatorButton25 "Windshield - 1 (Up)";
CM_ SG_ 2432656679 pOperatorButton26 "Windshield - 2 (Down)";
CM_ SG_ 2432656679 pOperatorButton27 "Hand Brake Switch";
CM_ SG_ 2432656679 pOperatorButton28 "Clutch Switch";
CM_ SG_ 2432656679 pSideStandStatus "Status of the side stand switch of a motorcycle";
CM_ SG_ 2566845479 TireLocation "Identifies which tire is associated with the parametric data in this PGN.";
CM_ SG_ 2566845479 TirePressure "Pressure at which air is contained in cavity formed by tire and rim.";
CM_ SG_ 2566845479 TireTemperature "Temperature at the surface of the tire sidewall.";
CM_ SG_ 3221225472 HVES1HVBPsvITR_8432 "See HVES1 High-Voltage Bus Passive Isolation Test Status (SPN 8097) for test status and HVES1 High-Voltage Bus Active Isolation Test Command (SPN 8126) for the command to run the test.";
CM_ SG_ 3221225472 HVES1HVBAcvITR_8431 "See HVES1 High-Voltage Bus Active Isolation Test Status (SPN 8096) for test status and HVES1 High-Voltage Bus Active Isolation Test Command (SPN 8125) for the command to run the test.";
CM_ SG_ 3221225472 HVES1LoCellStOChaCellNo_8248 "Identifies the location of the HVES1 Lowest Cell State of Charge (SPN 8084) within the HVES1 Lowest Cell State of Charge Module Number (SPN 8247).";
CM_ SG_ 3221225472 HVES1LoCellStOChaModuNo_8247 "Identifies the location of the HVES1 Highest Cell State of Charge (SPN 8085) within the HVES1 Highest Cell State of Charge Module Number (SPN 8245).";
CM_ SG_ 3221225472 HVES1HiCellStOChaCellNo_8246 "Identifies the location of the HVES1 Highest Cell State of Charge (SPN 8085) within the HVES1 Highest Cell State of Charge Module Number (SPN 8245).";
CM_ SG_ 3221225472 HVES1HiCellStOChaModuNo_8245 "Identifies the location of the module containing the HVES1 Highest Cell State of Charge (SPN 8085).";
CM_ SG_ 3221225472 TranIdleGovrnrFuelingInhbit_7829 "This parameter is a command provided to the Engine Control Module (ECM) from the Transmission Control Module (TCM) to inhibit idle governor fueling in the unlikely event that transmission has detected a failure preventing driveline disengagement.";
CM_ SG_ 3221225472 NumberOfMembersInWorkingSet "The number of members in a particular Working Set.";
CM_ SG_ 3221225472 SourceAddress "Instance of a Source Address listed a Network Message data field.";
CM_ SG_ 3221225472 NncntnuslyMonitoredSystemsStatus "Identifies the non-continuously monitored systems status. Each bit identifies whether a particular test is complete for a given controller.
";
CM_ SG_ 3221225472 NncntnslyMonitoredSystemsSupport "Identifies the non-continuously monitored systems support.
";
CM_ SG_ 3221225472 CntnslyMntrdSystmsSupport_Status "Identifies the continuously monitored system support and status.
";
CM_ SG_ 3221225472 AETCTorqueValue "Engine torque value of the data points in PGN 64912 – Advertised Engine Torque Curve (AETC).";
CM_ SG_ 3221225472 TrailerWeight "Total mass of freight-carrying vehicle designed to be pulled by truck, including the weight of the contents.";
CM_ SG_ 3221225472 ReferenceTirePressSetting "Reference value of the tire pressure setting as basis for the tire pressure monitoring ...";
CM_ SG_ 3221225472 ReferenceTirePress "Reference value of the tire pressure as basis for the tire pressure monitoring ...";
CM_ SG_ 3221225472 TirePressThresholdDetection "Signal indicating the pressure level of the tire.  The levels defined represent different pressure conditions of the tire: 000 Extreme over pressure - The tire pressure is at a level where the safety of the vehicle may be jeopardised.";
CM_ SG_ 3221225472 TireAirLeakageRate "The pressure loss rate of a tire.";
CM_ SG_ 3221225472 CTIWheelEndElectricalFault "Indicates the status of electrical fault on CTI wheel interface.";
CM_ SG_ 3221225472 CTITireStatus "Indicates the status of the tire.";
CM_ SG_ 3221225472 CTIWheelSensorStatus "Indicates whether the wheel is being monitored by the CTI controller.";
CM_ SG_ 3221225472 TireTemp "Temperature at the surface of the tire sidewall.";
CM_ SG_ 3221225472 TirePress "Pressure at which air is contained in cavity formed by tire and rim.";
CM_ SG_ 3221225472 EngTurningGearEngaged "Status signal which indicates that the turning gear is engaged.  The turning gear is used to turn the flywheel/crankshaft, ...";
CM_ SG_ 3221225472 AETCSpeedValue "Engine speed value of the data points in PGN 64912 – Advertised Engine Torque Curve (AETC).";

CM_ BU_ iBooster "13 / 0x0D - iBooster";
CM_ BU_ CIM "140 / 0x8C Communications Interface Module";
CM_ BU_ Right_Hand_Control "134-Left Hand Control";
CM_ BU_ Left_Hand_Control "135-Left Hand Control";
CM_ BU_ GPS "28";
CM_ BU_ VCM "39 - Management Computer #1";
CM_ BU_ IC_2 "167 - Instrument Cluster #2";
CM_ BU_ XM "126";
CM_ BU_ GMRS "124";
CM_ BU_ Radio_CANtool "120";
CM_ BU_ Diagnostic_Tool_Digital_Wrench "249 - Diagnostic Tool (Polaris Digital Wrench)";
CM_ BU_ Information_System_Controller_1 "65";
CM_ BU_ STEERING_CONTROLLER "19 - EPAS";
CM_ BU_ VEHICLE_SECURITY "29";
CM_ BU_ RADIO_Hub "127";
CM_ BU_ ABS "11 - Brake Controller";
CM_ BU_ Battery_Management_Cntrl_2 "244 - Li-ion BMC";
CM_ BU_ Battery_Management_Cntrl_1 "243 - Battery Pack Monitor";
CM_ BU_ Auxiliary_Power_Unit_2 "246";
CM_ BU_ Auxiliary_Power_Unit_1 "247";
CM_ BU_ Electric_Propulsion_Cntrl_Unit_4 "242";
CM_ BU_ Electric_Propulsion_Cntrl_Unit_3 "241";
CM_ BU_ Electric_Propulsion_Cntrl_Unit_2 "240";
CM_ BU_ Electric_Propulsion_Cntrl_Unit_1 "239";
CM_ BU_ ECM "0 - Engine #1";
CM_ BU_ IC "23 - Instrument Cluster";

BA_DEF_ BO_ "GenMsgCycleTime" INT 0 3600000;
BA_DEF_ BO_ "GenMsgCycleTimeFast" INT 0 3600000;
BA_DEF_ BO_ "GenMsgDelayTime" INT 0 1000;
BA_DEF_ BO_ "GenMsgILSupport" ENUM  "No","Yes";
BA_DEF_ BO_ "GenMsgRequestable" INT 0 1;
BA_DEF_ BO_ "GenMsgSendType" ENUM  "cyclic","spontaneous","cyclicIfActive","spontaneousWithDelay","cyclicAndSpontaneous","cyclicAndSpontaneousWithDelay","spontaneousWithRepetition","cyclicIfActiveAndSpontaneousWD";
BA_DEF_ BO_ "GenMsgStartDelayTime" INT 0 100000;
BA_DEF_ BO_ "J1939PGNameSecSrc0Dest3" STRING;
BA_DEF_ BO_ "J1939PGPrio" INT 0 7;
BA_DEF_ BO_ "J1939PGPrioSrc0Dest3" INT 0 7;
BA_DEF_ BO_ "J1939PGRelationDest3Src0" INT 0 254;
BA_DEF_ BO_ "J1939PGRelationSrc0Dest3" INT 0 254;
BA_DEF_ BO_ "J1939PGRepCycleSrc0Dest3" INT -1 65535;
BA_DEF_ BO_ "J1939PGRepTypeSrc0Dest3" INT 0 4;
BA_DEF_ BO_ "J1939PGRepetitionCycle" INT 0 65535;
BA_DEF_ BO_ "J1939PGRepetitionType" ENUM  "always","when active","on request";
BA_DEF_ BO_ "J1939PGtoECUSrc0Dest3" INT 0 254;
BA_DEF_ BO_ "J1939PGtoWSMSrc0Dest3" INT 0 254;
BA_DEF_ BO_ "TpJ1939VarDlc" ENUM  "No","Yes";
BA_DEF_ BO_ "VFrameFormat" ENUM  "StandardCAN","ExtendedCAN","reserved","J1939PG";
BA_DEF_ SG_ "GenSigEVName" STRING;
BA_DEF_ SG_ "GenSigILSupport" ENUM  "No","Yes";
BA_DEF_ SG_ "GenSigSendType" ENUM  "Cyclic","OnWrite","OnWriteWithRepetition","OnChange","OnChangeWithRepetition","IfActive","IfActiveWithRepetition","NoSigSendType";
BA_DEF_ SG_ "GenSigStartValue" INT 0 10000;
BA_DEF_ SG_ "SPN" INT 0 524287;
BA_DEF_ SG_ "SigType" ENUM  "Default","Range","RangeSigned","ASCII","Discrete","Control","ReferencePGN","DTC","StringDelimiter","StringLength","StringLengthControl","MessageCounter","MessageChecksum";
BA_DEF_ SG_ "SystemSignalLongSymbol" STRING;
BA_DEF_ BU_ "ECU" STRING;
BA_DEF_ BU_ "J1939Ecu0Name" STRING;
BA_DEF_ BU_ "J1939Ecu3Name" STRING;
BA_DEF_ BU_ "J1939EcuNr0" INT 0 254;
BA_DEF_ BU_ "J1939EcuNr3" INT 0 254;
BA_DEF_ BU_ "NmJ1939AAC" INT 0 1;
BA_DEF_ BU_ "NmJ1939ECUInstance" INT 0 3;
BA_DEF_ BU_ "NmJ1939Function" INT 0 255;
BA_DEF_ BU_ "NmJ1939FunctionInstance" INT 0 7;
BA_DEF_ BU_ "NmJ1939IdentityNumber" INT 0 2097151;
BA_DEF_ BU_ "NmJ1939IndustryGroup" INT 0 7;
BA_DEF_ BU_ "NmJ1939ManufacturerCode" INT 0 2047;
BA_DEF_ BU_ "NmJ1939System" INT 0 127;
BA_DEF_ BU_ "NmJ1939SystemInstance" INT 0 15;
BA_DEF_ BU_ "NmStationAddress" INT 0 255;
BA_DEF_ "BusType" STRING;
BA_DEF_ "DBName" STRING;
BA_DEF_ "ProtocolType" STRING;
BA_DEF_DEF_ "BusType" "CAN";
BA_DEF_DEF_ "DBName" "";
BA_DEF_DEF_ "ECU" "";
BA_DEF_DEF_ "GenMsgCycleTime" 0;
BA_DEF_DEF_ "GenMsgCycleTimeFast" 0;
BA_DEF_DEF_ "GenMsgDelayTime" 0;
BA_DEF_DEF_ "GenMsgILSupport" "Yes";
BA_DEF_DEF_ "GenMsgRequestable" 1;
BA_DEF_DEF_ "GenMsgSendType" "noMsgSendType";
BA_DEF_DEF_ "GenMsgStartDelayTime" 0;
BA_DEF_DEF_ "GenSigEVName" "Env@Nodename_@Signame";
BA_DEF_DEF_ "GenSigILSupport" "Yes";
BA_DEF_DEF_ "GenSigSendType" "NoSigSendType";
BA_DEF_DEF_ "GenSigStartValue" 0;
BA_DEF_DEF_ "J1939Ecu0Name" "(null)";
BA_DEF_DEF_ "J1939Ecu3Name" "(null)";
BA_DEF_DEF_ "J1939EcuNr0" 254;
BA_DEF_DEF_ "J1939EcuNr3" 254;
BA_DEF_DEF_ "J1939PGNameSecSrc0Dest3" "(null)";
BA_DEF_DEF_ "J1939PGPrio" 6;
BA_DEF_DEF_ "J1939PGPrioSrc0Dest3" 6;
BA_DEF_DEF_ "J1939PGRelationDest3Src0" 254;
BA_DEF_DEF_ "J1939PGRelationSrc0Dest3" 254;
BA_DEF_DEF_ "J1939PGRepCycleSrc0Dest3" -1;
BA_DEF_DEF_ "J1939PGRepTypeSrc0Dest3" 3;
BA_DEF_DEF_ "J1939PGRepetitionCycle" 100;
BA_DEF_DEF_ "J1939PGRepetitionType" "always";
BA_DEF_DEF_ "J1939PGtoECUSrc0Dest3" -1;
BA_DEF_DEF_ "J1939PGtoWSMSrc0Dest3" -1;
BA_DEF_DEF_ "NmJ1939AAC" 0;
BA_DEF_DEF_ "NmJ1939ECUInstance" 0;
BA_DEF_DEF_ "NmJ1939Function" 0;
BA_DEF_DEF_ "NmJ1939FunctionInstance" 0;
BA_DEF_DEF_ "NmJ1939IdentityNumber" 0;
BA_DEF_DEF_ "NmJ1939IndustryGroup" 0;
BA_DEF_DEF_ "NmJ1939ManufacturerCode" 0;
BA_DEF_DEF_ "NmJ1939System" 0;
BA_DEF_DEF_ "NmJ1939SystemInstance" 0;
BA_DEF_DEF_ "NmStationAddress" 254;
BA_DEF_DEF_ "ProtocolType" "J1939";
BA_DEF_DEF_ "SPN" 0;
BA_DEF_DEF_ "SigType" "Default";
BA_DEF_DEF_ "SystemSignalLongSymbol" "";
BA_DEF_DEF_ "TpJ1939VarDlc" "No";
BA_DEF_DEF_ "VFrameFormat" "J1939PG";
BA_ "NmStationAddress" BU_ TCM 3;
BA_ "NmStationAddress" BU_ iBooster 13;
BA_ "NmStationAddress" BU_ HCU 90;
BA_ "NmStationAddress" BU_ CIM 140;
BA_ "NmStationAddress" BU_ SCM 47;
BA_ "NmStationAddress" BU_ Right_Hand_Control 134;
BA_ "NmStationAddress" BU_ Left_Hand_Control 135;
BA_ "NmStationAddress" BU_ GPS 28;
BA_ "NmStationAddress" BU_ VCM 39;
BA_ "NmStationAddress" BU_ IC_2 167;
BA_ "NmStationAddress" BU_ XM 126;
BA_ "NmStationAddress" BU_ GMRS 124;
BA_ "NmStationAddress" BU_ Radio_CANtool 120;
BA_ "NmStationAddress" BU_ Diagnostic_Tool_Digital_Wrench 249;
BA_ "NmStationAddress" BU_ Information_System_Controller_1 65;
BA_ "NmStationAddress" BU_ STEERING_CONTROLLER 19;
BA_ "NmStationAddress" BU_ VEHICLE_SECURITY 29;
BA_ "NmStationAddress" BU_ RADIO_Hub 127;
BA_ "NmStationAddress" BU_ ABS 11;
BA_ "NmStationAddress" BU_ Battery_Management_Cntrl_2 244;
BA_ "NmStationAddress" BU_ Battery_Management_Cntrl_1 243;
BA_ "NmStationAddress" BU_ Auxiliary_Power_Unit_2 246;
BA_ "NmStationAddress" BU_ Auxiliary_Power_Unit_1 247;
BA_ "NmStationAddress" BU_ Electric_Propulsion_Cntrl_Unit_4 242;
BA_ "NmStationAddress" BU_ Electric_Propulsion_Cntrl_Unit_3 241;
BA_ "NmStationAddress" BU_ Electric_Propulsion_Cntrl_Unit_2 240;
BA_ "NmStationAddress" BU_ Electric_Propulsion_Cntrl_Unit_1 239;
BA_ "NmJ1939ManufacturerCode" BU_ ECM 100;
BA_ "NmStationAddress" BU_ ECM 0;
BA_ "NmJ1939Function" BU_ IC 19;
BA_ "NmJ1939ManufacturerCode" BU_ IC 102;
BA_ "NmStationAddress" BU_ IC 23;

BA_ "BusType" ""CAN"";
BA_ "ProtocolType" ""J1939"";

BA_ "GenMsgCycleTime" BO_ 2564292857 100;
BA_ "GenMsgSendType" BO_ 2564292857 0;
BA_ "GenMsgCycleTime" BO_ 2564358393 100;
BA_ "GenMsgCycleTime" BO_ 2566846298 1000;
BA_ "GenMsgSendType" BO_ 2566846298 0;
BA_ "GenMsgCycleTime" BO_ 2633984602 100;
BA_ "GenMsgSendType" BO_ 2633984602 0;
BA_ "GenMsgCycleTime" BO_ 2365530458 10;
BA_ "GenMsgSendType" BO_ 2365530458 0;
BA_ "GenMsgCycleTime" BO_ 2566843994 1000;
BA_ "GenMsgSendType" BO_ 2566843994 0;
BA_ "GenMsgCycleTime" BO_ 2566841690 100;
BA_ "GenMsgCycleTime" BO_ 2566876762 1000;
BA_ "GenMsgSendType" BO_ 2566876762 0;
BA_ "GenMsgCycleTime" BO_ 2566876672 1000;
BA_ "GenMsgSendType" BO_ 2566876672 0;
BA_ "VFrameFormat" BO_ 27 0;
BA_ "VFrameFormat" BO_ 28 0;
BA_ "GenMsgCycleTime" BO_ 2565866755 100;
BA_ "GenMsgSendType" BO_ 2565866755 0;
BA_ "GenMsgCycleTime" BO_ 2566844675 100;
BA_ "GenMsgSendType" BO_ 2566844675 4.90833586961908E-316;
BA_ "GenMsgCycleTime" BO_ 2231304282 5000;
BA_ "GenMsgSendType" BO_ 2231304282 4;
BA_ "GenMsgCycleTime" BO_ 2231309146 5000;
BA_ "GenMsgSendType" BO_ 2231309146 4;
BA_ "GenMsgCycleTime" BO_ 2365525594 10;
BA_ "GenMsgSendType" BO_ 2365525594 0;
BA_ "GenMsgCycleTime" BO_ 2566878554 200;
BA_ "GenMsgCycleTimeFast" BO_ 2566878554 10;
BA_ "GenMsgSendType" BO_ 2566878554 4;
BA_ "GenMsgCycleTime" BO_ 2566844762 100;
BA_ "GenMsgSendType" BO_ 2566844762 0;
BA_ "GenMsgCycleTime" BO_ 2566887489 100;
BA_ "GenMsgCycleTimeFast" BO_ 2566887489 100;
BA_ "GenMsgSendType" BO_ 2566887489 4;
BA_ "GenMsgCycleTime" BO_ 2566853722 100;
BA_ "GenMsgSendType" BO_ 2566853722 0;
BA_ "GenMsgCycleTime" BO_ 2365554060 10;
BA_ "GenMsgCycleTime" BO_ 2566877965 10;
BA_ "GenMsgCycleTime" BO_ 2365526260 1000;
BA_ "GenMsgSendType" BO_ 2365526260 0;
BA_ "GenMsgCycleTime" BO_ 2365526259 1000;
BA_ "GenMsgSendType" BO_ 2365526259 0;
BA_ "GenMsgCycleTime" BO_ 2365526516 100;
BA_ "GenMsgSendType" BO_ 2365526516 0;
BA_ "GenMsgCycleTime" BO_ 2365526772 100;
BA_ "GenMsgSendType" BO_ 2365526772 0;
BA_ "GenMsgCycleTime" BO_ 2365526004 100;
BA_ "GenMsgSendType" BO_ 2365526004 0;
BA_ "GenMsgCycleTime" BO_ 2365526515 100;
BA_ "GenMsgSendType" BO_ 2365526515 0;
BA_ "GenMsgCycleTime" BO_ 2365526771 100;
BA_ "GenMsgSendType" BO_ 2365526771 0;
BA_ "GenMsgCycleTime" BO_ 2365526003 100;
BA_ "GenMsgSendType" BO_ 2365526003 0;
BA_ "GenMsgCycleTime" BO_ 2298415094 10;
BA_ "GenMsgSendType" BO_ 2298415094 0;
BA_ "GenMsgCycleTime" BO_ 2298415095 10;
BA_ "GenMsgSendType" BO_ 2298415095 0;
BA_ "GenMsgCycleTime" BO_ 2298415090 10;
BA_ "GenMsgSendType" BO_ 2298415090 0;
BA_ "GenMsgCycleTime" BO_ 2298415089 10;
BA_ "GenMsgSendType" BO_ 2298415089 0;
BA_ "GenMsgCycleTime" BO_ 2298415088 10;
BA_ "GenMsgSendType" BO_ 2298415088 0;
BA_ "GenMsgCycleTime" BO_ 2298415087 10;
BA_ "GenMsgSendType" BO_ 2298415087 0;
BA_ "GenMsgCycleTime" BO_ 2566834735 100;
BA_ "GenMsgCycleTime" BO_ 2566854912 100;
BA_ "GenMsgSendType" BO_ 2566854912 0;
BA_ "GenMsgCycleTime" BO_ 2566855680 1000;
BA_ "GenMsgSendType" BO_ 2566855680 0;
BA_ "GenMsgCycleTime" BO_ 2566886912 1000;
BA_ "GenMsgSendType" BO_ 2566886912 0;
BA_ "GenMsgCycleTime" BO_ 2566886400 100;
BA_ "GenMsgSendType" BO_ 2566886400 0;
BA_ "GenMsgCycleTime" BO_ 2566878227 100;
BA_ "GenMsgSendType" BO_ 2566878227 0;
BA_ "GenMsgCycleTime" BO_ 2566878987 20;
BA_ "GenMsgSendType" BO_ 2566878987 0;
BA_ "GenMsgCycleTime" BO_ 2566907687 100;
BA_ "GenMsgSendType" BO_ 2566907687 0;
BA_ "GenMsgCycleTime" BO_ 2566907943 100;
BA_ "GenMsgSendType" BO_ 2566907943 0;
BA_ "GenMsgCycleTime" BO_ 2566910247 100;
BA_ "GenMsgSendType" BO_ 2566910247 0;
BA_ "GenMsgCycleTime" BO_ 2566910503 100;
BA_ "GenMsgSendType" BO_ 2566910503 0;
BA_ "GenMsgCycleTime" BO_ 2566910759 100;
BA_ "GenMsgSendType" BO_ 2566910759 0;
BA_ "GenMsgCycleTime" BO_ 2566911015 100;
BA_ "GenMsgSendType" BO_ 2566911015 0;
BA_ "GenMsgCycleTime" BO_ 2566911271 100;
BA_ "GenMsgSendType" BO_ 2566911271 0;
BA_ "GenMsgCycleTime" BO_ 2566913547 100;
BA_ "GenMsgSendType" BO_ 2566913547 0;
BA_ "GenMsgCycleTime" BO_ 2566912551 100;
BA_ "GenMsgSendType" BO_ 2566912551 0;
BA_ "GenMsgCycleTime" BO_ 2566908427 100;
BA_ "GenMsgSendType" BO_ 2566908427 0;
BA_ "GenMsgCycleTime" BO_ 2566907392 100;
BA_ "GenMsgSendType" BO_ 2566907392 0;
BA_ "GenMsgCycleTime" BO_ 2566906880 100;
BA_ "GenMsgSendType" BO_ 2566906880 0;
BA_ "GenMsgCycleTime" BO_ 2566906624 100;
BA_ "GenMsgSendType" BO_ 2566906624 0;
BA_ "GenMsgCycleTime" BO_ 2566906368 100;
BA_ "GenMsgSendType" BO_ 2566906368 0;
BA_ "GenMsgCycleTime" BO_ 2566906112 100;
BA_ "GenMsgSendType" BO_ 2566906112 0;
BA_ "GenMsgCycleTime" BO_ 2566905344 100;
BA_ "GenMsgSendType" BO_ 2566905344 0;
BA_ "GenMsgCycleTime" BO_ 2566904064 100;
BA_ "GenMsgSendType" BO_ 2566904064 0;
BA_ "GenMsgCycleTime" BO_ 2566903808 100;
BA_ "GenMsgSendType" BO_ 2566903808 0;
BA_ "GenMsgCycleTime" BO_ 2566903552 100;
BA_ "GenMsgSendType" BO_ 2566903552 0;
BA_ "GenMsgCycleTime" BO_ 2566903296 100;
BA_ "GenMsgSendType" BO_ 2566903296 0;
BA_ "GenMsgCycleTime" BO_ 2566902784 100;
BA_ "GenMsgSendType" BO_ 2566902784 0;
BA_ "GenMsgCycleTime" BO_ 2566902528 100;
BA_ "GenMsgSendType" BO_ 2566902528 0;
BA_ "GenMsgCycleTime" BO_ 2566901504 100;
BA_ "GenMsgSendType" BO_ 2566901504 0;
BA_ "GenMsgCycleTime" BO_ 2566901248 100;
BA_ "GenMsgSendType" BO_ 2566901248 0;
BA_ "GenMsgCycleTime" BO_ 2566885888 100;
BA_ "GenMsgSendType" BO_ 2566885888 0;
BA_ "GenMsgCycleTime" BO_ 2566877696 1000;
BA_ "GenMsgSendType" BO_ 2566877696 0;
BA_ "GenMsgCycleTime" BO_ 2566877463 1000;
BA_ "GenMsgSendType" BO_ 2566877463 0;
BA_ "GenMsgCycleTime" BO_ 2566876711 1000;
BA_ "GenMsgSendType" BO_ 2566876711 0;
BA_ "GenMsgCycleTime" BO_ 2633984551 100;
BA_ "GenMsgSendType" BO_ 2633984551 0;
BA_ "GenMsgCycleTime" BO_ 2432656679 100;
BA_ "GenMsgSendType" BO_ 2432656679 0;
BA_ "GenMsgCycleTime" BO_ 2566845479 10000;
BA_ "GenMsgSendType" BO_ 2566845479 0;

BA_ "SigType" SG_ 3221225472 DM_SPN2 1.7E-308;
BA_ "SigType" SG_ 3221225472 DM_SPN3 1.7E-308;
BA_ "SPN" SG_ 3221225472 DM_SPN1 1214;
BA_ "SigType" SG_ 3221225472 DM_SPN1 1.7E-308;
BA_ "SPN" SG_ 3221225472 DM_FailureModeIdentifier 1215;
BA_ "SigType" SG_ 3221225472 DM_FailureModeIdentifier 1.7E-308;
BA_ "SPN" SG_ 3221225472 DM_SPNConversionMethod 1706;
BA_ "SigType" SG_ 3221225472 DM_SPNConversionMethod 1.7E-308;
BA_ "SPN" SG_ 3221225472 DM_OccurenceCount 1216;
BA_ "SigType" SG_ 3221225472 DM_OccurenceCount 1.7E-308;
BA_ "GenSigStartValue" SG_ 2564292857 DM15_SAE_Reserved2 1;
BA_ "GenSigStartValue" SG_ 2564292857 DM15_SAE_Reserved 1;
BA_ "GenSigStartValue" SG_ 2564358393 DM14_SAE_Reserved 1;
BA_ "SPN" SG_ 2566846298 NetBatteryCurrent 114;
BA_ "SigType" SG_ 2566846298 NetBatteryCurrent 1.7E-308;
BA_ "SPN" SG_ 2566846298 AlternatorCurrent 115;
BA_ "SigType" SG_ 2566846298 AlternatorCurrent 1.7E-308;
BA_ "SPN" SG_ 2566846298 ChargingSystemPotential 167;
BA_ "SigType" SG_ 2566846298 ChargingSystemPotential 1.7E-308;
BA_ "SPN" SG_ 2566846298 BatteryPotential 168;
BA_ "SigType" SG_ 2566846298 BatteryPotential 1.7E-308;
BA_ "SPN" SG_ 2566846298 KeyswitchBatteryPotential 158;
BA_ "SigType" SG_ 2566846298 KeyswitchBatteryPotential 1.7E-308;
BA_ "SPN" SG_ 2633984602 pHeatedGripEnable 520366;
BA_ "SPN" SG_ 2633984602 pSideStandStatus 524098;
BA_ "SigType" SG_ 2633984602 pSideStandStatus 1.7E-308;
BA_ "SPN" SG_ 2633984602 pTetherSwitchStatus 520600;
BA_ "SPN" SG_ 2633984602 pLowFuelIndicatorStatus 524087;
BA_ "SPN" SG_ 2633984602 pOperatorNotInOperatingStation 2832;
BA_ "SPN" SG_ 2633984602 pParkBrakeIndicatorStatus 524271;
BA_ "SPN" SG_ 2633984602 pADCRequested 524139;
BA_ "SPN" SG_ 2633984602 pAWDModeRequested 524138;
BA_ "SPN" SG_ 2633984602 pRWDModeRequested 524137;
BA_ "SPN" SG_ 2633984602 pTurfModeRequested 524136;
BA_ "SPN" SG_ 2633984602 pADCStatus 524013;
BA_ "SigType" SG_ 2633984602 pADCStatus 1.7E-308;
BA_ "SPN" SG_ 2633984602 pTreadleNeutralStatus 524017;
BA_ "SigType" SG_ 2633984602 pTreadleNeutralStatus 1.7E-308;
BA_ "SPN" SG_ 2633984602 pTreadleReverseStatus 524018;
BA_ "SigType" SG_ 2633984602 pTreadleReverseStatus 1.7E-308;
BA_ "SPN" SG_ 2633984602 pSecurityLightStatus 524019;
BA_ "SigType" SG_ 2633984602 pSecurityLightStatus 1.7E-308;
BA_ "SPN" SG_ 2633984602 pHighBeamIndicatorStatus 524084;
BA_ "SigType" SG_ 2633984602 pHighBeamIndicatorStatus 1.7E-308;
BA_ "SPN" SG_ 2633984602 pHeatedGripsPercentage 524096;
BA_ "SigType" SG_ 2633984602 pHeatedGripsPercentage 1.7E-308;
BA_ "SPN" SG_ 2633984602 pCruiseControlSetStatus 524097;
BA_ "SigType" SG_ 2633984602 pCruiseControlSetStatus 1.7E-308;
BA_ "SPN" SG_ 2633984602 pSeatBeltIndicatorStatus 524092;
BA_ "SigType" SG_ 2633984602 pSeatBeltIndicatorStatus 1.7E-308;
BA_ "SPN" SG_ 2365530458 pChecksum_520571 520571;
BA_ "SPN" SG_ 2365530458 pMessageCounter_520570 520570;
BA_ "SPN" SG_ 2365530458 pEngineSpeed_520569 520569;
BA_ "SPN" SG_ 2365530458 pEngineTorque_Driver_Demanded 520568;
BA_ "SPN" SG_ 2365530458 pEngineTorque 520567;
BA_ "SPN" SG_ 2365530458 pSource_Address_Ctrling_Device 520566;
BA_ "SPN" SG_ 2566843994 EngineCoolantTemperature 110;
BA_ "SigType" SG_ 2566843994 EngineCoolantTemperature 1.7E-308;
BA_ "SPN" SG_ 2566843994 EngFuelTemperature1 174;
BA_ "SigType" SG_ 2566843994 EngFuelTemperature1 1.7E-308;
BA_ "SPN" SG_ 2566843994 EngineOilTemperature1 175;
BA_ "SigType" SG_ 2566843994 EngineOilTemperature1 1.7E-308;
BA_ "SPN" SG_ 2566843994 EngTurboOilTemperature 176;
BA_ "SigType" SG_ 2566843994 EngTurboOilTemperature 1.7E-308;
BA_ "SPN" SG_ 2566843994 EngineIntercoolerTemperature 52;
BA_ "SigType" SG_ 2566843994 EngineIntercoolerTemperature 1.7E-308;
BA_ "SPN" SG_ 2566843994 EngineIntercoolerThermosatOpen 1134;
BA_ "SigType" SG_ 2566843994 EngineIntercoolerThermosatOpen 1.7E-308;
BA_ "SPN" SG_ 2566841690 EngTotalHoursOfOper 247;
BA_ "SigType" SG_ 2566841690 EngTotalHoursOfOper 1.7E-308;
BA_ "SPN" SG_ 2566841690 TotalEngineRevolutions 249;
BA_ "SigType" SG_ 2566841690 TotalEngineRevolutions 1.7E-308;
BA_ "SPN" SG_ 2566876762 pEngineOilPressureStatus 524076;
BA_ "SigType" SG_ 2566876762 pEngineOilPressureStatus 1.7E-308;
BA_ "SPN" SG_ 2566876762 pHydraulicOilPressureStatus 524075;
BA_ "SigType" SG_ 2566876762 pHydraulicOilPressureStatus 1.7E-308;
BA_ "SPN" SG_ 2566876762 pHydraulicOilTempStatus 524074;
BA_ "SigType" SG_ 2566876762 pHydraulicOilTempStatus 1.7E-308;
BA_ "SPN" SG_ 2566876672 pEngineOilPressureStatus 524076;
BA_ "SigType" SG_ 2566876672 pEngineOilPressureStatus 1.7E-308;
BA_ "SPN" SG_ 2566876672 pHydraulicOilPressureStatus 524075;
BA_ "SigType" SG_ 2566876672 pHydraulicOilPressureStatus 1.7E-308;
BA_ "SPN" SG_ 2566876672 pHydraulicOilTempStatus 524074;
BA_ "SigType" SG_ 2566876672 pHydraulicOilTempStatus 1.7E-308;
BA_ "SPN" SG_ 2365553933 MessageCounter 4206;
BA_ "SigType" SG_ 2365553933 MessageCounter 1.7E-308;
BA_ "SPN" SG_ 2565866755 TransmissionSelectedGear 524;
BA_ "SigType" SG_ 2565866755 TransmissionSelectedGear 1.7E-308;
BA_ "SPN" SG_ 2565866755 TransmissionActualGearRatio 526;
BA_ "SigType" SG_ 2565866755 TransmissionActualGearRatio 1.7E-308;
BA_ "SPN" SG_ 2565866755 TransmissionCurrentGear 523;
BA_ "SigType" SG_ 2565866755 TransmissionCurrentGear 1.7E-308;
BA_ "SPN" SG_ 2565866755 TransmissionRqstedRange 162;
BA_ "SigType" SG_ 2565866755 TransmissionRqstedRange 1.7E-308;
BA_ "SPN" SG_ 2565866755 TransmissionCurrentRange 163;
BA_ "SigType" SG_ 2565866755 TransmissionCurrentRange 1.7E-308;
BA_ "GenSigStartValue" SG_ 2566844675 pCruiseCntrlCounter 7;
BA_ "SPN" SG_ 2566844675 pCruiseCntrlCounter 524080;
BA_ "SPN" SG_ 2566844675 TwoSpeedAxleSwitch 69;
BA_ "SigType" SG_ 2566844675 TwoSpeedAxleSwitch 1.7E-308;
BA_ "SPN" SG_ 2566844675 ParkingBrakeSwitch 70;
BA_ "SigType" SG_ 2566844675 ParkingBrakeSwitch 1.7E-308;
BA_ "SPN" SG_ 2566844675 Wheel_BasedVehicleSpeed 84;
BA_ "SigType" SG_ 2566844675 Wheel_BasedVehicleSpeed 1.7E-308;
BA_ "SPN" SG_ 2566844675 CruiseCtrlActive 595;
BA_ "SigType" SG_ 2566844675 CruiseCtrlActive 1.7E-308;
BA_ "SPN" SG_ 2566844675 CruiseCtrlEnableSwitch 596;
BA_ "SigType" SG_ 2566844675 CruiseCtrlEnableSwitch 1.7E-308;
BA_ "SPN" SG_ 2566844675 BrakeSwitch 597;
BA_ "SigType" SG_ 2566844675 BrakeSwitch 1.7E-308;
BA_ "SPN" SG_ 2566844675 ClutchSwitch 598;
BA_ "SigType" SG_ 2566844675 ClutchSwitch 1.7E-308;
BA_ "SPN" SG_ 2566844675 CruiseCtrlSetSwitch 599;
BA_ "SigType" SG_ 2566844675 CruiseCtrlSetSwitch 1.7E-308;
BA_ "SPN" SG_ 2566844675 CruiseCtrlCoastSwitch 600;
BA_ "SigType" SG_ 2566844675 CruiseCtrlCoastSwitch 1.7E-308;
BA_ "SPN" SG_ 2566844675 CruiseCtrlResumeSwitch 601;
BA_ "SigType" SG_ 2566844675 CruiseCtrlResumeSwitch 1.7E-308;
BA_ "SPN" SG_ 2566844675 CruiseCtrlAccelerateSwitch 602;
BA_ "SigType" SG_ 2566844675 CruiseCtrlAccelerateSwitch 1.7E-308;
BA_ "SPN" SG_ 2566844675 CruiseCtrlSetSpeed 86;
BA_ "SigType" SG_ 2566844675 CruiseCtrlSetSpeed 1.7E-308;
BA_ "SPN" SG_ 2566844675 pOdometerDriveBit 523994;
BA_ "SigType" SG_ 2566844675 pOdometerDriveBit 1.7E-308;
BA_ "SPN" SG_ 2566844675 CruiseCtrlPauseSw 1633;
BA_ "SigType" SG_ 2566844675 CruiseCtrlPauseSw 1.7E-308;
BA_ "SPN" SG_ 2566844675 pCCChecksum 524079;
BA_ "SigType" SG_ 2566844675 pCCChecksum 1.7E-308;
BA_ "SPN" SG_ 2566844675 pCruiseEnableStatus 524108;
BA_ "SigType" SG_ 2566844675 pCruiseEnableStatus 1.7E-308;
BA_ "SPN" SG_ 2231304282 pEPCU_1_Speed_Limit 524251;
BA_ "SPN" SG_ 2231304282 pEPCU_1_Counter_Torque_Limit 524251;
BA_ "SPN" SG_ 2231304282 pEPCU_1_Torque_Demand 524251;
BA_ "SPN" SG_ 2231304282 pEPCU_1_Control_Mode 524251;
BA_ "SPN" SG_ 2231304282 pEPCU_1_Message_Counter 524251;
BA_ "SPN" SG_ 2231304282 pEPCU_1_Checksum 524251;
BA_ "SPN" SG_ 2231309146 pEPCU_1_Speed_Limit 524251;
BA_ "SPN" SG_ 2231309146 pEPCU_1_Counter_Torque_Limit 524251;
BA_ "SPN" SG_ 2231309146 pEPCU_1_Torque_Demand 524251;
BA_ "SPN" SG_ 2231309146 pEPCU_1_Control_Mode 524251;
BA_ "SPN" SG_ 2231309146 pEPCU_1_Message_Counter 524251;
BA_ "SPN" SG_ 2231309146 pEPCU_1_Checksum 524251;
BA_ "SPN" SG_ 2365525594 WATT_pPack_Voltage 524217;
BA_ "SPN" SG_ 2365525594 WATT_pPack_Current 524216;
BA_ "SPN" SG_ 2365525594 WATT_pDischarge_Limit 524218;
BA_ "SPN" SG_ 2365525594 WATT_pCharge_Limit 524219;
BA_ "SPN" SG_ 2365525594 WATT_pBMC_Pwr_Msg_Check_Seq 524252;
BA_ "SPN" SG_ 2566878554 pChecksum_524123 524123;
BA_ "SPN" SG_ 2566878554 pMessageCounter_524122 524122;
BA_ "SPN" SG_ 2566878554 pOperationMode 524120;
BA_ "SPN" SG_ 2566878554 pStartStopCmd 520497;
BA_ "SPN" SG_ 2566878554 pNorm_Acc_Pos_520354 520354;
BA_ "SPN" SG_ 2566844762 TwoSpeedAxleSwitch 69;
BA_ "SigType" SG_ 2566844762 TwoSpeedAxleSwitch 1.7E-308;
BA_ "SPN" SG_ 2566844762 ParkingBrakeSwitch 70;
BA_ "SigType" SG_ 2566844762 ParkingBrakeSwitch 1.7E-308;
BA_ "SPN" SG_ 2566844762 Wheel_BasedVehicleSpeed 84;
BA_ "SigType" SG_ 2566844762 Wheel_BasedVehicleSpeed 1.7E-308;
BA_ "SPN" SG_ 2566844762 CruiseCtrlActive 595;
BA_ "SigType" SG_ 2566844762 CruiseCtrlActive 1.7E-308;
BA_ "SPN" SG_ 2566844762 CruiseCtrlEnableSwitch 596;
BA_ "SigType" SG_ 2566844762 CruiseCtrlEnableSwitch 1.7E-308;
BA_ "SPN" SG_ 2566844762 BrakeSwitch 597;
BA_ "SigType" SG_ 2566844762 BrakeSwitch 1.7E-308;
BA_ "SPN" SG_ 2566844762 ClutchSwitch 598;
BA_ "SigType" SG_ 2566844762 ClutchSwitch 1.7E-308;
BA_ "SPN" SG_ 2566844762 CruiseCtrlSetSwitch 599;
BA_ "SigType" SG_ 2566844762 CruiseCtrlSetSwitch 1.7E-308;
BA_ "SPN" SG_ 2566844762 CruiseCtrlCoastSwitch 600;
BA_ "SigType" SG_ 2566844762 CruiseCtrlCoastSwitch 1.7E-308;
BA_ "SPN" SG_ 2566844762 CruiseCtrlResumeSwitch 601;
BA_ "SigType" SG_ 2566844762 CruiseCtrlResumeSwitch 1.7E-308;
BA_ "SPN" SG_ 2566844762 CruiseCtrlAccelerateSwitch 602;
BA_ "SigType" SG_ 2566844762 CruiseCtrlAccelerateSwitch 1.7E-308;
BA_ "SPN" SG_ 2566844762 CruiseCtrlSetSpeed 86;
BA_ "SigType" SG_ 2566844762 CruiseCtrlSetSpeed 1.7E-308;
BA_ "SPN" SG_ 2566844762 pOdometerDriveBit 523994;
BA_ "SigType" SG_ 2566844762 pOdometerDriveBit 1.7E-308;
BA_ "SPN" SG_ 2566844762 CruiseCtrlPauseSw 1633;
BA_ "SigType" SG_ 2566844762 CruiseCtrlPauseSw 1.7E-308;
BA_ "SPN" SG_ 2566844762 pCCMessageCounter 524080;
BA_ "SigType" SG_ 2566844762 pCCMessageCounter 1.7E-308;
BA_ "SPN" SG_ 2566844762 pCCChecksum 524079;
BA_ "SigType" SG_ 2566844762 pCCChecksum 1.7E-308;
BA_ "SPN" SG_ 2566844762 pCruiseEnableStatus 524108;
BA_ "SigType" SG_ 2566844762 pCruiseEnableStatus 1.7E-308;
BA_ "SPN" SG_ 2566887489 pRiderWeightRearLeft 516103;
BA_ "SigType" SG_ 2566887489 pRiderWeightRearLeft 1.7E-308;
BA_ "SPN" SG_ 2566887489 pBoxLoadWeight 516105;
BA_ "SigType" SG_ 2566887489 pBoxLoadWeight 1.7E-308;
BA_ "SPN" SG_ 2566887489 pRiderWeightRearRight 516104;
BA_ "SigType" SG_ 2566887489 pRiderWeightRearRight 1.7E-308;
BA_ "SPN" SG_ 2566887489 pRiderWeightMidRight 516102;
BA_ "SigType" SG_ 2566887489 pRiderWeightMidRight 1.7E-308;
BA_ "SPN" SG_ 2566887489 pRiderWeightMidLeft 516101;
BA_ "SigType" SG_ 2566887489 pRiderWeightMidLeft 1.7E-308;
BA_ "SPN" SG_ 2566887489 pRiderWeightFrontRight 516100;
BA_ "SigType" SG_ 2566887489 pRiderWeightFrontRight 1.7E-308;
BA_ "SPN" SG_ 2566887489 pRiderWeightFrontLeft 516099;
BA_ "SigType" SG_ 2566887489 pRiderWeightFrontLeft 1.7E-308;
BA_ "SPN" SG_ 2566853722 pRangeToEmptyEV 520529;
BA_ "SPN" SG_ 2566853722 pEfficiencyEV 520528;
BA_ "SPN" SG_ 2365554060 MessageCounter 4206;
BA_ "SigType" SG_ 2365554060 MessageCounter 1.7E-308;
BA_ "SPN" SG_ 2365526260 WATT_pBattTempMin 524282;
BA_ "SPN" SG_ 2365526260 WATT_pTractionBat_Msg_Check_Seq 524254;
BA_ "SPN" SG_ 2365526260 WATT_pSOH 524223;
BA_ "SPN" SG_ 2365526260 WATT_pK_Battemp 524225;
BA_ "SPN" SG_ 2365526260 WATT_pFloat_State 524226;
BA_ "SPN" SG_ 2365526260 WATT_pBattery_Temp 524224;
BA_ "SPN" SG_ 2365526259 WATT_pBattTempMin 524282;
BA_ "SPN" SG_ 2365526259 WATT_pTractionBat_Msg_Check_Seq 524254;
BA_ "SPN" SG_ 2365526259 WATT_pSOH 524223;
BA_ "SPN" SG_ 2365526259 WATT_pK_Battemp 524225;
BA_ "SPN" SG_ 2365526259 WATT_pFloat_State 524226;
BA_ "SPN" SG_ 2365526259 WATT_pBattery_Temp 524224;
BA_ "SPN" SG_ 2365526516 WATT_pBMCStatusCntr 524273;
BA_ "SPN" SG_ 2365526516 WATT_pBatteryType 520404;
BA_ "SPN" SG_ 2365526516 WATT_pWAKE_State 524230;
BA_ "SPN" SG_ 2365526516 WATT_pKEY_State 524232;
BA_ "SPN" SG_ 2365526516 WATT_pDC_DC_State 524233;
BA_ "SPN" SG_ 2365526516 WATT_pBMC_Temp 524227;
BA_ "SPN" SG_ 2365526516 WATT_pBMC_Status_Msg_Check_Seq 524255;
BA_ "SPN" SG_ 2365526516 WATT_pBalance_State 524229;
BA_ "SPN" SG_ 2365526516 WATT_pBalance_Error 524228;
BA_ "SPN" SG_ 2365526772 pCharger_Status_Counter 524251;
BA_ "SPN" SG_ 2365526772 WATT_pCharger_Voltage 524235;
BA_ "SPN" SG_ 2365526772 WATT_pCharger_Temp 524236;
BA_ "SPN" SG_ 2365526772 WATT_pCharger_State 524239;
BA_ "SPN" SG_ 2365526772 WATT_pCharger_Stat_Msg_Check_Seq 524256;
BA_ "SPN" SG_ 2365526772 WATT_pCharger_Current 524234;
BA_ "SPN" SG_ 2365526772 WATT_pAC_Status 524238;
BA_ "SPN" SG_ 2365526004 WATT_pWh_In_Since_Key 524222;
BA_ "SPN" SG_ 2365526004 WATT_pSOC 524220;
BA_ "SPN" SG_ 2365526004 WATT_pEnergy_Msg_Check_Seq 524253;
BA_ "SPN" SG_ 2365526004 WATT_pAvailable_Wh 524221;
BA_ "SPN" SG_ 2365526515 WATT_pBMCStatusCntr 524273;
BA_ "SPN" SG_ 2365526515 WATT_pBatteryType 520404;
BA_ "SPN" SG_ 2365526515 WATT_pWAKE_State 524230;
BA_ "SPN" SG_ 2365526515 WATT_pKEY_State 524232;
BA_ "SPN" SG_ 2365526515 WATT_pDC_DC_State 524233;
BA_ "SPN" SG_ 2365526515 WATT_pBMC_Temp 524227;
BA_ "SPN" SG_ 2365526515 WATT_pBMC_Status_Msg_Check_Seq 524255;
BA_ "SPN" SG_ 2365526515 WATT_pBalance_State 524229;
BA_ "SPN" SG_ 2365526515 WATT_pBalance_Error 524228;
BA_ "SPN" SG_ 2365526771 pCharger_Status_Counter 524251;
BA_ "SPN" SG_ 2365526771 WATT_pCharger_Voltage 524235;
BA_ "SPN" SG_ 2365526771 WATT_pCharger_Temp 524236;
BA_ "SPN" SG_ 2365526771 WATT_pCharger_State 524239;
BA_ "SPN" SG_ 2365526771 WATT_pCharger_Stat_Msg_Check_Seq 524256;
BA_ "SPN" SG_ 2365526771 WATT_pCharger_Current 524234;
BA_ "SPN" SG_ 2365526771 WATT_pAC_Status 524238;
BA_ "SPN" SG_ 2365526003 WATT_pWh_In_Since_Key 524222;
BA_ "SPN" SG_ 2365526003 WATT_pSOC 524220;
BA_ "SPN" SG_ 2365526003 WATT_pEnergy_Msg_Check_Seq 524253;
BA_ "SPN" SG_ 2365526003 WATT_pAvailable_Wh 524221;
BA_ "SPN" SG_ 2298415094 WATT_pUpper_Available_Torque 524192;
BA_ "SPN" SG_ 2298415094 WATT_pPerformance_State 524190;
BA_ "SPN" SG_ 2298415094 WATT_pPerformance_Msg_Check_Seq 524249;
BA_ "SPN" SG_ 2298415094 WATT_pLower_Available_Torque 524193;
BA_ "SPN" SG_ 2298415094 WATT_pActual_Motor_Velocity 524194;
BA_ "SPN" SG_ 2298415094 WATT_pActual_Motor_torque 524191;
BA_ "SPN" SG_ 2298415095 WATT_pUpper_Available_Torque 524192;
BA_ "SPN" SG_ 2298415095 WATT_pPerformance_State 524190;
BA_ "SPN" SG_ 2298415095 WATT_pPerformance_Msg_Check_Seq 524249;
BA_ "SPN" SG_ 2298415095 WATT_pLower_Available_Torque 524193;
BA_ "SPN" SG_ 2298415095 WATT_pActual_Motor_Velocity 524194;
BA_ "SPN" SG_ 2298415090 WATT_pUpper_Available_Torque 524192;
BA_ "SPN" SG_ 2298415090 WATT_pPerformance_State 524190;
BA_ "SPN" SG_ 2298415090 WATT_pPerformance_Msg_Check_Seq 524249;
BA_ "SPN" SG_ 2298415090 WATT_pLower_Available_Torque 524193;
BA_ "SPN" SG_ 2298415090 WATT_pActual_Motor_Velocity 524194;
BA_ "SPN" SG_ 2298415090 WATT_pActual_Motor_torque 524191;
BA_ "SPN" SG_ 2298415089 WATT_pUpper_Available_Torque 524192;
BA_ "SPN" SG_ 2298415089 WATT_pPerformance_State 524190;
BA_ "SPN" SG_ 2298415089 WATT_pPerformance_Msg_Check_Seq 524249;
BA_ "SPN" SG_ 2298415089 WATT_pActual_Motor_Velocity 524194;
BA_ "SPN" SG_ 2298415089 WATT_pActual_Motor_torque 524191;
BA_ "SPN" SG_ 2298415088 WATT_pUpper_Available_Torque 524192;
BA_ "SPN" SG_ 2298415088 WATT_pPerformance_State 524190;
BA_ "SPN" SG_ 2298415088 WATT_pPerformance_Msg_Check_Seq 524249;
BA_ "SPN" SG_ 2298415088 WATT_pLower_Available_Torque 524193;
BA_ "SPN" SG_ 2298415088 WATT_pActual_Motor_Velocity 524194;
BA_ "SPN" SG_ 2298415088 WATT_pActual_Motor_torque 524191;
BA_ "SPN" SG_ 2298415087 WATT_pUpper_Available_Torque 524192;
BA_ "SPN" SG_ 2298415087 WATT_pPerformance_State 524190;
BA_ "SPN" SG_ 2298415087 WATT_pPerformance_Msg_Check_Seq 524249;
BA_ "SPN" SG_ 2298415087 WATT_pLower_Available_Torque 524193;
BA_ "SPN" SG_ 2298415087 WATT_pActual_Motor_Velocity 524194;
BA_ "SPN" SG_ 2298415087 WATT_pActual_Motor_torque 524191;
BA_ "SPN" SG_ 2566834735 DM_FlashRedStopLamp 3039;
BA_ "SPN" SG_ 2566834735 DM_FlashProtectLamp 3041;
BA_ "SPN" SG_ 2566834735 DM_FlashMalfuncIndicatorLamp 3038;
BA_ "SPN" SG_ 2566834735 DM_FlashAmberWarningLamp 3040;
BA_ "SigType" SG_ 2566834735 DTC5 7;
BA_ "SigType" SG_ 2566834735 DTC4 7;
BA_ "SigType" SG_ 2566834735 DTC3 7;
BA_ "SigType" SG_ 2566834735 DTC2 7;
BA_ "SigType" SG_ 2566834735 DTC1 7;
BA_ "SPN" SG_ 2566834735 DM_ProtectLampStatus 987;
BA_ "SigType" SG_ 2566834735 DM_ProtectLampStatus 1.7E-308;
BA_ "SPN" SG_ 2566834735 DM_RedStopLampState 623;
BA_ "SigType" SG_ 2566834735 DM_RedStopLampState 1.7E-308;
BA_ "SPN" SG_ 2566834735 DM_AmberWrningLmpStatus 624;
BA_ "SigType" SG_ 2566834735 DM_AmberWrningLmpStatus 1.7E-308;
BA_ "SPN" SG_ 2566834735 DM_MalfuncnIndicatorLampStatus 1213;
BA_ "SigType" SG_ 2566834735 DM_MalfuncnIndicatorLampStatus 1.7E-308;
BA_ "SigType" SG_ 2566903040 DL_CrankReqInput 1.7E-308;
BA_ "SigType" SG_ 2566903040 DL_LowOilLevelInput 1.7E-308;
BA_ "SigType" SG_ 2566903040 DL_LoadAnticipate1Input 1.7E-308;
BA_ "SigType" SG_ 2566903040 DL_LoadAnticipate2Input 1.7E-308;
BA_ "SigType" SG_ 2566903040 DL_CruiseDecelInputActive 1.7E-308;
BA_ "SigType" SG_ 2566903040 DL_CruiseAccelInputActive 1.7E-308;
BA_ "SigType" SG_ 2566903040 DL_PowertrainRelayOutput 1.7E-308;
BA_ "SigType" SG_ 2566903040 DL_StarterRelayOutput 1.7E-308;
BA_ "SigType" SG_ 2566903040 DL_FuelPump1RelayOutput 1.7E-308;
BA_ "SigType" SG_ 2566903040 DL_SlowmodeInputActive 1.7E-308;
BA_ "SigType" SG_ 2566903040 DL_SlowModeLampOutput 1.7E-308;
BA_ "SigType" SG_ 2566903040 DL_GovCruiseSync 1.7E-308;
BA_ "SigType" SG_ 2566903040 DL_DiscreteLowOilPressInput 1.7E-308;
BA_ "SigType" SG_ 2566903040 DL_MILOutput 1.7E-308;
BA_ "SPN" SG_ 2566855680 pRqstdPerFan1DutyCycle 520361;
BA_ "SPN" SG_ 2566855680 pFan1DirectionCmd 520360;
BA_ "SPN" SG_ 2566886912 pFleetMgmtDefVehState 520638;
BA_ "SPN" SG_ 2566886912 pVehEnblDisbl 520637;
BA_ "SPN" SG_ 2566886912 pUserAuthenticationStatus 520636;
BA_ "SPN" SG_ 2566886912 pBoundaryStatus 520635;
BA_ "SPN" SG_ 2566886400 EngineCyldr2IngnitionTmg 520535;
BA_ "SPN" SG_ 2566886400 EngineCyldr1IgnitionTmg 520534;
BA_ "SPN" SG_ 2566886400 DesiredLambda 520533;
BA_ "SPN" SG_ 2566886400 HighRngEngPerLoad 520532;
BA_ "SPN" SG_ 2566878227 pEPSShaftVelocity 524115;
BA_ "SPN" SG_ 2566878227 pEPSShaftPosition 524114;
BA_ "SPN" SG_ 2566878227 pEPSSASCalibrated 524118;
BA_ "SPN" SG_ 2566878227 pEPSOperationStatus 524117;
BA_ "SPN" SG_ 2566878227 pEPSOperationMode 524116;
BA_ "SPN" SG_ 2365553931 MessageCounter 4206;
BA_ "SigType" SG_ 2365553931 MessageCounter 1.7E-308;
BA_ "SigType" SG_ 2566907687 DL20_KeyFobBatteryVoltage 1.7E-308;
BA_ "SigType" SG_ 2566907687 DL20_LeanAngle 1.7E-308;
BA_ "SigType" SG_ 2566907943 DL19_TirePressure_Rear_Left_Only 1.7E-308;
BA_ "SigType" SG_ 2566907943 DL19_TirePressureFront_Left_Only 1.7E-308;
BA_ "SigType" SG_ 2566907943 DL19_TirePressureFrontRight 1.7E-308;
BA_ "SigType" SG_ 2566907943 DL19_TirePressureRearRight 1.7E-308;
BA_ "SigType" SG_ 2566910247 FI5_b10Sec 1.7E-308;
BA_ "SigType" SG_ 2566910247 FI5_bBatt 1.7E-308;
BA_ "SigType" SG_ 2566910247 FI5_bEnable 1.7E-308;
BA_ "SigType" SG_ 2566910247 FI5_bLazyCRC 1.7E-308;
BA_ "SigType" SG_ 2566910247 FI5_bManCyc 1.7E-308;
BA_ "SigType" SG_ 2566910247 FI5_bNotRun 1.7E-308;
BA_ "SigType" SG_ 2566910247 FI5_bOper 1.7E-308;
BA_ "SigType" SG_ 2566910503 FI4_BrakeLightOutput 1.7E-308;
BA_ "SigType" SG_ 2566910503 FI4_FogLightInput 1.7E-308;
BA_ "SigType" SG_ 2566910503 FI4_HazardLightOutput 1.7E-308;
BA_ "SigType" SG_ 2566910503 FI4_HazardSWInput 1.7E-308;
BA_ "SigType" SG_ 2566910503 FI4_HeatGripDecSW 1.7E-308;
BA_ "SigType" SG_ 2566910503 FI4_HeatGripIncSW 1.7E-308;
BA_ "SigType" SG_ 2566910503 FI4_HighBeamOutput 1.7E-308;
BA_ "SigType" SG_ 2566910503 FI4_HornInput 1.7E-308;
BA_ "SigType" SG_ 2566910503 FI4_HornOutput 1.7E-308;
BA_ "SigType" SG_ 2566910503 FI4_LeftFogLightOutput 1.7E-308;
BA_ "SigType" SG_ 2566910503 FI4_LFTurnSignalOutput 1.7E-308;
BA_ "SigType" SG_ 2566910503 FI4_LockInput 1.7E-308;
BA_ "SigType" SG_ 2566910503 FI4_LowBeamOutput 1.7E-308;
BA_ "SigType" SG_ 2566910503 FI4_LowHighBeamInput 1.7E-308;
BA_ "SigType" SG_ 2566910503 FI4_LRTurnSignalOutput 1.7E-308;
BA_ "SigType" SG_ 2566910503 FI4_pOperatorButton1 1.7E-308;
BA_ "SigType" SG_ 2566910503 FI4_RFTurnSignalOutput 1.7E-308;
BA_ "SigType" SG_ 2566910503 FI4_RightFogLightOutput 1.7E-308;
BA_ "SigType" SG_ 2566910503 FI4_RRTurnSignalOutput 1.7E-308;
BA_ "SigType" SG_ 2566910503 FI4_SecondaryAirValveCmd 1.7E-308;
BA_ "SigType" SG_ 2566910503 FI4_SecondaryAirValveOut 1.7E-308;
BA_ "SigType" SG_ 2566910503 FI4_TailLightOutput 1.7E-308;
BA_ "SigType" SG_ 2566910503 FI4_UnlockInput 1.7E-308;
BA_ "SigType" SG_ 2566910503 FI4_WindshieldSWDownInput 1.7E-308;
BA_ "SigType" SG_ 2566910503 FI4_WindshieldSWUpInput 1.7E-308;
BA_ "SigType" SG_ 2566910503 FI4_pOperatorButton2 1.7E-308;
BA_ "SigType" SG_ 2566910759 FI3_DriveMode1Input 1.7E-308;
BA_ "SigType" SG_ 2566910759 FI3_DriveMode2Input 1.7E-308;
BA_ "SigType" SG_ 2566910759 FI3_DriveMode3Input 1.7E-308;
BA_ "SigType" SG_ 2566910759 FI3_DriverMode4Input 1.7E-308;
BA_ "SigType" SG_ 2566910759 FI3_DriverMode1Output 1.7E-308;
BA_ "SigType" SG_ 2566910759 FI3_DriverMode2Output 1.7E-308;
BA_ "SigType" SG_ 2566910759 FI3_DriverMode3Output 1.7E-308;
BA_ "SigType" SG_ 2566910759 FI3_DriverMode4Ouput 1.7E-308;
BA_ "SigType" SG_ 2566910759 FI3_PTOModeInput 1.7E-308;
BA_ "SigType" SG_ 2566910759 FI3_PTOModeOutput 1.7E-308;
BA_ "SigType" SG_ 2566910759 FI3_DriversNetEngagement 1.7E-308;
BA_ "SigType" SG_ 2566910759 FI3_DriversSeatbeltEngagement 1.7E-308;
BA_ "SigType" SG_ 2566910759 FI3_TiltLockInput 1.7E-308;
BA_ "SigType" SG_ 2566910759 FI3_WorkGroupLockInput 1.7E-308;
BA_ "SigType" SG_ 2566910759 FI3_OperatorPresenceInput 1.7E-308;
BA_ "SigType" SG_ 2566910759 FI3_WorkGroupLockOutput 1.7E-308;
BA_ "SigType" SG_ 2566910759 FI3_OperatorPresenceOutput 1.7E-308;
BA_ "SigType" SG_ 2566910759 FI3_FootOnCruiseInput 1.7E-308;
BA_ "SigType" SG_ 2566910759 FI3_CruiseInput 1.7E-308;
BA_ "SigType" SG_ 2566910759 FI3_TredalInput 1.7E-308;
BA_ "SigType" SG_ 2566910759 FI3_CruiseSpeedInput 1.7E-308;
BA_ "SigType" SG_ 2566910759 FI3_FootOnCruiseOutput 1.7E-308;
BA_ "SigType" SG_ 2566910759 FI3_CruiseOutput 1.7E-308;
BA_ "SigType" SG_ 2566910759 FI3_CruiseControltoSetSpeed 1.7E-308;
BA_ "SigType" SG_ 2566910759 FI3_WorkModeInput 1.7E-308;
BA_ "SigType" SG_ 2566910759 FI3_TiltLockOutput 1.7E-308;
BA_ "SigType" SG_ 2566911015 FI2_ADCOutput 1.7E-308;
BA_ "SigType" SG_ 2566911015 FI2_RearDiffLockOutput 1.7E-308;
BA_ "SigType" SG_ 2566911015 FI2_AWDOutput 1.7E-308;
BA_ "SigType" SG_ 2566911015 FI2_BrakeSwitchInput 1.7E-308;
BA_ "SigType" SG_ 2566911015 FI2_ADCSwitchInput 1.7E-308;
BA_ "SigType" SG_ 2566911015 FI2_TurfModeInput 1.7E-308;
BA_ "SigType" SG_ 2566911015 FI2_AWDSwitchInput 1.7E-308;
BA_ "SigType" SG_ 2566911015 FI2_ReverseSwitchInput 1.7E-308;
BA_ "SigType" SG_ 2566911015 FI2_ReverseLimitSwitchInput 1.7E-308;
BA_ "SigType" SG_ 2566911015 FI2_ForwardLimitSwitchInput 1.7E-308;
BA_ "SigType" SG_ 2566911015 FI2_EngineDirection 1.7E-308;
BA_ "SigType" SG_ 2566911015 FI2_RevSpeedLimitOverrideInput 1.7E-308;
BA_ "SigType" SG_ 2566911015 FI2_ReverseOverspeedSignal 1.7E-308;
BA_ "SigType" SG_ 2566911015 FI2_RightTurnSignalInput 1.7E-308;
BA_ "SigType" SG_ 2566911015 FI2_LeftTurnSignalInput 1.7E-308;
BA_ "SigType" SG_ 2566911015 FI2_KickstandSwitchInput 1.7E-308;
BA_ "SigType" SG_ 2566911015 FI2_ReflashEnableInputSignal 1.7E-308;
BA_ "SigType" SG_ 2566911015 FI2_TPSLearnInputSignal 1.7E-308;
BA_ "SigType" SG_ 2566911015 FI2_LowRangeSwitchInput 1.7E-308;
BA_ "SigType" SG_ 2566911015 FI2_ReverseMotorDriveInput 1.7E-308;
BA_ "SigType" SG_ 2566911271 FI1_FuelPumpDriverCkt 1.7E-308;
BA_ "SigType" SG_ 2566911271 FI1_RolloverSwitch 1.7E-308;
BA_ "SigType" SG_ 2566911271 FI1_CrankSensorSignal 1.7E-308;
BA_ "SigType" SG_ 2566911271 FI1_CamSensorSignal 1.7E-308;
BA_ "SigType" SG_ 2566911271 FI1_RPMLimitActive 1.7E-308;
BA_ "SigType" SG_ 2566911271 FI1_IdleSwitch 1.7E-308;
BA_ "SigType" SG_ 2566911271 FI1_CycleSynchro 1.7E-308;
BA_ "SigType" SG_ 2566911271 FI1_IdleSpeedControlStatus 1.7E-308;
BA_ "SigType" SG_ 2566911271 FI1_IgnitionSwitchInput 1.7E-308;
BA_ "SigType" SG_ 2566911271 FI1_RunStopSwitchInput 1.7E-308;
BA_ "SigType" SG_ 2566911271 FI1_StartSwitchInput 1.7E-308;
BA_ "SigType" SG_ 2566911271 FI1_ThrottleSafetySwInput 1.7E-308;
BA_ "SigType" SG_ 2566911271 FI1_FanRelayOutput 1.7E-308;
BA_ "SigType" SG_ 2566911271 FI1_IntercoolerFanOutput 1.7E-308;
BA_ "SigType" SG_ 2566911271 FI1_ReverseAlarmOutput 1.7E-308;
BA_ "SigType" SG_ 2566911271 FI1_MainRelayOutput 1.7E-308;
BA_ "SigType" SG_ 2566911271 FI1_StartSolenoidOutput 1.7E-308;
BA_ "SigType" SG_ 2566911271 FI1_IgnitionRelayOutput 1.7E-308;
BA_ "SigType" SG_ 2566911271 FI1_ChassisRelayOutput 1.7E-308;
BA_ "SigType" SG_ 2566911271 FI1_StarterEnableOutput 1.7E-308;
BA_ "SigType" SG_ 2566911271 FI1_ExhaustValveOutput 1.7E-308;
BA_ "SigType" SG_ 2566911271 FI1_BatteryChargeRelayOutput 1.7E-308;
BA_ "SigType" SG_ 2566911271 FI1_HeaterAccRelay 1.7E-308;
BA_ "SigType" SG_ 2566911271 FI1_ClutchSwitchInput 1.7E-308;
BA_ "SigType" SG_ 2566911271 FI1_MILLampOutput 1.7E-308;
BA_ "SigType" SG_ 2566911271 FI1_OverTempLampOutput 1.7E-308;
BA_ "SigType" SG_ 2566911271 FI1_KnockDetLampOutput 1.7E-308;
BA_ "SigType" SG_ 2566911271 FI1_ElecOilPumpDrvrCirc 1.7E-308;
BA_ "SigType" SG_ 2566913547 DL2_EngineThrottlePosition 1.7E-308;
BA_ "SigType" SG_ 2566913547 DL2_EngineCoolantTemperature 1.7E-308;
BA_ "SigType" SG_ 2566913547 DL2_EngineAirInletTemperature 1.7E-308;
BA_ "SigType" SG_ 2566913547 DL2_EngIntakeManifoldPressure 1.7E-308;
BA_ "SigType" SG_ 2566913547 DL2_Boost 1.7E-308;
BA_ "SigType" SG_ 2566913547 DL2_BarometricPressure 1.7E-308;
BA_ "SigType" SG_ 2566913547 DL2_Wheel_BasedVehicleSpeed 1.7E-308;
BA_ "SigType" SG_ 2566913547 DL2_BarometricPressure_Volts 1.7E-308;
BA_ "SigType" SG_ 2566912551 DL6_GearVolts 1.7E-308;
BA_ "SigType" SG_ 2566912551 DL6_RolloverVolts 1.7E-308;
BA_ "SigType" SG_ 2566912551 DL6_ThrottleReleaseInputVolts 1.7E-308;
BA_ "SigType" SG_ 2566912551 DL6_FuelTypeSensorVolts 1.7E-308;
BA_ "SigType" SG_ 2566908427 DL17_Wheel_Spd_Front_LSB 1.7E-308;
BA_ "SigType" SG_ 2566908427 DL17_Wheel_Spd_Front_MSB 1.7E-308;
BA_ "SigType" SG_ 2566908427 DL17_Wheel_Spd_Rear_LSB 1.7E-308;
BA_ "SigType" SG_ 2566908427 DL17_Wheel_Spd_Rear_MSB 1.7E-308;
BA_ "SigType" SG_ 2566908427 DL17_ABS_Source_Voltage 1.7E-308;
BA_ "SigType" SG_ 2566908427 DL17_ABS_Pump_Command 1.7E-308;
BA_ "SigType" SG_ 2566908427 DL17_Brake_Sw_Status 1.7E-308;
BA_ "SigType" SG_ 2566908427 DL17_ABS_Failsafe_Relay 1.7E-308;
BA_ "SigType" SG_ 2566908427 DL17_ABS_Evac_Fill 1.7E-308;
BA_ "SigType" SG_ 2566908427 DL17_RedBrakeLamp 1.7E-308;
BA_ "SigType" SG_ 2566908427 DL17_ABSFaultLamp 1.7E-308;
BA_ "SigType" SG_ 2566908427 DL17_TCSDisabledLamp 1.7E-308;
BA_ "SigType" SG_ 2566908427 DL17_ESCDisabledLamp 1.7E-308;
BA_ "SigType" SG_ 2566908427 DL17_ESCFaultLampFlashing 1.7E-308;
BA_ "SigType" SG_ 2566908427 DL17_ESCFaultLampSolid 1.7E-308;
BA_ "SigType" SG_ 2566908427 DL17_TorqueRequestedtoECM 1.7E-308;
BA_ "SigType" SG_ 2566908427 DL17_TractionCtrlOverrideSwitch 1.7E-308;
BA_ "SigType" SG_ 2566907392 DL_O2SensorA1 1.7E-308;
BA_ "SigType" SG_ 2566907392 DL_O2SensorA1Condition 1.7E-308;
BA_ "SigType" SG_ 2566907392 DL_O2SensorA1Status 1.7E-308;
BA_ "SigType" SG_ 2566907392 DL_ClosedLoopFuelControl 1.7E-308;
BA_ "SigType" SG_ 2566907392 DL_O2SensorA1Volt 1.7E-308;
BA_ "SigType" SG_ 2566907392 DL_O2SensA1RichLeanCrossCnt 1.7E-308;
BA_ "SigType" SG_ 2566907392 DL_BankA_BLMCell 1.7E-308;
BA_ "SigType" SG_ 2566907392 DL_BankA_BLMCellValue 1.7E-308;
BA_ "SigType" SG_ 2566907392 DL_BankAFuelMult 1.7E-308;
BA_ "SigType" SG_ 2566907392 DL_O2SensorA1HeaterCurrent 1.7E-308;
BA_ "SigType" SG_ 2566906880 DL_PedalPositionSensor1Volt 1.7E-308;
BA_ "SigType" SG_ 2566906880 DL_PedalPositionSensor2Volt 1.7E-308;
BA_ "SigType" SG_ 2566906880 DL_PedalPosition 1.7E-308;
BA_ "SigType" SG_ 2566906624 DL_MATSensor 1.7E-308;
BA_ "SigType" SG_ 2566906624 DL_CoolantTempSensorResis 1.7E-308;
BA_ "SigType" SG_ 2566906624 DL_CoolantTemp 1.7E-308;
BA_ "SigType" SG_ 2566906624 DL_MATSensorResist 1.7E-308;
BA_ "SigType" SG_ 2566906624 DL_ManifoldAirTemp 1.7E-308;
BA_ "SigType" SG_ 2566906368 DL_ETCPresent 1.7E-308;
BA_ "SigType" SG_ 2566906368 DL_ETCHbridgeCurrentDirection 1.7E-308;
BA_ "SigType" SG_ 2566906368 DL_MinPositionLearningPending 1.7E-308;
BA_ "SigType" SG_ 2566906368 DL_TPSSensor1RawVolt 1.7E-308;
BA_ "SigType" SG_ 2566906368 DL_TPSSensor2RawVolt 1.7E-308;
BA_ "SigType" SG_ 2566906368 DL_ThrottlePosition 1.7E-308;
BA_ "SigType" SG_ 2566906368 DL_DesiredThrottlePosition 1.7E-308;
BA_ "SigType" SG_ 2566906368 DL_ETCMotorPWM 1.7E-308;
BA_ "SigType" SG_ 2566906368 DL_GovPresent 1.7E-308;
BA_ "SigType" SG_ 2566906112 DL_MAPSensorRawVoltage 1.7E-308;
BA_ "SigType" SG_ 2566906112 DL_ManifoldAirPress 1.7E-308;
BA_ "SPN" SG_ 2566906112 DL_BarometricPressure 108;
BA_ "SigType" SG_ 2566906112 DL_BarometricPressure 1.7E-308;
BA_ "SigType" SG_ 2566906112 DL_BaroSensorPresent 1.7E-308;
BA_ "SigType" SG_ 2566905344 DL_OilLifeMonitorEnabled 1.7E-308;
BA_ "SigType" SG_ 2566905344 DL_ChangeOilNow 1.7E-308;
BA_ "SigType" SG_ 2566905344 DL_ChangeOilSoon 1.7E-308;
BA_ "SigType" SG_ 2566905344 DL_OilLifeRemaining 1.7E-308;
BA_ "SigType" SG_ 2566905344 DL_OilLifeRemainingAtLastChange 1.7E-308;
BA_ "SigType" SG_ 2566905344 DL_OilLifeRemainAtChngPriorToLst 1.7E-308;
BA_ "SigType" SG_ 2566905344 DL_EngRunTimeSinceLastOilChg 1.7E-308;
BA_ "SigType" SG_ 2566904064 DL_NoRevLimInLastSec 1.7E-308;
BA_ "SigType" SG_ 2566904064 DL_RevLimitThreshold 1.7E-308;
BA_ "SigType" SG_ 2566904064 DL_GovernorPresent 1.7E-308;
BA_ "SigType" SG_ 2566904064 DL_SlowMode 1.7E-308;
BA_ "SigType" SG_ 2566904064 DL_GovernedEngineSpeed 1.7E-308;
BA_ "SigType" SG_ 2566904064 DL_GovernedVesselSpeed 1.7E-308;
BA_ "SigType" SG_ 2566903808 DL_CanisterPurgeSystemPresent 1.7E-308;
BA_ "SigType" SG_ 2566903808 DL_CCPDutyCycle 1.7E-308;
BA_ "SigType" SG_ 2566903552 DL_FailedDTCTestThisIgnCycle 1.7E-308;
BA_ "SigType" SG_ 2566903552 DL_HistoryDataCorrupted 1.7E-308;
BA_ "SigType" SG_ 2566903552 DL_NumWarmUpCycSinceLastDTCSet 1.7E-308;
BA_ "SigType" SG_ 2566903552 DL_TotalEngineRunTime 1.7E-308;
BA_ "SigType" SG_ 2566903296 DL_FanDriver 1.7E-308;
BA_ "SigType" SG_ 2566903296 DL_DesiredFanPosition 1.7E-308;
BA_ "SigType" SG_ 2566903296 DL_FanDutyCycle 1.7E-308;
BA_ "SigType" SG_ 2566902784 DL_DesiredIdleSpd 1.7E-308;
BA_ "SigType" SG_ 2566902784 DL_VirtualIACPosition 1.7E-308;
BA_ "SigType" SG_ 2566902784 DL_LoadAnticipate1Value 1.7E-308;
BA_ "SigType" SG_ 2566902784 DL_LoadAnticipate2Value 1.7E-308;
BA_ "SigType" SG_ 2566902784 DL_ETCIdleStop 1.7E-308;
BA_ "SigType" SG_ 2566902784 DL_CloseThrottleIdleControlMode 1.7E-308;
BA_ "SigType" SG_ 2566902784 DL_IACControlofRPM 1.7E-308;
BA_ "SigType" SG_ 2566902784 DL_LoadAnticipate1 1.7E-308;
BA_ "SigType" SG_ 2566902784 DL_LoadAnticipate2 1.7E-308;
BA_ "SigType" SG_ 2566902528 DL_FiringMode 1.7E-308;
BA_ "SigType" SG_ 2566902528 DL_KnockMonitoring 1.7E-308;
BA_ "SigType" SG_ 2566902528 DL_KnockPresentInLastSec 1.7E-308;
BA_ "SigType" SG_ 2566902528 DL_FuelDetonationControlMode 1.7E-308;
BA_ "SigType" SG_ 2566902528 DL_OctaneRatingStatus 1.7E-308;
BA_ "SigType" SG_ 2566902528 DL_OctaneUpdate 1.7E-308;
BA_ "SigType" SG_ 2566902528 DL_SparkAdvance 1.7E-308;
BA_ "SigType" SG_ 2566902528 DL_CurrentMaxKnockRetardAllCyl 1.7E-308;
BA_ "SigType" SG_ 2566902528 DL_OctaneRating 1.7E-308;
BA_ "SigType" SG_ 2566902528 DL_CurrentCylWithMaxKnockRetard 1.7E-308;
BA_ "SigType" SG_ 2566902528 DL_CamAngle 1.7E-308;
BA_ "SigType" SG_ 2566901504 DL_CamXSensor 1.7E-308;
BA_ "SigType" SG_ 2566901504 DL_CamXPhaser 1.7E-308;
BA_ "SigType" SG_ 2566901504 DL_CamXAngle 1.7E-308;
BA_ "SigType" SG_ 2566901504 DL_ReferenceCamXAngle 1.7E-308;
BA_ "SigType" SG_ 2566901504 DL_CamXPhaserDutyCycle 1.7E-308;
BA_ "SigType" SG_ 2566901248 DL_CamWSensor 1.7E-308;
BA_ "SigType" SG_ 2566901248 DL_CamWPhaser 1.7E-308;
BA_ "SigType" SG_ 2566901248 DL_CamWAngle 1.7E-308;
BA_ "SigType" SG_ 2566901248 DL_ReferenceCamWAngle 1.7E-308;
BA_ "SigType" SG_ 2566901248 DL_CamWPhaserDutyCycle 1.7E-308;
BA_ "SigType" SG_ 2566885888 DL_InjectorBank_APulseWidth 1.7E-308;
BA_ "SigType" SG_ 2566885888 DL_InjectorBank_BPulseWidth 1.7E-308;
BA_ "SigType" SG_ 2566885888 DL_RequiredFuelFlowRate 1.7E-308;
BA_ "SigType" SG_ 2566885888 DL_Airflow 1.7E-308;
BA_ "SPN" SG_ 2566877696 pLeftHandGripTemp 524109;
BA_ "SigType" SG_ 2566877696 pLeftHandGripTemp 1.7E-308;
BA_ "SPN" SG_ 2566877696 pRightHandGripTemp 524110;
BA_ "SigType" SG_ 2566877696 pRightHandGripTemp 1.7E-308;
BA_ "SPN" SG_ 2566877463 pVolumeUnitsSelected 524267;
BA_ "SPN" SG_ 2566877463 pTimeUnitsSelected 524268;
BA_ "SPN" SG_ 2566877463 pTemperatureUnitsSelected 524266;
BA_ "SPN" SG_ 2566877463 pPressureUnitsSelected 524269;
BA_ "SPN" SG_ 2566877463 pHighResTrip2Distance 524264;
BA_ "SPN" SG_ 2566877463 pDistanceUnitsSelected 524265;
BA_ "SPN" SG_ 2566877463 pTPMSLearningStatus 524104;
BA_ "SigType" SG_ 2566877463 pTPMSLearningStatus 1.7E-308;
BA_ "SPN" SG_ 2566877463 pDisplayStatus 524105;
BA_ "SigType" SG_ 2566877463 pDisplayStatus 1.7E-308;
BA_ "SPN" SG_ 2566876711 pEngineOilPressureStatus 524076;
BA_ "SigType" SG_ 2566876711 pEngineOilPressureStatus 1.7E-308;
BA_ "SPN" SG_ 2566876711 pHydraulicOilPressureStatus 524075;
BA_ "SigType" SG_ 2566876711 pHydraulicOilPressureStatus 1.7E-308;
BA_ "SPN" SG_ 2566876711 pHydraulicOilTempStatus 524074;
BA_ "SigType" SG_ 2566876711 pHydraulicOilTempStatus 1.7E-308;
BA_ "SPN" SG_ 2633984551 pHeatedGripEnable 520366;
BA_ "SPN" SG_ 2633984551 pSideStandStatus 524098;
BA_ "SigType" SG_ 2633984551 pSideStandStatus 1.7E-308;
BA_ "SPN" SG_ 2633984551 pTetherSwitchStatus 520600;
BA_ "SPN" SG_ 2633984551 pLowFuelIndicatorStatus 524087;
BA_ "SPN" SG_ 2633984551 pOperatorNotInOperatingStation 2832;
BA_ "SPN" SG_ 2633984551 pParkBrakeIndicatorStatus 524271;
BA_ "SPN" SG_ 2633984551 pADCRequested 524139;
BA_ "SPN" SG_ 2633984551 pAWDModeRequested 524138;
BA_ "SPN" SG_ 2633984551 pRWDModeRequested 524137;
BA_ "SPN" SG_ 2633984551 pTurfModeRequested 524136;
BA_ "SPN" SG_ 2633984551 pADCStatus 524013;
BA_ "SigType" SG_ 2633984551 pADCStatus 1.7E-308;
BA_ "SPN" SG_ 2633984551 pTreadleNeutralStatus 524017;
BA_ "SigType" SG_ 2633984551 pTreadleNeutralStatus 1.7E-308;
BA_ "SPN" SG_ 2633984551 pTreadleReverseStatus 524018;
BA_ "SigType" SG_ 2633984551 pTreadleReverseStatus 1.7E-308;
BA_ "SPN" SG_ 2633984551 pSecurityLightStatus 524019;
BA_ "SigType" SG_ 2633984551 pSecurityLightStatus 1.7E-308;
BA_ "SPN" SG_ 2633984551 pHighBeamIndicatorStatus 524084;
BA_ "SigType" SG_ 2633984551 pHighBeamIndicatorStatus 1.7E-308;
BA_ "SPN" SG_ 2633984551 pHeatedGripsPercentage 524096;
BA_ "SigType" SG_ 2633984551 pHeatedGripsPercentage 1.7E-308;
BA_ "SPN" SG_ 2633984551 pCruiseControlSetStatus 524097;
BA_ "SigType" SG_ 2633984551 pCruiseControlSetStatus 1.7E-308;
BA_ "SPN" SG_ 2633984551 pSeatBeltIndicatorStatus 524092;
BA_ "SigType" SG_ 2633984551 pSeatBeltIndicatorStatus 1.7E-308;
BA_ "SPN" SG_ 2432656679 pOperatorButton29 524060;
BA_ "SPN" SG_ 2432656679 pOperatorButton1 524059;
BA_ "SigType" SG_ 2432656679 pOperatorButton1 1.7E-308;
BA_ "SPN" SG_ 2432656679 pOperatorButton2 524058;
BA_ "SigType" SG_ 2432656679 pOperatorButton2 1.7E-308;
BA_ "SPN" SG_ 2432656679 pOperatorButton3 524057;
BA_ "SigType" SG_ 2432656679 pOperatorButton3 1.7E-308;
BA_ "SPN" SG_ 2432656679 pOperatorButton4 524056;
BA_ "SigType" SG_ 2432656679 pOperatorButton4 1.7E-308;
BA_ "SPN" SG_ 2432656679 pOperatorButton5 524055;
BA_ "SigType" SG_ 2432656679 pOperatorButton5 1.7E-308;
BA_ "SPN" SG_ 2432656679 pOperatorButton6 524054;
BA_ "SigType" SG_ 2432656679 pOperatorButton6 1.7E-308;
BA_ "SPN" SG_ 2432656679 pOperatorButton7 524053;
BA_ "SigType" SG_ 2432656679 pOperatorButton7 1.7E-308;
BA_ "SPN" SG_ 2432656679 pOperatorButton8 524052;
BA_ "SigType" SG_ 2432656679 pOperatorButton8 1.7E-308;
BA_ "SPN" SG_ 2432656679 pOperatorButton9 524051;
BA_ "SigType" SG_ 2432656679 pOperatorButton9 1.7E-308;
BA_ "SPN" SG_ 2432656679 pOperatorButton10 524050;
BA_ "SigType" SG_ 2432656679 pOperatorButton10 1.7E-308;
BA_ "SPN" SG_ 2432656679 pOperatorButton11 524049;
BA_ "SigType" SG_ 2432656679 pOperatorButton11 1.7E-308;
BA_ "SPN" SG_ 2432656679 pOperatorButton12 524048;
BA_ "SigType" SG_ 2432656679 pOperatorButton12 1.7E-308;
BA_ "SPN" SG_ 2432656679 pOperatorButton13 524047;
BA_ "SigType" SG_ 2432656679 pOperatorButton13 1.7E-308;
BA_ "SPN" SG_ 2432656679 pOperatorButton14 524046;
BA_ "SigType" SG_ 2432656679 pOperatorButton14 1.7E-308;
BA_ "SPN" SG_ 2432656679 pOperatorButton15 524045;
BA_ "SigType" SG_ 2432656679 pOperatorButton15 1.7E-308;
BA_ "SPN" SG_ 2432656679 pOperatorButton16 524044;
BA_ "SigType" SG_ 2432656679 pOperatorButton16 1.7E-308;
BA_ "SPN" SG_ 2432656679 pOperatorButton17 524043;
BA_ "SigType" SG_ 2432656679 pOperatorButton17 1.7E-308;
BA_ "SPN" SG_ 2432656679 pOperatorButton18 524042;
BA_ "SigType" SG_ 2432656679 pOperatorButton18 1.7E-308;
BA_ "SPN" SG_ 2432656679 pOperatorButton19 524041;
BA_ "SigType" SG_ 2432656679 pOperatorButton19 1.7E-308;
BA_ "SPN" SG_ 2432656679 pOperatorButton20 524040;
BA_ "SigType" SG_ 2432656679 pOperatorButton20 1.7E-308;
BA_ "SPN" SG_ 2432656679 pOperatorButton21 524039;
BA_ "SigType" SG_ 2432656679 pOperatorButton21 1.7E-308;
BA_ "SPN" SG_ 2432656679 pOperatorButton22 524038;
BA_ "SigType" SG_ 2432656679 pOperatorButton22 1.7E-308;
BA_ "SPN" SG_ 2432656679 pOperatorButton23 524037;
BA_ "SigType" SG_ 2432656679 pOperatorButton23 1.7E-308;
BA_ "SPN" SG_ 2432656679 pOperatorButton24 524036;
BA_ "SigType" SG_ 2432656679 pOperatorButton24 1.7E-308;
BA_ "SPN" SG_ 2432656679 pOperatorButton25 524035;
BA_ "SigType" SG_ 2432656679 pOperatorButton25 1.7E-308;
BA_ "SPN" SG_ 2432656679 pOperatorButton26 524034;
BA_ "SigType" SG_ 2432656679 pOperatorButton26 1.7E-308;
BA_ "SPN" SG_ 2432656679 pOperatorButton27 520322;
BA_ "SigType" SG_ 2432656679 pOperatorButton27 1.7E-308;
BA_ "SPN" SG_ 2432656679 pOperatorButton28 524032;
BA_ "SigType" SG_ 2432656679 pOperatorButton28 1.7E-308;
BA_ "SPN" SG_ 2432656679 pSideStandStatus 524098;
BA_ "SigType" SG_ 2432656679 pSideStandStatus 1.7E-308;
BA_ "SPN" SG_ 2566845479 TireLocation 929;
BA_ "SigType" SG_ 2566845479 TireLocation 1.7E-308;
BA_ "SPN" SG_ 2566845479 TirePressure 241;
BA_ "SigType" SG_ 2566845479 TirePressure 1.7E-308;
BA_ "SPN" SG_ 2566845479 TireTemperature 242;
BA_ "SigType" SG_ 2566845479 TireTemperature 1.7E-308;
BA_ "SPN" SG_ 3221225472 HVES1HVBPsvITR_8432 8432;
BA_ "SPN" SG_ 3221225472 HVES1HVBAcvITR_8431 8431;
BA_ "SPN" SG_ 3221225472 HVES1LoCellStOChaCellNo_8248 8248;
BA_ "SPN" SG_ 3221225472 HVES1LoCellStOChaModuNo_8247 8247;
BA_ "SPN" SG_ 3221225472 HVES1HiCellStOChaCellNo_8246 8246;
BA_ "SPN" SG_ 3221225472 HVES1HiCellStOChaModuNo_8245 8245;
BA_ "SPN" SG_ 3221225472 TranIdleGovrnrFuelingInhbit_7829 7829;
BA_ "SPN" SG_ 3221225472 NumberOfMembersInWorkingSet 2409;
BA_ "SigType" SG_ 3221225472 NumberOfMembersInWorkingSet 3;
BA_ "SPN" SG_ 3221225472 SourceAddress 5600;
BA_ "SPN" SG_ 3221225472 NncntnuslyMonitoredSystemsStatus 1223;
BA_ "SPN" SG_ 3221225472 NncntnslyMonitoredSystemsSupport 1222;
BA_ "SPN" SG_ 3221225472 CntnslyMntrdSystmsSupport_Status 1221;
BA_ "SPN" SG_ 3221225472 AETCTorqueValue 3561;
BA_ "SigType" SG_ 3221225472 AETCTorqueValue 1;
BA_ "SPN" SG_ 3221225472 TrailerWeight 180;
BA_ "SigType" SG_ 3221225472 TrailerWeight 1;
BA_ "SPN" SG_ 3221225472 ReferenceTirePressSetting 3193;
BA_ "SPN" SG_ 3221225472 ReferenceTirePress 3191;
BA_ "SPN" SG_ 3221225472 TirePressThresholdDetection 2587;
BA_ "SPN" SG_ 3221225472 TireAirLeakageRate 2586;
BA_ "SigType" SG_ 3221225472 TireAirLeakageRate 1;
BA_ "SPN" SG_ 3221225472 CTIWheelEndElectricalFault 1697;
BA_ "SigType" SG_ 3221225472 CTIWheelEndElectricalFault 4;
BA_ "SPN" SG_ 3221225472 CTITireStatus 1698;
BA_ "SigType" SG_ 3221225472 CTITireStatus 4;
BA_ "SPN" SG_ 3221225472 CTIWheelSensorStatus 1699;
BA_ "SigType" SG_ 3221225472 CTIWheelSensorStatus 4;
BA_ "SPN" SG_ 3221225472 TireTemp 242;
BA_ "SigType" SG_ 3221225472 TireTemp 1;
BA_ "SPN" SG_ 3221225472 TirePress 241;
BA_ "SigType" SG_ 3221225472 TirePress 1;
BA_ "SPN" SG_ 3221225472 EngTurningGearEngaged 1206;
BA_ "SigType" SG_ 3221225472 EngTurningGearEngaged 4;
BA_ "SPN" SG_ 3221225472 AETCSpeedValue 3560;
BA_ "SigType" SG_ 3221225472 AETCSpeedValue 1;

VAL_ 3221225472 DM_FailureModeIdentifier 0 "Above normal (most severe)" 1 "Below normal (most severe)" 2 "Data erratic" 3 "Voltage above normal" 4 "Voltage below normal" 5 "Current below normal" 6 "Current above normal" 7 "Mechanical system not responding" 8 "Abnormal frequency" 9 "Abnormal update rate" 10 "Abnormal rate of change" 11 "Root cause not known" 12 "Bad intelligent device" 13 "Out of calibration" 14 "Special intstructions" 15 "Above normal (least severe)" 16 "Above normal (moderately severe)" 17 "Below normal (least severe)" 18 "Below normal (moderatels severe)" 19 "Received network data in error" 31 "Not available";
VAL_ 2564292857 DM15_Seed 0 "Seed Complete - send key" 1 "Use Long Seed or Key" 65535 "No Further Key required of Tool";
VAL_ 2564292857 DM15_Error_Ind_EDC_Parameter 0 "No Error" 1 "Error NOT identified" 2 "Currently processing for another" 16 "Currently processing Erase Req" 17 "Currently processing Read Req" 18 "Currently processing Write Req" 19 "Currently processing Status Req" 22 "Currently processing Boot Req" 23 "Currently processing Gen Req" 31 "Currently processing request" 32 "EDC parm not correct for data" 33 "RAM did not verify on Write" 34 "FLASH did not verify on Write" 35 "PROM did not verify on Write" 36 "Internal failure preventing req" 256 "Addressing or DATA General Error" 257 "Addressing Error bounds invalid" 258 "Addressing Error Length invalid" 259 "Addressing Error exceeded memory" 260 "Addressing Error requires erase" 261 "Addressing Error requires erase" 262 "Addressing Error requires trans" 263 "Addressing Error wrong memory" 264 "Addressing Error invalid bounds" 265 "DATA Error invalid value ranges" 266 "DATA Error NAME unexpected value" 4096 "Security Error General" 4097 "Security Error Invalid Password" 4098 "Security Error Invalid User Lvl" 4099 "Security Error Invalid Key" 4100 "Security Error NOT in Diag mode" 4101 "Security Error NOT in Dev mode" 4102 "Security Error - Engine running" 4103 "Security Error - NOT in Park" 65536 "Abort from external" 65537 "Too Many Retries" 65538 "NO response in the time allowed" 65539 "Transport NOT initiated in time" 65540 "Transport NOT completed in time" 16777215 "No Error Indicator Available";
VAL_ 2564292857 DM15_EDCP_Extension 0 "Completed" 2 "More, Higher order EDC Parameter" 3 "More, Lower order EDC Parameter" 6 "Data in Error Indicator" 7 "Data in Error Indicator" 255 "No Error/EDC Parameter Available";
VAL_ 2564292857 DM15_Status 0 "Proceed" 1 "Busy" 2 "Reserved" 3 "Reserved" 4 "Operation Completed" 5 "Operation Failed" 6 "Reserved" 7 "Reserved";
VAL_ 2564358393 DM14_Pointer_Type 0 "Direct Memory Addressing" 1 "Directed Spatial Addressing";
VAL_ 2564358393 DM14_Command 0 "Erase" 1 "Read" 2 "Write" 3 "Status Request" 4 "Operation Completed" 5 "Operation Failed" 6 "Boot Load" 7 "EDCP Generation";
VAL_ 2633984602 pHeatedGripEnable 0 "Disabled (Not installed)" 1 "Enabled (Installed)" 2 "Error Indicator" 3 "Description for the value '3'";
VAL_ 2633984602 pSideStandStatus 0 "Side Stand Down" 1 "Side Stand Up" 2 "Error Indicator" 3 "Not Available";
VAL_ 2633984602 pTetherSwitchStatus 0 "Tether SW Closed (connected)" 1 "Tether SW Open (disconnected)" 2 "Error" 3 "Not Available";
VAL_ 2633984602 pLowFuelIndicatorStatus 0 "Low Fuel Indicator Off" 1 "Low Fuel Indicator On" 2 "Error" 3 "Not Available";
VAL_ 2633984602 pOperatorNotInOperatingStation 0 "Operator In OperatorStation" 1 "Operator Not In OperatorStation" 2 "Error" 3 "Description for the value '3'";
VAL_ 2633984602 pParkBrakeIndicatorStatus 0 "Park Brake Indicator Off" 1 "Park Brake Indicator On (Solid)" 2 "Park Brake Indicator 1 Hz flash" 3 "Park Brake Indicator 2 Hz flash" 4 "Available for future use" 5 "Available for future use" 6 "Error Indicator" 7 "Not Available";
VAL_ 2633984602 pADCRequested 0 "ADC Mode not Requested" 1 "ADC Mode Requested" 2 "Error" 3 "Not Available";
VAL_ 2633984602 pAWDModeRequested 0 "AWD Mode not Requested" 1 "AWD Mode Requested" 2 "Error" 3 "Not Available";
VAL_ 2633984602 pRWDModeRequested 0 "RWD Mode not Requested" 1 "RWD Mode Requested" 2 "Error" 3 "Not Available";
VAL_ 2633984602 pTurfModeRequested 0 "Turf Mode not Requested" 1 "Turf Mode Requested" 2 "Error" 3 "Not Available";
VAL_ 2633984602 pADCStatus 0 "ADC Actuator Not Engaged" 1 "ADC Actuator Engaged" 2 "Error" 3 "Not available";
VAL_ 2633984602 pTreadleNeutralStatus 0 "Treadle Neutral Not Engaged" 1 "Treadle Neutral Engaged" 2 "Error" 3 "Not Available";
VAL_ 2633984602 pTreadleReverseStatus 0 "Treadle Reverse Not Engaged" 1 "Treadle Reverse Engaged" 2 "Error" 3 "Not Available";
VAL_ 2633984602 pSecurityLightStatus 0 "Off" 1 "On (Solid)" 2 "Error (Flashing)" 3 "Not Available";
VAL_ 2633984602 pHighBeamIndicatorStatus 0 "Indicator Off" 1 "Indicator On" 2 "Error (Indicator Flashing)" 3 "Not Available";
VAL_ 2633984602 pCruiseControlSetStatus 0 "Cruise Not Set" 1 "Cruise Set" 2 "Error (Lamp Flashing)" 3 "Not Available";
VAL_ 2633984602 pSeatBeltIndicatorStatus 0 "Seat_Belt_Indicator_Off" 1 "Seat_Belt_Indicator_On_Solid" 2 "Seat_Belt_Indicator_1Hz" 3 "Seat_Belt_Indicator_2Hz" 4 "Future1" 5 "Future2" 6 "Error" 7 "Not_Available";
VAL_ 2566876762 pEngineOilPressureStatus 0 "Not OK; Pressure is too low" 1 "OK; Pressure is above minimum" 2 "Error" 3 "Not Available";
VAL_ 2566876762 pHydraulicOilPressureStatus 0 "Not OK; Pressure too low" 1 "OK; Pressure above minimum" 2 "Error" 3 "Not Available";
VAL_ 2566876762 pHydraulicOilTempStatus 0 "Not OK; Temp too high" 1 "OK; Temp is below max" 2 "Error" 3 "Not Available";
VAL_ 2566876672 pEngineOilPressureStatus 0 "Not OK; Pressure is too low" 1 "OK; Pressure is above minimum" 2 "Error" 3 "Not Available";
VAL_ 2566876672 pHydraulicOilPressureStatus 0 "Not OK; Pressure too low" 1 "OK; Pressure above minimum" 2 "Error" 3 "Not Available";
VAL_ 2566876672 pHydraulicOilTempStatus 0 "Not OK; Temp too high" 1 "OK; Temp is below max" 2 "Error" 3 "Not Available";
VAL_ 2565866755 TransmissionRqstedRange 18464 " H" 19488 " L" 20000 " N" 20512 " P" 21024 " R";
VAL_ 2566844675 TwoSpeedAxleSwitch 0 "LowSpeedRange" 1 "HighSpeedRange" 2 "Error" 3 "NotAvailable";
VAL_ 2566844675 ParkingBrakeSwitch 0 "NotSet" 1 "Set" 2 "Error" 3 "NotAvailable";
VAL_ 2566844675 CruiseCtrlActive 0 "SwitchedOff" 1 "SwitchedOn" 2 "Error" 3 "NotAvailable";
VAL_ 2566844675 CruiseCtrlEnableSwitch 0 "Disabled" 1 "Enabled" 2 "Error" 3 "NotAvailable";
VAL_ 2566844675 BrakeSwitch 0 "PedalReleased" 1 "PedalDepressed" 2 "Error" 3 "NotAvailable";
VAL_ 2566844675 ClutchSwitch 0 "PedalReleased" 1 "PedalDepressed" 2 "Error" 3 "NotAvailable";
VAL_ 2566844675 CruiseCtrlSetSwitch 0 "NotSet" 1 "Set" 2 "Error" 3 "NotAvailable";
VAL_ 2566844675 CruiseCtrlCoastSwitch 0 "NotCoast" 1 "Coast" 2 "Error" 3 "NotAvailable";
VAL_ 2566844675 CruiseCtrlResumeSwitch 0 "NotResume" 1 "Resume" 2 "Error" 3 "NotAvailable";
VAL_ 2566844675 CruiseCtrlAccelerateSwitch 0 "NotAccelerate" 1 "Accelerate" 2 "Error" 3 "NotAvailable";
VAL_ 2566844675 pOdometerDriveBit 0 "State A" 1 "State B" 2 "Error" 3 "Not Available/Initialize";
VAL_ 2566844675 CruiseCtrlPauseSw 0 "Off" 1 "On" 2 "Error" 3 "Take No Action";
VAL_ 2566844675 pCruiseEnableStatus 0 "Not enabled." 1 "Enabled but not activated." 2 "Reserved" 14 "Error Indicator" 15 "Not Available";
VAL_ 2566878554 pOperationMode 0 "Manned" 1 "Remote" 2 "Error" 3 "Not Available";
VAL_ 2566878554 pStartStopCmd 0 "Button Not Pressed" 1 "Button Pressed" 2 "Error" 3 "Not Available";
VAL_ 2566844762 TwoSpeedAxleSwitch 0 "LowSpeedRange" 1 "HighSpeedRange" 2 "Error" 3 "NotAvailable";
VAL_ 2566844762 ParkingBrakeSwitch 0 "NotSet" 1 "Set" 2 "Error" 3 "NotAvailable";
VAL_ 2566844762 CruiseCtrlActive 0 "SwitchedOff" 1 "SwitchedOn" 2 "Error" 3 "NotAvailable";
VAL_ 2566844762 CruiseCtrlEnableSwitch 0 "Disabled" 1 "Enabled" 2 "Error" 3 "NotAvailable";
VAL_ 2566844762 BrakeSwitch 0 "PedalReleased" 1 "PedalDepressed" 2 "Error" 3 "NotAvailable";
VAL_ 2566844762 ClutchSwitch 0 "PedalReleased" 1 "PedalDepressed" 2 "Error" 3 "NotAvailable";
VAL_ 2566844762 CruiseCtrlSetSwitch 0 "NotSet" 1 "Set" 2 "Error" 3 "NotAvailable";
VAL_ 2566844762 CruiseCtrlCoastSwitch 0 "NotCoast" 1 "Coast" 2 "Error" 3 "NotAvailable";
VAL_ 2566844762 CruiseCtrlResumeSwitch 0 "NotResume" 1 "Resume" 2 "Error" 3 "NotAvailable";
VAL_ 2566844762 CruiseCtrlAccelerateSwitch 0 "NotAccelerate" 1 "Accelerate" 2 "Error" 3 "NotAvailable";
VAL_ 2566844762 pOdometerDriveBit 0 "State A" 1 "State B" 2 "Error" 3 "Not Available/Initialize";
VAL_ 2566844762 CruiseCtrlPauseSw 0 "Off" 1 "On" 2 "Error" 3 "Take No Action";
VAL_ 2566844762 pCruiseEnableStatus 0 "Not enabled." 1 "Enabled but not activated." 2 "Reserved" 14 "Error Indicator" 15 "Not Available";
VAL_ 2365526260 WATT_pFloat_State 0 "Electrolyte Level Ok" 1 "Low Electrolyte Level Detected" 2 "Error" 3 "Not Available";
VAL_ 2365526259 WATT_pFloat_State 0 "Electrolyte Level Ok" 1 "Low Electrolyte Level Detected" 2 "Error" 3 "Not Available";
VAL_ 2365526516 WATT_pBatteryType 4 "Flooded Lead Acid 12V" 6 "Flooded Lead Acid 6V" 68 "AGM Lead Acid 12V" 70 "AGM Lead Acid 6V" 128 "Li-Ion Pack";
VAL_ 2365526516 WATT_pWAKE_State 0 "Off" 1 "Active" 2 "Error" 3 "Not Available";
VAL_ 2365526516 WATT_pKEY_State 0 "Off" 1 "On" 2 "Error" 3 "Not Available";
VAL_ 2365526516 WATT_pDC_DC_State 0 "Off" 1 "Reserved" 2 "Reserved" 3 "Reserved" 4 "Powered, Disabled" 5 "Power, Enabled" 6 "Error" 7 "Not Available";
VAL_ 2365526516 WATT_pBalance_State 0 "Power Up" 1 "Driving" 2 "Resting" 3 "Reserved" 4 "Charging" 5 "Reserved" 6 "Reserved" 7 "Reserved" 8 "Relaxing" 9 "Reserved" 10 "Reserved" 11 "Reserved" 12 "Reserved" 13 "Reserved" 14 "Reserved" 15 "Not Available";
VAL_ 2365526772 WATT_pCharger_State 0 "Off" 1 "High Voltage Shutdown" 2 "Low Voltage Shutdown" 3 "Check Battery Shutdown" 4 "Charge Timeout" 5 "Over Temp Shutdown" 6 "Internal Fault Shutdown" 7 "Reserved" 8 "Reserved" 9 "Reserved" 10 "Reserved" 11 "Reserved" 12 "Reserved" 13 "Reserved" 14 "Reserved" 15 "Reserved" 16 "Recovery Phase" 17 "Bulk Phase" 18 "Absorption Phase" 19 "Finish Phase" 20 "Reduced Performance" 21 "Reserved" 22 "Reserved" 23 "Reserved" 24 "Charge Complete" 25 "Float Charging" 26 "Equalize,Balance Charging" 27 "Maintanence Charging" 28 "Reserved" 29 "Reserved" 30 "Reserved" 31 "Not Available";
VAL_ 2365526772 WATT_pAC_Status 0 "No AC Present" 1 "AC Present, Voltage Level N/A" 2 "110 AC, reduced pwr low Voltage" 3 "110 AC" 4 "220 AC, reduced pwr low Voltage" 5 "220 AC" 6 "Error" 7 "Not Available";
VAL_ 2365526515 WATT_pBatteryType 4 "Flooded Lead Acid 12V" 6 "Flooded Lead Acid 6V" 68 "AGM Lead Acid 12V" 70 "AGM Lead Acid 6V" 128 "Li-Ion Pack";
VAL_ 2365526515 WATT_pWAKE_State 0 "Off" 1 "Active" 2 "Error" 3 "Not Available";
VAL_ 2365526515 WATT_pKEY_State 0 "Off" 1 "On" 2 "Error" 3 "Not Available";
VAL_ 2365526515 WATT_pDC_DC_State 0 "Off" 1 "Reserved" 2 "Reserved" 3 "Reserved" 4 "Powered, Disabled" 5 "Power, Enabled" 6 "Error" 7 "Not Available";
VAL_ 2365526515 WATT_pBalance_State 0 "Power Up" 1 "Driving" 2 "Resting" 3 "Reserved" 4 "Charging" 5 "Reserved" 6 "Reserved" 7 "Reserved" 8 "Relaxing" 9 "Reserved" 10 "Reserved" 11 "Reserved" 12 "Reserved" 13 "Reserved" 14 "Reserved" 15 "Not Available";
VAL_ 2365526771 WATT_pCharger_State 0 "Off" 1 "High Voltage Shutdown" 2 "Low Voltage Shutdown" 3 "Check Battery Shutdown" 4 "Charge Timeout" 5 "Over Temp Shutdown" 6 "Internal Fault Shutdown" 7 "Reserved" 8 "Reserved" 9 "Reserved" 10 "Reserved" 11 "Reserved" 12 "Reserved" 13 "Reserved" 14 "Reserved" 15 "Reserved" 16 "Recovery Phase" 17 "Bulk Phase" 18 "Absorption Phase" 19 "Finish Phase" 20 "Reduced Performance" 21 "Reserved" 22 "Reserved" 23 "Reserved" 24 "Charge Complete" 25 "Float Charging" 26 "Equalize,Balance Charging" 27 "Maintanence Charging" 28 "Reserved" 29 "Reserved" 30 "Reserved" 31 "Not Available";
VAL_ 2365526771 WATT_pAC_Status 0 "No AC Present" 1 "AC Present, Voltage Level N/A" 2 "110 AC, reduced pwr low Voltage" 3 "110 AC" 4 "220 AC, reduced pwr low Voltage" 5 "220 AC" 6 "Error" 7 "Not Available";
VAL_ 2298415094 WATT_pPerformance_State 0 "Initialize" 1 "Shutdown" 2 "Precharge" 3 "Energized" 4 "Enabled" 5 "Fault Off" 6 "Fault Reaction" 7 "Reserved" 8 "Reserved" 9 "Reserved" 10 "Reserved" 11 "Reserved" 12 "Reserved" 13 "Reserved" 14 "Reserved" 15 "Not Available";
VAL_ 2298415095 WATT_pPerformance_State 0 "Initialize" 1 "Shutdown" 2 "Precharge" 3 "Energized" 4 "Enabled" 5 "Fault Off" 6 "Fault Reaction" 7 "Reserved" 8 "Reserved" 9 "Reserved" 10 "Reserved" 11 "Reserved" 12 "Reserved" 13 "Reserved" 14 "Reserved" 15 "Not Available";
VAL_ 2298415090 WATT_pPerformance_State 0 "Initialize" 1 "Shutdown" 2 "Precharge" 3 "Energized" 4 "Enabled" 5 "Fault Off" 6 "Fault Reaction" 7 "Reserved" 8 "Reserved" 9 "Reserved" 10 "Reserved" 11 "Reserved" 12 "Reserved" 13 "Reserved" 14 "Reserved" 15 "Not Available";
VAL_ 2298415089 WATT_pPerformance_State 0 "Initialize" 1 "Shutdown" 2 "Precharge" 3 "Energized" 4 "Enabled" 5 "Fault Off" 6 "Fault Reaction" 7 "Reserved" 8 "Reserved" 9 "Reserved" 10 "Reserved" 11 "Reserved" 12 "Reserved" 13 "Reserved" 14 "Reserved" 15 "Not Available";
VAL_ 2298415088 WATT_pPerformance_State 0 "Initialize" 1 "Shutdown" 2 "Precharge" 3 "Energized" 4 "Enabled" 5 "Fault Off" 6 "Fault Reaction" 7 "Reserved" 8 "Reserved" 9 "Reserved" 10 "Reserved" 11 "Reserved" 12 "Reserved" 13 "Reserved" 14 "Reserved" 15 "Not Available";
VAL_ 2298415087 WATT_pPerformance_State 0 "Initialize" 1 "Shutdown" 2 "Precharge" 3 "Energized" 4 "Enabled" 5 "Fault Off" 6 "Fault Reaction" 7 "Reserved" 8 "Reserved" 9 "Reserved" 10 "Reserved" 11 "Reserved" 12 "Reserved" 13 "Reserved" 14 "Reserved" 15 "Not Available";
VAL_ 2566834735 DM_FlashRedStopLamp 0 "Slow Flash (1 Hz, 50% DC)" 1 "Fast Flash (2 Hz, 50% DC)" 2 "Reserved" 3 "Unavailable / Do Not Flash";
VAL_ 2566834735 DM_FlashProtectLamp 0 "Slow Flash (1 Hz, 50% DC)" 1 "Fast Flash (2 Hz, 50% DC)" 2 "Reserved" 3 "Unavailable / Do Not Flash";
VAL_ 2566834735 DM_FlashMalfuncIndicatorLamp 0 "Slow Flash (1 Hz, 50% DC)" 1 "Fast Flash (2 Hz, 50% DC)" 2 "Reserved" 3 "Unavailable / Do Not Flash";
VAL_ 2566834735 DM_FlashAmberWarningLamp 0 "Slow Flash (1 Hz, 50% DC)" 1 "Fast Flash (2 Hz, 50% DC)" 2 "Reserved" 3 "Unavailable / Do Not Flash";
VAL_ 2566834735 DM_ProtectLampStatus 0 "Lamp off" 1 "Lamp on" 2 "Reserved" 3 "Not available";
VAL_ 2566834735 DM_RedStopLampState 0 "Lamp off" 1 "Lamp on" 2 "Reserved" 3 "Not available";
VAL_ 2566834735 DM_AmberWrningLmpStatus 0 "Lamp off" 1 "Lamp on" 2 "Reserved" 3 "Not available";
VAL_ 2566834735 DM_MalfuncnIndicatorLampStatus 0 "Lamp off" 1 "Lamp on" 2 "Reserved" 3 "Not available";
VAL_ 2566903040 DL_BoostBypassOutputActive 0 "Inactive" 1 "Active";
VAL_ 2566903040 DL_CruiseLampOutputActive 0 "Inactive" 1 "Active";
VAL_ 2566903040 DL_FuelSelectOutput2Active 0 "Inactive" 1 "Active";
VAL_ 2566903040 DL_FuelSelectOutput1Active 0 "Inactive" 1 "Active";
VAL_ 2566903040 DL_OemOutput4Active 0 "Inactive" 1 "Active";
VAL_ 2566903040 DL_OemOutput3Active 0 "Inactive" 1 "Active";
VAL_ 2566903040 DL_OemOutput2Active 0 "Inactive" 1 "Active";
VAL_ 2566903040 DL_OemOutput1Active 0 "Inactive" 1 "Active";
VAL_ 2566903040 DL_FuelPump2RelayOutputActive 0 "Inactive" 1 "Active";
VAL_ 2566903040 DL_IntercoolerOutputActive 0 "Inactive" 1 "Active";
VAL_ 2566903040 DL_ClutchSwitchInputActive 0 "Inactive" 1 "Active";
VAL_ 2566903040 DL_BrakeSwitchInputActive 0 "Inactive" 1 "Active";
VAL_ 2566903040 DL_ReverseSwitchInputActive 0 "Inactive" 1 "Active";
VAL_ 2566903040 DL_CrankReqInput 0 "Inactive" 1 "Active";
VAL_ 2566903040 DL_LowOilLevelInput 0 "Inactive" 1 "Active";
VAL_ 2566903040 DL_LoadAnticipate1Input 0 "Inactive" 1 "Active";
VAL_ 2566903040 DL_LoadAnticipate2Input 0 "Inactive" 1 "Active";
VAL_ 2566903040 DL_CruiseDecelInputActive 0 "Inactive" 1 "Active";
VAL_ 2566903040 DL_CruiseAccelInputActive 0 "Inactive" 1 "Active";
VAL_ 2566903040 DL_PowertrainRelayOutput 0 "Inactive" 1 "Active";
VAL_ 2566903040 DL_StarterRelayOutput 0 "Inactive" 1 "Active";
VAL_ 2566903040 DL_FuelPump1RelayOutput 0 "Inactive" 1 "Active";
VAL_ 2566903040 DL_SlowmodeInputActive 0 "Inactive" 1 "Active";
VAL_ 2566903040 DL_SlowModeLampOutput 0 "Inactive" 1 "Active";
VAL_ 2566903040 DL_GovCruiseSync 0 "Inactive" 1 "Active";
VAL_ 2566903040 DL_DiscreteLowOilPressInput 0 "Inactive" 1 "Active";
VAL_ 2566903040 DL_MILOutput 0 "Inactive" 1 "Active";
VAL_ 2566855680 pFan1DirectionCmd 0 "Forward" 1 "Reverse" 2 "Reserved" 3 "Description for the value '3'";
VAL_ 2566886912 pFleetMgmtDefVehState 0 "Vehicle Disable Default State" 1 "Vehicle Speed Limit 1" 2 "Vehicle Speed Limit 2" 3 "Vehicle Speed Limit 3" 4 "Vehicle Speed Limit 4" 5 "Vehicle Speed Limit 5" 6 "Vehicle Speed Limit 6" 7 "Vehicle Speed Limit 7" 8 "Reserved" 9 "Reserved" 10 "Reserved" 11 "Reserved" 12 "Reserved" 13 "Reserved" 14 "Error State" 15 "Not Available";
VAL_ 2566886912 pVehEnblDisbl 0 "Normal Operation - Veh Enable" 1 "Normal Operation - Veh Disable" 2 "Reserved" 3 "Reserved" 4 "Reserved" 5 "Reserved" 6 "Reserved" 7 "Reserved" 8 "Reserved" 9 "Reserved" 10 "Reserved" 11 "Reserved" 12 "Reserved" 13 "Reserved" 14 "Error State" 15 "Not Available";
VAL_ 2566886912 pUserAuthenticationStatus 0 "Normal Operation - No ID Reqd" 1 "Normal Operation - ID Reqd" 2 "Reserved" 3 "Reserved" 4 "Reserved" 5 "Reserved" 6 "Reserved" 7 "Reserved" 8 "Reserved" 9 "Reserved" 10 "Reserved" 11 "Reserved" 12 "Reserved" 13 "Reserved" 14 "Error State" 15 "Not Available";
VAL_ 2566886912 pBoundaryStatus 0 "Normal Operation-Inside Boundary" 1 "Normal Operation-Outsid Boundary" 2 "Reserved" 3 "Reserved" 4 "Reserved" 5 "Reserved" 6 "Reserved" 7 "Reserved" 8 "Reserved" 9 "Reserved" 10 "Reserved" 11 "Reserved" 12 "Reserved" 13 "Reserved" 14 "Error State" 15 "Not Available";
VAL_ 2566878227 pEPSSASCalibrated 0 "SAS not calibrated" 1 "SAS calibrated" 2 "Reserved" 3 "Not available";
VAL_ 2566878227 pEPSOperationStatus 0 "Fully Functional" 1 "Backup Mode" 2 "Limp Home Mode" 3 "Not Used" 4 "Not Used" 5 "Error (non dunctional with DM1)" 6 "Reserved" 7 "Not Available";
VAL_ 2566878227 pEPSOperationMode 0 "Off" 2 "Torque Assist" 3 "Speed" 4 "Position" 5 "Position w/Speed" 16 "Set Position";
VAL_ 2566878987 DL22_DynoMode 0 "Active" 1 "Inactive";
VAL_ 2566910503 FI4_SeatbeltSw 0 "False" 1 "True" 2 "Error" 3 "Not Available";
VAL_ 2566910503 FI4_pSideStandSw 0 "Active" 1 "Inactive" 2 "Error" 3 "Not Available";
VAL_ 2566910503 FI4_DrvlnMomentaryRight 0 "False" 1 "True" 2 "Error" 3 "Not Available";
VAL_ 2566910503 FI4_DrvlnMomentaryLeft 0 "False" 1 "True" 2 "Error" 3 "Not Available";
VAL_ 2566910503 FI4_BrakeLightOutput 0 "Output Active" 1 "Output Inactive" 2 "Error" 3 "Not Available";
VAL_ 2566910503 FI4_FogLightInput 0 "Input HIGH" 1 "Input LOW" 2 "Error" 3 "Not Available";
VAL_ 2566910503 FI4_HazardLightOutput 0 "Output Active" 1 "Output Inactive" 2 "Error" 3 "Not Available";
VAL_ 2566910503 FI4_HazardSWInput 0 "Input HIGH" 1 "Input LOW" 2 "Error" 3 "Not Available";
VAL_ 2566910503 FI4_HeatGripDecSW 0 "Active" 1 "Inactive" 2 "Error" 3 "Not Available";
VAL_ 2566910503 FI4_HeatGripIncSW 0 "Active" 1 "Inactive" 2 "Error" 3 "Not Available";
VAL_ 2566910503 FI4_HighBeamOutput 0 "Output Active" 1 "Output Inactive" 2 "Error" 3 "Not Available";
VAL_ 2566910503 FI4_HornInput 0 "Input HIGH" 1 "Input LOW" 2 "Error" 3 "Not Available";
VAL_ 2566910503 FI4_HornOutput 0 "Output Active" 1 "Output Inactive" 2 "Error" 3 "Not Available";
VAL_ 2566910503 FI4_LeftFogLightOutput 0 "Output Active" 1 "Output Inactive" 2 "Error" 3 "Not Available";
VAL_ 2566910503 FI4_LFTurnSignalOutput 0 "Output Active" 1 "Output Inactive" 2 "Error" 3 "Not Available";
VAL_ 2566910503 FI4_LockInput 0 "Input HIGH" 1 "Input LOW" 2 "Error" 3 "Not Available";
VAL_ 2566910503 FI4_LowBeamOutput 0 "Output Active" 1 "Output Inactive" 2 "Error" 3 "Not Available";
VAL_ 2566910503 FI4_LowHighBeamInput 0 "Input HIGH" 1 "Input LOW" 2 "Error" 3 "Not Available";
VAL_ 2566910503 FI4_LRTurnSignalOutput 0 "Output Active" 1 "Output Inactive" 2 "Error" 3 "Not Available";
VAL_ 2566910503 FI4_pOperatorButton1 0 "Active" 1 "Inactive" 2 "Error" 3 "Not Available";
VAL_ 2566910503 FI4_RFTurnSignalOutput 0 "Output Active" 1 "Output Inactive" 2 "Error" 3 "Not Available";
VAL_ 2566910503 FI4_RightFogLightOutput 0 "Output Active" 1 "Output Inactive" 2 "Error" 3 "Not Available";
VAL_ 2566910503 FI4_RRTurnSignalOutput 0 "Output Active" 1 "Output Inactive" 2 "Error" 3 "Not Available";
VAL_ 2566910503 FI4_SecondaryAirValveCmd 0 "Output Active" 1 "Output Inactive" 2 "Error" 3 "Not Available";
VAL_ 2566910503 FI4_SecondaryAirValveOut 0 "Output Active" 1 "Output Inactive" 2 "Error" 3 "Not Available";
VAL_ 2566910503 FI4_TailLightOutput 0 "Output Active" 1 "Output Inactive" 2 "Error" 3 "Not Available";
VAL_ 2566910503 FI4_UnlockInput 0 "Input HIGH" 1 "Input LOW" 2 "Error" 3 "Not Available";
VAL_ 2566910503 FI4_WindshieldSWDownInput 0 "Input HIGH" 1 "Input LOW" 2 "Error" 3 "Not Available";
VAL_ 2566910503 FI4_WindshieldSWUpInput 0 "Input HIGH" 1 "Input LOW" 2 "Error" 3 "Not Available";
VAL_ 2566910503 FI4_pOperatorButton2 0 "Active" 1 "Inactive" 2 "Error" 3 "Not Available";
VAL_ 2566910759 FI3_OilPressSwIn 0 "Input High" 1 "Input Low" 2 "Error" 3 "Not Available";
VAL_ 2566910759 FI3_BrkSw2In 0 "Input High" 1 "Input Low" 2 "Error" 3 "Not Available";
VAL_ 2566910759 FI3_CruiseCtrlResumeOut 0 "Active" 1 "Inactive" 2 "Error" 3 "Not Available";
VAL_ 2566910759 FI3_CruiseCtrlResumeIn 0 "Active" 1 "Inactive" 2 "Error" 3 "Not Available";
VAL_ 2566910759 FI3_CruiseCtrlCancelIn 0 "Active" 1 "Inactive" 2 "Error" 3 "Not Available";
VAL_ 2566910759 FI3_TetherSwStatus 0 "Active" 1 "Inactive" 2 "Error" 3 "Not Available";
VAL_ 2566910759 FI3_DriveMode1Input 0 "Active" 1 "Inactive" 2 "Error" 3 "Not Available";
VAL_ 2566910759 FI3_DriveMode2Input 0 "Active" 1 "Inactive" 2 "Error" 3 "Not Available";
VAL_ 2566910759 FI3_DriveMode3Input 0 "Active" 1 "Inactive" 2 "Error" 3 "Not Available";
VAL_ 2566910759 FI3_DriverMode4Input 0 "Active" 1 "Inactive" 2 "Error" 3 "Not Available";
VAL_ 2566910759 FI3_DriverMode1Output 0 "Active" 1 "Inactive" 2 "Error" 3 "Not Available";
VAL_ 2566910759 FI3_DriverMode2Output 0 "Active" 1 "Inactive" 2 "Error" 3 "Not Available";
VAL_ 2566910759 FI3_DriverMode3Output 0 "Active" 1 "Inactive" 2 "Error" 3 "Not Available";
VAL_ 2566910759 FI3_DriverMode4Ouput 0 "Active" 1 "Inactive" 2 "Error" 3 "Not Available";
VAL_ 2566910759 FI3_PTOModeInput 0 "Active" 1 "Inactive" 2 "Error" 3 "Not Available";
VAL_ 2566910759 FI3_PTOModeOutput 0 "Active" 1 "Inactive" 2 "Error" 3 "Not Available";
VAL_ 2566910759 FI3_DriversNetEngagement 0 "Engage" 1 "Disengage" 2 "Error" 3 "Unavailable";
VAL_ 2566910759 FI3_DriversSeatbeltEngagement 0 "Engage" 1 "Disengage" 2 "Error" 3 "Unavailable";
VAL_ 2566910759 FI3_TiltLockInput 0 "Active" 1 "Inactive" 2 "Error" 3 "Not Available";
VAL_ 2566910759 FI3_WorkGroupLockInput 0 "Active" 1 "Inactive" 2 "Error" 3 "Not Available";
VAL_ 2566910759 FI3_OperatorPresenceInput 0 "Active" 1 "Inactive" 2 "Error" 3 "Not Available";
VAL_ 2566910759 FI3_WorkGroupLockOutput 0 "Active" 1 "Inactive" 2 "Error" 3 "Not Available";
VAL_ 2566910759 FI3_OperatorPresenceOutput 0 "Active" 1 "Inactive" 2 "Error" 3 "Not Available";
VAL_ 2566910759 FI3_FootOnCruiseInput 0 "Active" 1 "Inactive" 2 "Error" 3 "Not Available";
VAL_ 2566910759 FI3_CruiseInput 0 "Active" 1 "Inactive" 2 "Error" 3 "Not Available";
VAL_ 2566910759 FI3_TredalInput 0 "Active" 1 "Inactive" 2 "Error" 3 "Not Available";
VAL_ 2566910759 FI3_CruiseSpeedInput 0 "Active" 1 "Inactive" 2 "Error" 3 "Not Available";
VAL_ 2566910759 FI3_FootOnCruiseOutput 0 "Active" 1 "Inactive" 2 "Error" 3 "Not Available";
VAL_ 2566910759 FI3_CruiseOutput 0 "Active" 1 "Inactive" 2 "Error" 3 "Not Available";
VAL_ 2566910759 FI3_CruiseControltoSetSpeed 0 "Active" 1 "Inactive" 2 "Error" 3 "Not Available";
VAL_ 2566910759 FI3_WorkModeInput 0 "Active" 1 "Inactive" 2 "Error" 3 "Not Available";
VAL_ 2566910759 FI3_TiltLockOutput 0 "Active" 1 "Inactive" 2 "Error" 3 "Not Available";
VAL_ 2566911015 FI2_ThrttlBdyInitLrnValSave 0 "False" 1 "True" 2 "Error" 3 "Not Available";
VAL_ 2566911015 FI2_ThrttlBdyInitLearnSuccess 0 "False" 1 "True" 2 "Error" 3 "Not Available";
VAL_ 2566911015 FI2_ThrottleLimpHomeOpCondition 0 "Active" 1 "Inactive" 2 "Error" 3 "Not Available";
VAL_ 2566911015 FI2_SystemOnInput 0 "Input High" 1 "Input Low" 2 "Error" 3 "Not Available";
VAL_ 2566911015 FI2_SftyFuelCutoffCndn 0 "Active" 1 "Inactive" 2 "Error" 3 "Not Available";
VAL_ 2566911015 FI2_RvrsblInjCutoffCndn 0 "Active" 1 "Inactive" 2 "Error" 3 "Not Available";
VAL_ 2566911015 FI2_PTOEngagementStatus 0 "Active" 1 "Inactive" 2 "Error" 3 "Not Available";
VAL_ 2566911015 FI2_ParkBrakeSwitchIn 0 "Input High" 1 "Input Low" 2 "Error" 3 "Not Available";
VAL_ 2566911015 FI2_NeutralSwitchIn 0 "Input High" 1 "Input Low" 2 "Error" 3 "Not Available";
VAL_ 2566911015 FI2_IrrvrsblInjCutoffCndn 0 "Active" 1 "Inactive" 2 "Error" 3 "Not Available";
VAL_ 2566911015 FI2_ETCFncnMonitor 0 "Active" 1 "Inactive" 2 "Error" 3 "Not Available";
VAL_ 2566911015 FI2_ADCOutput 0 "Active" 1 "Inactive" 2 "Error" 3 "Not Available";
VAL_ 2566911015 FI2_RearDiffLockOutput 0 "Active" 1 "Inactive" 2 "Error" 3 "Not Available";
VAL_ 2566911015 FI2_AWDOutput 0 "Active" 1 "Inactive" 2 "Error" 3 "Not Available";
VAL_ 2566911015 FI2_BrakeSwitchInput 0 "Input High" 1 "Input Low" 2 "Error" 3 "Not Available";
VAL_ 2566911015 FI2_ADCSwitchInput 0 "Input High" 1 "Input Low" 2 "Error" 3 "Not Available";
VAL_ 2566911015 FI2_TurfModeInput 0 "Input High" 1 "Input Low" 2 "Error" 3 "Not Available";
VAL_ 2566911015 FI2_AWDSwitchInput 0 "Input High" 1 "Input Low" 2 "Error" 3 "Not Available";
VAL_ 2566911015 FI2_ReverseSwitchInput 0 "Input High" 1 "Input Low" 2 "Error" 3 "Not Available";
VAL_ 2566911015 FI2_ReverseLimitSwitchInput 0 "Input High" 1 "Input Low" 2 "Error" 3 "Not Available";
VAL_ 2566911015 FI2_ForwardLimitSwitchInput 0 "Input High" 1 "Input Low" 2 "Error" 3 "Not Available";
VAL_ 2566911015 FI2_EngineDirection 0 "Input High" 1 "Input Low" 2 "Error" 3 "Not Available";
VAL_ 2566911015 FI2_RevSpeedLimitOverrideInput 0 "Input High" 1 "Input Low" 2 "Error" 3 "Not Available";
VAL_ 2566911015 FI2_ReverseOverspeedSignal 0 "Input High" 1 "Input Low" 2 "Error" 3 "Not Available";
VAL_ 2566911015 FI2_RightTurnSignalInput 0 "Input High" 1 "Input Low" 2 "Error" 3 "Not Available";
VAL_ 2566911015 FI2_LeftTurnSignalInput 0 "Input High" 1 "Input Low" 2 "Error" 3 "Not Available";
VAL_ 2566911015 FI2_KickstandSwitchInput 0 "Input High" 1 "Input Low" 2 "Error" 3 "Not Available";
VAL_ 2566911015 FI2_ReflashEnableInputSignal 0 "Input High" 1 "Input Low" 2 "Error" 3 "Not Available";
VAL_ 2566911015 FI2_TPSLearnInputSignal 0 "Input High" 1 "Input Low" 2 "Error" 3 "Not Available";
VAL_ 2566911015 FI2_LowRangeSwitchInput 0 "Active" 1 "Inactive" 2 "Error" 3 "Not Available";
VAL_ 2566911015 FI2_ReverseMotorDriveInput 0 "Input High" 1 "Input Low" 2 "Error" 3 "Not Available";
VAL_ 2566911271 FI1_FuelPullSolenoidStatus 0 "Active" 1 "Inactive" 2 "Error" 3 "Not Available";
VAL_ 2566911271 FI1_ClutchSwitchInput2 0 "Active" 1 "Inactive" 2 "Error" 3 "Not Available";
VAL_ 2566911271 FI1_FuelPumpDriverCkt 0 "Active" 1 "Inactive" 2 "Error" 3 "Not Available";
VAL_ 2566911271 FI1_RolloverSwitch 0 "Active" 1 "Inactive" 2 "Error" 3 "Not Available";
VAL_ 2566911271 FI1_CrankSensorSignal 0 "Present" 1 "Absent" 2 "Error" 3 "Not Available";
VAL_ 2566911271 FI1_CamSensorSignal 0 "Present" 1 "Absent" 2 "Error" 3 "Not Available";
VAL_ 2566911271 FI1_RPMLimitActive 0 "Active" 1 "Inactive" 2 "Error" 3 "Not Available";
VAL_ 2566911271 FI1_IdleSwitch 0 "Active" 1 "Inactive" 2 "Error" 3 "Not Available";
VAL_ 2566911271 FI1_CycleSynchro 0 "Sync" 1 "No-Sync" 2 "Error" 3 "Not Available";
VAL_ 2566911271 FI1_IdleSpeedControlStatus 0 "Active" 1 "Inactive" 2 "Error" 3 "Not Available";
VAL_ 2566911271 FI1_IgnitionSwitchInput 0 "Input High" 1 "Input Low" 2 "Error" 3 "Not Available";
VAL_ 2566911271 FI1_RunStopSwitchInput 0 "Input High" 1 "Input Low" 2 "Error" 3 "Not Available";
VAL_ 2566911271 FI1_StartSwitchInput 0 "Input High" 1 "Input Low" 2 "Error" 3 "Not Available";
VAL_ 2566911271 FI1_ThrottleSafetySwInput 0 "Input High" 1 "Input Low" 2 "Error" 3 "Not Available";
VAL_ 2566911271 FI1_FanRelayOutput 0 "Active" 1 "Inactive" 2 "Error" 3 "Not Available";
VAL_ 2566911271 FI1_IntercoolerFanOutput 0 "Active" 1 "Inactive" 2 "Error" 3 "Not Available";
VAL_ 2566911271 FI1_ReverseAlarmOutput 0 "Active" 1 "Inactive" 2 "Error" 3 "Not Available";
VAL_ 2566911271 FI1_MainRelayOutput 0 "Active" 1 "Inactive" 2 "Error" 3 "Not Available";
VAL_ 2566911271 FI1_StartSolenoidOutput 0 "Active" 1 "Inactive" 2 "Error" 3 "Not Available";
VAL_ 2566911271 FI1_IgnitionRelayOutput 0 "Active" 1 "Inactive" 2 "Error" 3 "Not Available";
VAL_ 2566911271 FI1_ChassisRelayOutput 0 "Active" 1 "Inactive" 2 "Error" 3 "Not Available";
VAL_ 2566911271 FI1_StarterEnableOutput 0 "Active" 1 "Inactive" 2 "Error" 3 "Not Available";
VAL_ 2566911271 FI1_ExhaustValveOutput 0 "Active" 1 "Inactive" 2 "Error" 3 "Not Available";
VAL_ 2566911271 FI1_BatteryChargeRelayOutput 0 "Active" 1 "Inactive" 2 "Error" 3 "Not Available";
VAL_ 2566911271 FI1_HeaterAccRelay 0 "Active" 1 "Inactive" 2 "Error" 3 "Not Available";
VAL_ 2566911271 FI1_ClutchSwitchInput 0 "Input High" 1 "Input Low" 2 "Error" 3 "Not Available";
VAL_ 2566911271 FI1_MILLampOutput 0 "Active" 1 "Inactive" 2 "Error" 3 "Not Available";
VAL_ 2566911271 FI1_OverTempLampOutput 0 "Active" 1 "Inactive" 2 "Error" 3 "Not Available";
VAL_ 2566911271 FI1_KnockDetLampOutput 0 "Active" 1 "Inactive" 2 "Error" 3 "Not Available";
VAL_ 2566911271 FI1_ElecOilPumpDrvrCirc 0 "Active" 1 "Inactive" 2 "Error" 3 "Not Available";
VAL_ 2566908427 DL17_ABS_Pump_Command 0 "Active" 1 "Inactive" 2 "Error" 3 "NotAvailable";
VAL_ 2566908427 DL17_Brake_Sw_Status 0 "Active" 1 "Inactive" 2 "Error" 3 "NotAvailable";
VAL_ 2566908427 DL17_ABS_Failsafe_Relay 0 "Active" 1 "Inactive" 2 "Error" 3 "NotAvailable";
VAL_ 2566908427 DL17_ABS_Evac_Fill 0 "Success" 1 "Failure" 2 "Error" 3 "NotAvailable";
VAL_ 2566908427 DL17_RedBrakeLamp 0 "Active" 1 "Inactive";
VAL_ 2566908427 DL17_ABSFaultLamp 0 "Active" 1 "Inactive";
VAL_ 2566908427 DL17_TCSDisabledLamp 0 "Active" 1 "Inactive";
VAL_ 2566908427 DL17_ESCDisabledLamp 0 "Active" 1 "Inactive";
VAL_ 2566908427 DL17_ESCFaultLampFlashing 0 "Active" 1 "Inactive";
VAL_ 2566908427 DL17_ESCFaultLampSolid 0 "Active" 1 "Inactive";
VAL_ 2566908427 DL17_TorqueRequestedtoECM 0 "Active" 1 "Inactive";
VAL_ 2566908427 DL17_TractionCtrlOverrideSwitch 0 "Active" 1 "Inactive" 2 "Reserved" 3 "Don't care";
VAL_ 2566907392 DL_O2SensorA1 0 "Absent" 1 "Present";
VAL_ 2566907392 DL_O2SensorA1Condition 0 "Lean" 1 "Rich";
VAL_ 2566907392 DL_O2SensorA1Status 0 "Inactive" 1 "Active";
VAL_ 2566907392 DL_ClosedLoopFuelControl 0 "Inactive" 1 "Active";
VAL_ 2566906624 DL_MATSensor 0 "Absent" 1 "Present";
VAL_ 2566906368 DL_ETCPresent 0 "False" 1 "True";
VAL_ 2566906368 DL_ETCHbridgeCurrentDirection 0 "Closes" 1 "Opens";
VAL_ 2566906368 DL_MinPositionLearningPending 0 "False" 1 "True";
VAL_ 2566906368 DL_GovPresent 0 "Absent" 1 "Present";
VAL_ 2566906112 DL_BaroSensorPresent 0 "False" 1 "True";
VAL_ 2566905344 DL_OilLifeMonitorEnabled 0 "False" 1 "True";
VAL_ 2566905344 DL_ChangeOilNow 0 "False" 1 "True";
VAL_ 2566905344 DL_ChangeOilSoon 0 "False" 1 "True";
VAL_ 2566904064 DL_CauseforRPMReduce 0 "True" 1 "False";
VAL_ 2566904064 DL_NoRevLimInLastSec 0 "False" 1 "True";
VAL_ 2566904064 DL_GovernorPresent 0 "Absent" 1 "Present";
VAL_ 2566904064 DL_SlowMode 0 "Inactive" 1 "Active";
VAL_ 2566903808 DL_CanisterPurgeSystemPresent 0 "False" 1 "True";
VAL_ 2566903552 DL_FailedDTCTestThisIgnCycle 0 "False" 1 "True";
VAL_ 2566903552 DL_HistoryDataCorrupted 0 "False" 1 "True";
VAL_ 2566903296 DL_FanDriver 0 "Disabled" 1 "Enabled";
VAL_ 2566902784 DL_CloseThrottleIdleControlMode 0 "Inactive" 1 "Active";
VAL_ 2566902784 DL_IACControlofRPM 0 "Inactive" 1 "Active";
VAL_ 2566902784 DL_LoadAnticipate1 0 "Disabled" 1 "Enabled";
VAL_ 2566902784 DL_LoadAnticipate2 0 "Disabled" 1 "Enabled";
VAL_ 2566902528 DL_FiringMode 0 "Individual" 1 "Paired";
VAL_ 2566902528 DL_KnockMonitoring 0 "Inactive" 1 "Active";
VAL_ 2566902528 DL_KnockPresentInLastSec 0 "False" 1 "True";
VAL_ 2566902528 DL_FuelDetonationControlMode 0 "Inactive" 1 "Active";
VAL_ 2566902528 DL_OctaneRatingStatus 0 "Disabled" 1 "Enabled";
VAL_ 2566902528 DL_OctaneUpdate 0 "Not in Progress" 1 "In";
VAL_ 2566901504 DL_CamXSensor 0 "Absent" 1 "Present";
VAL_ 2566901504 DL_CamXPhaser 0 "Absent" 1 "Present";
VAL_ 2566901248 DL_CamWSensor 0 "Absent" 1 "Present";
VAL_ 2566901248 DL_CamWPhaser 0 "Absent" 1 "Present";
VAL_ 2566877463 pVolumeUnitsSelected 0 "Gallons" 1 "Liters" 2 "Imperial Gallons" 3 "Reserved" 4 "Reserved" 5 "Reserved" 6 "Error" 7 "Not Available";
VAL_ 2566877463 pTimeUnitsSelected 0 "12 Hour" 1 "24 Hour" 2 "Error" 3 "Not Available";
VAL_ 2566877463 pTemperatureUnitsSelected 0 "Farenheit" 1 "Celsius" 2 "Error" 3 "Not Avaialable";
VAL_ 2566877463 pPressureUnitsSelected 0 "Pounds Per Square Inch (PSI)" 1 "Kilopascal (kPa)" 2 "Error" 3 "Not Available";
VAL_ 2566877463 pDistanceUnitsSelected 0 "Miles" 1 "Kilometers" 2 "Error" 3 "Not Available";
VAL_ 2566877463 pTPMSLearningStatus 0 "Not Started" 1 "Request to start" 2 "Learning Left Front" 3 "Learning Right Front" 4 "Learning Left Rear" 5 "Learning Right Rear" 6 "Learning successfully completed" 13 "Request to end learning" 14 "Error - Failed Learning" 15 "Not Available";
VAL_ 2566877463 pDisplayStatus 0 "Info cant overide to full screen" 1 "User requested full screen" 2 "Info can overide to full screen" 14 "Info data is not shown" 15 "Not Available";
VAL_ 2566876711 pEngineOilPressureStatus 0 "Not OK; Pressure is too low" 1 "OK; Pressure is above minimum" 2 "Error" 3 "Not Available";
VAL_ 2566876711 pHydraulicOilPressureStatus 0 "Not OK; Pressure too low" 1 "OK; Pressure above minimum" 2 "Error" 3 "Not Available";
VAL_ 2566876711 pHydraulicOilTempStatus 0 "Not OK; Temp too high" 1 "OK; Temp is below max" 2 "Error" 3 "Not Available";
VAL_ 2633984551 pHeatedGripEnable 0 "Disabled (Not installed)" 1 "Enabled (Installed)" 2 "Error Indicator" 3 "Description for the value '3'";
VAL_ 2633984551 pSideStandStatus 0 "Side Stand Down" 1 "Side Stand Up" 2 "Error Indicator" 3 "Not Available";
VAL_ 2633984551 pTetherSwitchStatus 0 "Tether SW Closed (connected)" 1 "Tether SW Open (disconnected)" 2 "Error" 3 "Not Available";
VAL_ 2633984551 pLowFuelIndicatorStatus 0 "Low Fuel Indicator Off" 1 "Low Fuel Indicator On" 2 "Error" 3 "Not Available";
VAL_ 2633984551 pOperatorNotInOperatingStation 0 "Operator In OperatorStation" 1 "Operator Not In OperatorStation" 2 "Error" 3 "Description for the value '3'";
VAL_ 2633984551 pParkBrakeIndicatorStatus 0 "Park Brake Indicator Off" 1 "Park Brake Indicator On (Solid)" 2 "Park Brake Indicator 1 Hz flash" 3 "Park Brake Indicator 2 Hz flash" 4 "Available for future use" 5 "Available for future use" 6 "Error Indicator" 7 "Not Available";
VAL_ 2633984551 pADCRequested 0 "ADC Mode not Requested" 1 "ADC Mode Requested" 2 "Error" 3 "Not Available";
VAL_ 2633984551 pAWDModeRequested 0 "AWD Mode not Requested" 1 "AWD Mode Requested" 2 "Error" 3 "Not Available";
VAL_ 2633984551 pRWDModeRequested 0 "RWD Mode not Requested" 1 "RWD Mode Requested" 2 "Error" 3 "Not Available";
VAL_ 2633984551 pTurfModeRequested 0 "Turf Mode not Requested" 1 "Turf Mode Requested" 2 "Error" 3 "Not Available";
VAL_ 2633984551 pADCStatus 0 "ADC Actuator Not Engaged" 1 "ADC Actuator Engaged" 2 "Error" 3 "Not available";
VAL_ 2633984551 pTreadleNeutralStatus 0 "Treadle Neutral Not Engaged" 1 "Treadle Neutral Engaged" 2 "Error" 3 "Not Available";
VAL_ 2633984551 pTreadleReverseStatus 0 "Treadle Reverse Not Engaged" 1 "Treadle Reverse Engaged" 2 "Error" 3 "Not Available";
VAL_ 2633984551 pSecurityLightStatus 0 "Off" 1 "On (Solid)" 2 "Error (Flashing)" 3 "Not Available";
VAL_ 2633984551 pHighBeamIndicatorStatus 0 "Indicator Off" 1 "Indicator On" 2 "Error (Indicator Flashing)" 3 "Not Available";
VAL_ 2633984551 pCruiseControlSetStatus 0 "Cruise Not Set" 1 "Cruise Set" 2 "Error (Lamp Flashing)" 3 "Not Available";
VAL_ 2633984551 pSeatBeltIndicatorStatus 0 "Seat_Belt_Indicator_Off" 1 "Seat_Belt_Indicator_On_Solid" 2 "Seat_Belt_Indicator_1Hz" 3 "Seat_Belt_Indicator_2Hz" 4 "Future1" 5 "Future2" 6 "Error" 7 "Not_Available";
VAL_ 2432656679 pOperatorButton29 0 "Button Not Pressed" 1 "Button Pressed" 2 "Error" 3 "Not Available";
VAL_ 2432656679 pOperatorButton1 0 "Not Pressed" 1 "Pressed" 2 "Error" 3 "Not Available";
VAL_ 2432656679 pOperatorButton2 0 "Active" 1 "Inactive" 2 "Error" 3 "Not Available";
VAL_ 2432656679 pOperatorButton3 0 "Not Pressed" 1 "Pressed" 2 "Error" 3 "Not Available";
VAL_ 2432656679 pOperatorButton4 0 "Not Pressed" 1 "Pressed" 2 "Error" 3 "Not Available";
VAL_ 2432656679 pOperatorButton5 0 "Not Pressed" 1 "Pressed" 2 "Error" 3 "Not Available";
VAL_ 2432656679 pOperatorButton6 0 "Not Pressed" 1 "Pressed" 2 "Error" 3 "Not Available";
VAL_ 2432656679 pOperatorButton7 0 "Not Pressed" 1 "Pressed" 2 "Error" 3 "Not Available";
VAL_ 2432656679 pOperatorButton8 0 "Not Pressed" 1 "Pressed" 2 "Error" 3 "Not Available";
VAL_ 2432656679 pOperatorButton9 0 "Not Pressed" 1 "Pressed" 2 "Error" 3 "Not Available";
VAL_ 2432656679 pOperatorButton10 0 "Not Pressed" 1 "Pressed" 2 "Error" 3 "Not Available";
VAL_ 2432656679 pOperatorButton11 0 "Not Pressed" 1 "Pressed" 2 "Error" 3 "Not Available";
VAL_ 2432656679 pOperatorButton12 0 "Not Pressed" 1 "Pressed" 2 "Error" 3 "Not Available";
VAL_ 2432656679 pOperatorButton13 0 "Not Pressed" 1 "Pressed" 2 "Error" 3 "Not Available";
VAL_ 2432656679 pOperatorButton14 0 "Not Pressed" 1 "Pressed" 2 "Error" 3 "Not Available";
VAL_ 2432656679 pOperatorButton15 0 "Not Pressed" 1 "Pressed" 2 "Error" 3 "Not Available";
VAL_ 2432656679 pOperatorButton16 0 "Not Pressed" 1 "Pressed" 2 "Error" 3 "Not Available";
VAL_ 2432656679 pOperatorButton17 0 "Not Pressed" 1 "Pressed" 2 "Error" 3 "Not Available";
VAL_ 2432656679 pOperatorButton18 0 "Not Pressed" 1 "Pressed" 2 "Error" 3 "Not Available";
VAL_ 2432656679 pOperatorButton19 0 "Not Pressed" 1 "Pressed" 2 "Error" 3 "Not Available";
VAL_ 2432656679 pOperatorButton20 0 "Not Pressed" 1 "Pressed" 2 "Error" 3 "Not Available";
VAL_ 2432656679 pOperatorButton21 0 "Not Pressed" 1 "Pressed" 2 "Error" 3 "Not Available";
VAL_ 2432656679 pOperatorButton22 0 "Not Pressed" 1 "Pressed" 2 "Error" 3 "Not Available";
VAL_ 2432656679 pOperatorButton23 0 "Not Pressed" 1 "Pressed" 2 "Error" 3 "Not Available";
VAL_ 2432656679 pOperatorButton24 0 "Not Pressed" 1 "Pressed" 2 "Error" 3 "Not Available";
VAL_ 2432656679 pOperatorButton25 0 "Not Pressed" 1 "Pressed" 2 "Error" 3 "Not Available";
VAL_ 2432656679 pOperatorButton26 0 "Not Pressed" 1 "Pressed" 2 "Error" 3 "Not Available";
VAL_ 2432656679 pOperatorButton27 0 "Not Pressed" 1 "Pressed" 2 "Error" 3 "Not Available";
VAL_ 2432656679 pOperatorButton28 0 "Not Pressed" 1 "Pressed" 2 "Error" 3 "Not Available";
VAL_ 2432656679 pSideStandStatus 0 "Side Stand Down" 1 "Side Stand Up" 2 "Error Indicator" 3 "Not Available";
VAL_ 2566845479 TireLocation 0 "Front" 16 "Rear";
VAL_ 3221225472 TirePressThresholdDetection 0 "Extreme over pressure" 1 "Over pressure" 2 "No warning pressure" 3 "Under pressure" 4 "Extreme under pressure" 5 "Not defined" 6 "Error indicator" 7 "Not available";
VAL_ 3221225472 CTIWheelEndElectricalFault 0 "Ok  No Fault" 1 "Not Defined" 2 "Error" 3 "Not Supported";
VAL_ 3221225472 CTITireStatus 0 "Ok no fault" 1 "Tire leak detected" 2 "Error" 3 "Not Supported";
VAL_ 3221225472 CTIWheelSensorStatus 0 "Off / isolated from CTI Pressure Controller" 1 "On tire is polled" 2 "Not Defined" 3 "Not Supported";
VAL_ 3221225472 EngTurningGearEngaged 0 "Not engaged" 1 "Engaged" 2 "Error" 3 "Not available";
